BU_:  Airbag BAP_Tester ICAS1_Gateway ICAS1_KommunikationsServer LE1 LE2 Motor_BEV Schaltbetaetigung

BU_:  Airbag BAP_Tester ICAS1_Gateway ICAS1_KommunikationsServer LE1 LE2 Motor_BEV Schaltbetaetigung

BO_ 192 EM1_01: 32 LE1
 SG_ EM1_01_CRC  : 0|8@1+ (1.000000,0.000000) [0.000000|255.000000] "" ICAS1_Gateway Motor_BEV
 SG_ EM1_01_BZ  : 8|4@1+ (1.000000,0.000000) [0.000000|15.000000] "" ICAS1_Gateway Motor_BEV
 SG_ EM1_Istmodus  : 12|4@1+ (1.000000,0.000000) [0.000000|15.000000] "" ICAS1_Gateway Motor_BEV
 SG_ EM1_IstMoment  : 16|12@1+ (0.500000,-1023.000000) [-1023.000000|1023.500000] "Unit_NewtoMeter" ICAS1_Gateway Motor_BEV
 SG_ EM1_Moment_AR_Eingriff  : 28|12@1+ (0.500000,-1023.000000) [-1023.000000|1023.500000] "Unit_NewtoMeter" ICAS1_Gateway Motor_BEV
 SG_ EM1_IstDrehzahl  : 40|15@1+ (1.000000,-10000.000000) [-10000.000000|22765.000000] "Unit_MinutInver" ICAS1_Gateway Motor_BEV
 SG_ EM1_AR_aktiv  : 55|1@1+ (1.000000,0.000000) [0.000000|1.000000] "" ICAS1_Gateway Motor_BEV
 SG_ EM1_IstSpannung  : 56|12@1+ (0.250000,0.000000) [0.000000|1023.250000] "Unit_Volt" ICAS1_Gateway Motor_BEV
 SG_ EM1_Strom_HV  : 68|12@1+ (0.500000,-1023.000000) [-1023.000000|1023.500000] "Unit_Amper" ICAS1_Gateway Motor_BEV
 SG_ EM1_Max_Moment  : 80|11@1+ (1.000000,-1023.000000) [-1023.000000|1022.000000] "Unit_NewtoMeter" ICAS1_Gateway Motor_BEV
 SG_ EM1_ErwGrenzen_aktiv  : 91|1@1+ (1.000000,0.000000) [0.000000|1.000000] "" ICAS1_Gateway Motor_BEV
 SG_ EM1_Min_Moment  : 92|11@1+ (1.000000,-1023.000000) [-1023.000000|1022.000000] "Unit_NewtoMeter" ICAS1_Gateway Motor_BEV
 SG_ EM1_Fehler_ElAntriebAbschaltung  : 103|1@1+ (1.000000,0.000000) [0.000000|1.000000] "" ICAS1_Gateway Motor_BEV
 SG_ EM1_Max_Moment_Lim  : 104|11@1+ (1.000000,-1023.000000) [-1023.000000|1022.000000] "Unit_NewtoMeter" ICAS1_Gateway Motor_BEV
 SG_ EM1_Fehler_Notabschaltung  : 115|1@1+ (1.000000,0.000000) [0.000000|1.000000] "" ICAS1_Gateway Motor_BEV
 SG_ EM1_Min_Moment_Lim  : 116|11@1+ (1.000000,-1023.000000) [-1023.000000|1022.000000] "Unit_NewtoMeter" ICAS1_Gateway Motor_BEV
 SG_ EM1_Status_DrzEingriff  : 127|2@1+ (1.000000,0.000000) [0.000000|3.000000] "" ICAS1_Gateway Motor_BEV
 SG_ EM1_Mom_DrzEingriff  : 129|11@1+ (1.000000,-1023.000000) [-1023.000000|1022.000000] "Unit_NewtoMeter" ICAS1_Gateway Motor_BEV

BO_ 2463978673 EM1_02: 32 LE1
 SG_ EM1_Status_Spgfreiheit  : 12|2@1+ (1.000000,0.000000) [0.000000|3.000000] "" Motor_BEV
 SG_ EM1_Status_EoHVL  : 14|2@1+ (1.000000,0.000000) [0.000000|3.000000] "" Motor_BEV
 SG_ EM1_Max_LeistungMech_Sockel  : 16|13@1+ (200.000000,-819000.000000) [-819000.000000|818800.000000] "Unit_Watt" Vector__XXX
 SG_ EM1_Max_Moment_Sockel  : 29|11@1+ (1.000000,-1023.000000) [-1023.000000|1022.000000] "Unit_NewtoMeter" Vector__XXX
 SG_ EM1_Min_LeistungMech_Sockel  : 40|13@1+ (200.000000,-819000.000000) [-819000.000000|818800.000000] "Unit_Watt" Vector__XXX
 SG_ EM1_Min_Moment_Sockel  : 53|11@1+ (1.000000,-1023.000000) [-1023.000000|1022.000000] "Unit_NewtoMeter" Vector__XXX
 SG_ EM1_PerfInd_MaxLeistung  : 64|10@1+ (0.200000,0.000000) [0.000000|200.000000] "Unit_PerCent" Motor_BEV
 SG_ EM1_PerfInd_MaxMoment  : 74|10@1+ (0.200000,0.000000) [0.000000|200.000000] "Unit_PerCent" Motor_BEV
 SG_ EM1_AnlernenElMotor_Anf  : 84|1@1+ (1.000000,0.000000) [0.000000|1.000000] "" Motor_BEV
 SG_ EM1_OBD_Lampe_Anf  : 85|1@1+ (1.000000,0.000000) [0.000000|1.000000] "" Motor_BEV
 SG_ EM1_Generator_Moment  : 86|10@1+ (1.000000,0.000000) [0.000000|1021.000000] "Unit_NewtoMeter" Motor_BEV
 SG_ EM1_PerfInd_Temperatur  : 96|8@1+ (0.800000,0.000000) [0.000000|200.000000] "Unit_PerCent" Motor_BEV
 SG_ EM1_MaxZul_Drehzahl  : 104|8@1+ (80.000000,0.000000) [0.000000|20240.000000] "Unit_RevPerMinute" Motor_BEV
 SG_ EM1_Min_Moment_Gesamt  : 112|11@1+ (1.000000,-1023.000000) [-1023.000000|1022.000000] "Unit_NewtoMeter" Motor_BEV
 SG_ EM1_Fehlerlampe_Anf  : 123|1@1+ (1.000000,0.000000) [0.000000|1.000000] "" Motor_BEV
 SG_ EM1_Max_Moment_Gesamt  : 124|11@1+ (1.000000,-1023.000000) [-1023.000000|1022.000000] "Unit_NewtoMeter" Motor_BEV
 SG_ EM1_Warnlampe_Anf  : 135|1@1+ (1.000000,0.000000) [0.000000|1.000000] "" Motor_BEV
 SG_ EM1_Rekuperation  : 136|15@1+ (10.000000,0.000000) [0.000000|327670.000000] "Unit_WattSecond" Motor_BEV
 SG_ EM1_Rekuperation_Ueberlauf  : 151|1@1+ (1.000000,0.000000) [0.000000|1.000000] "" Motor_BEV
 SG_ EM1_Verbrauch  : 152|15@1+ (10.000000,0.000000) [0.000000|327670.000000] "Unit_WattSecond" Motor_BEV
 SG_ EM1_Verbrauch_Ueberlauf  : 167|1@1+ (1.000000,0.000000) [0.000000|1.000000] "" Motor_BEV
 SG_ EM1_Fehler_AE  : 168|1@1+ (1.000000,0.000000) [0.000000|1.000000] "" Motor_BEV
 SG_ EM1_Fehler_Leistungsred  : 169|1@1+ (1.000000,0.000000) [0.000000|1.000000] "" Motor_BEV
 SG_ EM1_Fehler_ElAntriebFreilauf  : 170|1@1+ (1.000000,0.000000) [0.000000|1.000000] "" Motor_BEV
 SG_ EM1_PWR_SollVolumenstrom  : 171|6@1+ (0.500000,0.000000) [0.000000|30.500000] "Unit_LiterPerMinut" Motor_BEV

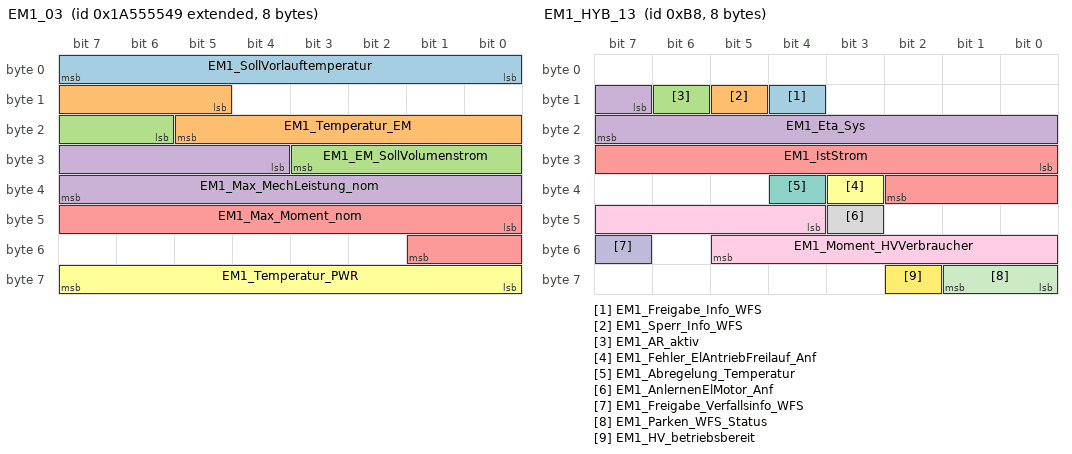
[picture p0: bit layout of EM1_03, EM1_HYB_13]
BO_ 2589283657 EM1_03: 8 LE1
 SG_ EM1_SollVorlauftemperatur  : 0|8@1+ (0.500000,-40.000000) [-40.000000|86.500000] "Unit_DegreCelsi" Motor_BEV
 SG_ EM1_Temperatur_EM  : 13|9@1+ (1.000000,-40.000000) [-40.000000|469.000000] "Unit_DegreCelsi" ICAS1_Gateway Motor_BEV
 SG_ EM1_EM_SollVolumenstrom  : 22|6@1+ (0.500000,0.000000) [0.000000|30.500000] "Unit_LiterPerMinut" Motor_BEV
 SG_ EM1_Max_MechLeistung_nom  : 28|12@1+ (200.000000,0.000000) [0.000000|818600.000000] "Unit_Watt" Motor_BEV
 SG_ EM1_Max_Moment_nom  : 40|10@1+ (1.000000,0.000000) [0.000000|1021.000000] "Unit_NewtoMeter" Motor_BEV
 SG_ EM1_Temperatur_PWR  : 56|8@1+ (1.000000,-40.000000) [-40.000000|213.000000] "Unit_DegreCelsi" ICAS1_Gateway Motor_BEV

BO_ 184 EM1_HYB_13: 8 LE1
 SG_ EM1_Freigabe_Info_WFS  : 12|1@1+ (1.000000,0.000000) [0.000000|1.000000] "" ICAS1_Gateway Motor_BEV
 SG_ EM1_Sperr_Info_WFS  : 13|1@1+ (1.000000,0.000000) [0.000000|1.000000] "" ICAS1_Gateway Motor_BEV
 SG_ EM1_AR_aktiv  : 14|1@1+ (1.000000,0.000000) [0.000000|1.000000] "" ICAS1_Gateway
 SG_ EM1_Eta_Sys  : 15|9@1+ (0.200000,0.000000) [0.000000|101.800000] "Unit_PerCent" ICAS1_Gateway
 SG_ EM1_IstStrom  : 24|11@1+ (1.000000,-1023.000000) [-1023.000000|1022.000000] "Unit_Amper" ICAS1_Gateway
 SG_ EM1_Fehler_ElAntriebFreilauf_Anf  : 35|1@1+ (1.000000,0.000000) [0.000000|1.000000] "" ICAS1_Gateway
 SG_ EM1_Abregelung_Temperatur  : 36|1@1+ (1.000000,0.000000) [0.000000|1.000000] "" ICAS1_Gateway
 SG_ EM1_AnlernenElMotor_Anf  : 43|1@1+ (1.000000,0.000000) [0.000000|1.000000] "" ICAS1_Gateway
 SG_ EM1_Moment_HVVerbraucher  : 44|10@1+ (1.000000,-511.000000) [-511.000000|511.000000] "Unit_NewtoMeter" ICAS1_Gateway
 SG_ EM1_Freigabe_Verfallsinfo_WFS  : 55|1@1+ (1.000000,0.000000) [0.000000|1.000000] "" ICAS1_Gateway Motor_BEV
 SG_ EM1_Parken_WFS_Status  : 56|2@1+ (1.000000,0.000000) [0.000000|3.000000] "" ICAS1_Gateway
 SG_ EM1_HV_betriebsbereit  : 58|1@1+ (1.000000,0.000000) [0.000000|1.000000] "" ICAS1_Gateway

BO_ 2527679712 EM1_HYB_27: 8 LE1
 SG_ EM1_RtmWarnKommunikation  : 12|3@1+ (1.000000,0.000000) [0.000000|7.000000] "" Vector__XXX
 SG_ EM1_RtmWarnUeberdrehzahl  : 15|3@1+ (1.000000,0.000000) [0.000000|7.000000] "" ICAS1_Gateway
 SG_ EM1_RtmWarnUeberstrom  : 18|3@1+ (1.000000,0.000000) [0.000000|7.000000] "" ICAS1_Gateway
 SG_ EM1_RtmWarnTempEM  : 21|3@1+ (1.000000,0.000000) [0.000000|7.000000] "" ICAS1_Gateway
 SG_ EM1_RtmWarnTempPWR  : 24|3@1+ (1.000000,0.000000) [0.000000|7.000000] "" ICAS1_Gateway

BO_ 193 EM2_01: 32 LE2
 SG_ EM2_01_CRC  : 0|8@1+ (1.000000,0.000000) [0.000000|255.000000] "" Motor_BEV
 SG_ EM2_01_BZ  : 8|4@1+ (1.000000,0.000000) [0.000000|15.000000] "" Motor_BEV
 SG_ EM2_Istmodus  : 12|4@1+ (1.000000,0.000000) [0.000000|15.000000] "" ICAS1_Gateway Motor_BEV
 SG_ EM2_IstMoment  : 16|12@1+ (0.500000,-1023.000000) [-1023.000000|1023.500000] "Unit_NewtoMeter" ICAS1_Gateway Motor_BEV
 SG_ EM2_Moment_AR_Eingriff  : 28|12@1+ (0.500000,-1023.000000) [-1023.000000|1023.500000] "Unit_NewtoMeter" Motor_BEV
 SG_ EM2_IstDrehzahl  : 40|15@1+ (1.000000,-10000.000000) [-10000.000000|22765.000000] "Unit_MinutInver" ICAS1_Gateway Motor_BEV
 SG_ EM2_AR_aktiv  : 55|1@1+ (1.000000,0.000000) [0.000000|1.000000] "" Motor_BEV
 SG_ EM2_IstSpannung  : 56|12@1+ (0.250000,0.000000) [0.000000|1023.250000] "Unit_Volt" ICAS1_Gateway Motor_BEV
 SG_ EM2_Strom_HV  : 68|12@1+ (0.500000,-1023.000000) [-1023.000000|1023.500000] "Unit_Amper" ICAS1_Gateway Motor_BEV
 SG_ EM2_Max_Moment  : 80|11@1+ (1.000000,-1023.000000) [-1023.000000|1022.000000] "Unit_NewtoMeter" Motor_BEV
 SG_ EM2_ErwGrenzen_aktiv  : 91|1@1+ (1.000000,0.000000) [0.000000|1.000000] "" Motor_BEV
 SG_ EM2_Min_Moment  : 92|11@1+ (1.000000,-1023.000000) [-1023.000000|1022.000000] "Unit_NewtoMeter" Motor_BEV
 SG_ EM2_Fehler_ElAntriebAbschaltung  : 103|1@1+ (1.000000,0.000000) [0.000000|1.000000] "" Motor_BEV
 SG_ EM2_Max_Moment_Lim  : 104|11@1+ (1.000000,-1023.000000) [-1023.000000|1022.000000] "Unit_NewtoMeter" Motor_BEV
 SG_ EM2_Fehler_Notabschaltung  : 115|1@1+ (1.000000,0.000000) [0.000000|1.000000] "" ICAS1_Gateway Motor_BEV
 SG_ EM2_Min_Moment_Lim  : 116|11@1+ (1.000000,-1023.000000) [-1023.000000|1022.000000] "Unit_NewtoMeter" Motor_BEV
 SG_ EM2_Status_DrzEingriff  : 127|2@1+ (1.000000,0.000000) [0.000000|3.000000] "" ICAS1_Gateway Motor_BEV
 SG_ EM2_Mom_DrzEingriff  : 129|11@1+ (1.000000,-1023.000000) [-1023.000000|1022.000000] "Unit_NewtoMeter" Motor_BEV

BO_ 2463978674 EM2_02: 32 LE2
 SG_ EM2_Status_Spgfreiheit  : 12|2@1+ (1.000000,0.000000) [0.000000|3.000000] "" Motor_BEV
 SG_ EM2_Status_EoHVL  : 14|2@1+ (1.000000,0.000000) [0.000000|3.000000] "" Motor_BEV
 SG_ EM2_Max_LeistungMech_Sockel  : 16|13@1+ (200.000000,-819000.000000) [-819000.000000|818800.000000] "Unit_Watt" Vector__XXX
 SG_ EM2_Max_Moment_Sockel  : 29|11@1+ (1.000000,-1023.000000) [-1023.000000|1022.000000] "Unit_NewtoMeter" Vector__XXX
 SG_ EM2_Min_LeistungMech_Sockel  : 40|13@1+ (200.000000,-819000.000000) [-819000.000000|818800.000000] "Unit_Watt" Vector__XXX
 SG_ EM2_Min_Moment_Sockel  : 53|11@1+ (1.000000,-1023.000000) [-1023.000000|1022.000000] "Unit_NewtoMeter" Vector__XXX
 SG_ EM2_PerfInd_MaxLeistung  : 64|10@1+ (0.200000,0.000000) [0.000000|200.000000] "Unit_PerCent" Motor_BEV
 SG_ EM2_PerfInd_MaxMoment  : 74|10@1+ (0.200000,0.000000) [0.000000|200.000000] "Unit_PerCent" Motor_BEV
 SG_ EM2_AnlernenElMotor_Anf  : 84|1@1+ (1.000000,0.000000) [0.000000|1.000000] "" Motor_BEV
 SG_ EM2_OBD_Lampe_Anf  : 85|1@1+ (1.000000,0.000000) [0.000000|1.000000] "" Motor_BEV
 SG_ EM2_Generator_Moment  : 86|10@1+ (1.000000,0.000000) [0.000000|1021.000000] "Unit_NewtoMeter" Motor_BEV
 SG_ EM2_PerfInd_Temperatur  : 96|8@1+ (0.800000,0.000000) [0.000000|200.000000] "Unit_PerCent" Motor_BEV
 SG_ EM2_MaxZul_Drehzahl  : 104|8@1+ (80.000000,0.000000) [0.000000|20240.000000] "Unit_RevPerMinute" Motor_BEV
 SG_ EM2_Min_Moment_Gesamt  : 112|11@1+ (1.000000,-1023.000000) [-1023.000000|1022.000000] "Unit_NewtoMeter" Motor_BEV
 SG_ EM2_Fehlerlampe_Anf  : 123|1@1+ (1.000000,0.000000) [0.000000|1.000000] "" Motor_BEV
 SG_ EM2_Max_Moment_Gesamt  : 124|11@1+ (1.000000,-1023.000000) [-1023.000000|1022.000000] "Unit_NewtoMeter" Motor_BEV
 SG_ EM2_Warnlampe_Anf  : 135|1@1+ (1.000000,0.000000) [0.000000|1.000000] "" Motor_BEV
 SG_ EM2_Rekuperation  : 136|15@1+ (10.000000,0.000000) [0.000000|327670.000000] "Unit_WattSecond" Motor_BEV
 SG_ EM2_Rekuperation_Ueberlauf  : 151|1@1+ (1.000000,0.000000) [0.000000|1.000000] "" Motor_BEV
 SG_ EM2_Verbrauch  : 152|15@1+ (10.000000,0.000000) [0.000000|327670.000000] "Unit_WattSecond" Motor_BEV
 SG_ EM2_Verbrauch_Ueberlauf  : 167|1@1+ (1.000000,0.000000) [0.000000|1.000000] "" Motor_BEV
 SG_ EM2_Fehler_AE  : 168|1@1+ (1.000000,0.000000) [0.000000|1.000000] "" Motor_BEV
 SG_ EM2_Fehler_Leistungsred  : 169|1@1+ (1.000000,0.000000) [0.000000|1.000000] "" Motor_BEV
 SG_ EM2_Fehler_ElAntriebFreilauf  : 170|1@1+ (1.000000,0.000000) [0.000000|1.000000] "" Motor_BEV
 SG_ EM2_PWR_SollVolumenstrom  : 171|6@1+ (0.500000,0.000000) [0.000000|30.500000] "Unit_LiterPerMinut" Motor_BEV

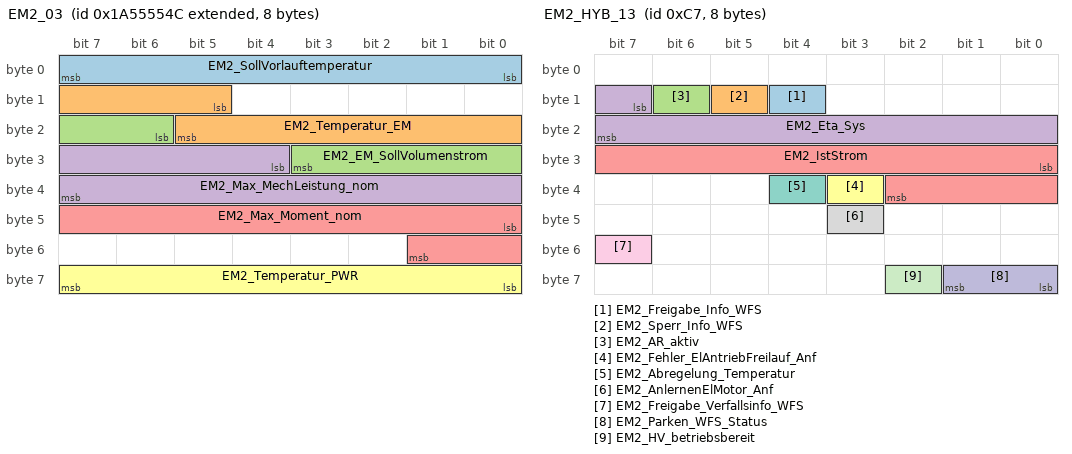
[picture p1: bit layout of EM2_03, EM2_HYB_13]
BO_ 2589283660 EM2_03: 8 LE2
 SG_ EM2_SollVorlauftemperatur  : 0|8@1+ (0.500000,-40.000000) [-40.000000|86.500000] "Unit_DegreCelsi" Motor_BEV
 SG_ EM2_Temperatur_EM  : 13|9@1+ (1.000000,-40.000000) [-40.000000|469.000000] "Unit_DegreCelsi" ICAS1_Gateway Motor_BEV
 SG_ EM2_EM_SollVolumenstrom  : 22|6@1+ (0.500000,0.000000) [0.000000|30.500000] "Unit_LiterPerMinut" Motor_BEV
 SG_ EM2_Max_MechLeistung_nom  : 28|12@1+ (200.000000,0.000000) [0.000000|818600.000000] "Unit_Watt" Motor_BEV
 SG_ EM2_Max_Moment_nom  : 40|10@1+ (1.000000,0.000000) [0.000000|1021.000000] "Unit_NewtoMeter" Motor_BEV
 SG_ EM2_Temperatur_PWR  : 56|8@1+ (1.000000,-40.000000) [-40.000000|213.000000] "Unit_DegreCelsi" ICAS1_Gateway Motor_BEV

BO_ 199 EM2_HYB_13: 8 LE2
 SG_ EM2_Freigabe_Info_WFS  : 12|1@1+ (1.000000,0.000000) [0.000000|1.000000] "" ICAS1_Gateway Motor_BEV
 SG_ EM2_Sperr_Info_WFS  : 13|1@1+ (1.000000,0.000000) [0.000000|1.000000] "" ICAS1_Gateway Motor_BEV
 SG_ EM2_AR_aktiv  : 14|1@1+ (1.000000,0.000000) [0.000000|1.000000] "" ICAS1_Gateway
 SG_ EM2_Eta_Sys  : 15|9@1+ (0.200000,0.000000) [0.000000|101.800000] "Unit_PerCent" ICAS1_Gateway
 SG_ EM2_IstStrom  : 24|11@1+ (1.000000,-1023.000000) [-1023.000000|1022.000000] "Unit_Amper" ICAS1_Gateway
 SG_ EM2_Fehler_ElAntriebFreilauf_Anf  : 35|1@1+ (1.000000,0.000000) [0.000000|1.000000] "" ICAS1_Gateway
 SG_ EM2_Abregelung_Temperatur  : 36|1@1+ (1.000000,0.000000) [0.000000|1.000000] "" ICAS1_Gateway
 SG_ EM2_AnlernenElMotor_Anf  : 43|1@1+ (1.000000,0.000000) [0.000000|1.000000] "" ICAS1_Gateway
 SG_ EM2_Freigabe_Verfallsinfo_WFS  : 55|1@1+ (1.000000,0.000000) [0.000000|1.000000] "" ICAS1_Gateway Motor_BEV
 SG_ EM2_Parken_WFS_Status  : 56|2@1+ (1.000000,0.000000) [0.000000|3.000000] "" ICAS1_Gateway
 SG_ EM2_HV_betriebsbereit  : 58|1@1+ (1.000000,0.000000) [0.000000|1.000000] "" ICAS1_Gateway

BO_ 2527679713 EM2_HYB_27: 8 LE2
 SG_ EM2_RtmWarnKommunikation  : 12|3@1+ (1.000000,0.000000) [0.000000|7.000000] "" Vector__XXX
 SG_ EM2_RtmWarnUeberdrehzahl  : 15|3@1+ (1.000000,0.000000) [0.000000|7.000000] "" ICAS1_Gateway
 SG_ EM2_RtmWarnUeberstrom  : 18|3@1+ (1.000000,0.000000) [0.000000|7.000000] "" ICAS1_Gateway
 SG_ EM2_RtmWarnTempEM  : 21|3@1+ (1.000000,0.000000) [0.000000|7.000000] "" ICAS1_Gateway
 SG_ EM2_RtmWarnTempPWR  : 24|3@1+ (1.000000,0.000000) [0.000000|7.000000] "" ICAS1_Gateway

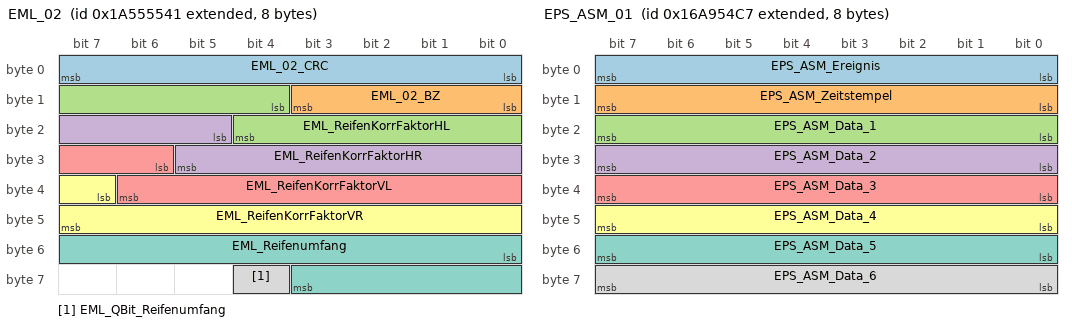
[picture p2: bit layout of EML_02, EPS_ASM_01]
BO_ 2589283649 EML_02: 8 ICAS1_Gateway
 SG_ EML_02_CRC  : 0|8@1+ (1.000000,0.000000) [0.000000|255.000000] "" Vector__XXX
 SG_ EML_02_BZ  : 8|4@1+ (1.000000,0.000000) [0.000000|15.000000] "" Vector__XXX
 SG_ EML_ReifenKorrFaktorHL  : 12|9@1+ (0.000488,0.850000) [0.850000|1.098535] "" Vector__XXX
 SG_ EML_ReifenKorrFaktorHR  : 21|9@1+ (0.000488,0.850000) [0.850000|1.098535] "" Vector__XXX
 SG_ EML_ReifenKorrFaktorVL  : 30|9@1+ (0.000488,0.850000) [0.850000|1.098535] "" Vector__XXX
 SG_ EML_ReifenKorrFaktorVR  : 39|9@1+ (0.000488,0.850000) [0.850000|1.098535] "" Vector__XXX
 SG_ EML_Reifenumfang  : 48|12@1+ (1.000000,0.000000) [0.000000|4095.000000] "Unit_MilliMeter" Motor_BEV
 SG_ EML_QBit_Reifenumfang  : 60|1@1+ (1.000000,0.000000) [0.000000|1.000000] "" Motor_BEV

BO_ 608 EML_07: 8 ICAS1_Gateway
 SG_ EML_AnzeigeGeschw  : 54|10@1+ (0.320000,0.000000) [0.000000|325.120000] "Unit_KiloMeterPerHour" Motor_BEV

BO_ 2589283751 Entfernungen_01: 8 ICAS1_KommunikationsServer
 SG_ KBI_Kilometerstand_HiRes_meter  : 32|32@1+ (1.000000,0.000000) [0.000000|4294967295.000000] "Unit_Meter" Motor_BEV

BO_ 2527679687 EPS_ASM_01: 8 ICAS1_Gateway
 SG_ EPS_ASM_Ereignis  : 0|8@1+ (1.000000,0.000000) [1.000000|254.000000] "Unit_None" Airbag
 SG_ EPS_ASM_Zeitstempel  : 8|8@1+ (0.080000,0.000000) [0.000000|20.320000] "Unit_None" Airbag
 SG_ EPS_ASM_Data_1  : 16|8@1+ (1.000000,0.000000) [0.000000|255.000000] "Unit_None" Airbag
 SG_ EPS_ASM_Data_2  : 24|8@1+ (1.000000,0.000000) [0.000000|255.000000] "Unit_None" Airbag
 SG_ EPS_ASM_Data_3  : 32|8@1+ (1.000000,0.000000) [0.000000|255.000000] "Unit_None" Airbag
 SG_ EPS_ASM_Data_4  : 40|8@1+ (1.000000,0.000000) [0.000000|255.000000] "Unit_None" Airbag
 SG_ EPS_ASM_Data_5  : 48|8@1+ (1.000000,0.000000) [0.000000|255.000000] "Unit_None" Airbag
 SG_ EPS_ASM_Data_6  : 56|8@1+ (1.000000,0.000000) [0.000000|255.000000] "Unit_None" Airbag

BO_ 258 ESC_50: 48 ICAS1_Gateway
 SG_ ESC_50_CRC  : 0|8@1+ (1.000000,0.000000) [0.000000|255.000000] "" Motor_BEV
 SG_ ESC_50_BZ  : 8|4@1+ (1.000000,0.000000) [0.000000|15.000000] "" Motor_BEV
 SG_ ESP_QBit_Gierrate  : 12|1@1+ (1.000000,0.000000) [0.000000|1.000000] "" Motor_BEV
 SG_ ESP_QBit_Laengsbeschl  : 13|1@1+ (1.000000,0.000000) [0.000000|1.000000] "" Motor_BEV
 SG_ ESP_QBit_Querb  : 14|1@1+ (1.000000,0.000000) [0.000000|1.000000] "" Motor_BEV
 SG_ ESP_Querbeschleunigung  : 16|8@1+ (0.010000,-1.270000) [-1.270000|1.270000] "Unit_ForceOfGravi" Airbag Motor_BEV
 SG_ ESP_Laengsbeschl  : 24|10@1+ (0.031250,-16.000000) [-16.000000|15.906250] "Unit_MeterPerSeconSquar" Airbag Motor_BEV
 SG_ ESC_Motorstartverzoegerung  : 34|1@1+ (1.000000,0.000000) [0.000000|1.000000] "" Vector__XXX
 SG_ ESC_SeitenwindAssistent_Eingriff  : 35|1@1+ (1.000000,0.000000) [0.000000|1.000000] "" Vector__XXX
 SG_ ESP_Anschleppstart_Freigabe  : 36|2@1+ (1.000000,0.000000) [0.000000|3.000000] "" Vector__XXX
 SG_ ESC_Unterdruckmangel_erkannt  : 38|1@1+ (1.000000,0.000000) [0.000000|1.000000] "" Vector__XXX
 SG_ ESP_Gierrate  : 40|14@1+ (0.010000,0.000000) [0.000000|163.820000] "Unit_DegreOfArcPerSecon" Airbag Motor_BEV
 SG_ ESP_VZ_Gierrate  : 54|1@1+ (1.000000,0.000000) [0.000000|1.000000] "" Airbag Motor_BEV
 SG_ ESP_Notbremsanzeige  : 55|1@1+ (1.000000,0.000000) [0.000000|1.000000] "" Vector__XXX
 SG_ ESP_SpannungsAnf  : 56|1@1+ (1.000000,0.000000) [0.000000|1.000000] "" Vector__XXX
 SG_ ESP_PLA_Abbruch  : 57|3@1+ (1.000000,0.000000) [0.000000|7.000000] "" Vector__XXX
 SG_ ESP_Status_ESP_PLA  : 60|4@1+ (1.000000,0.000000) [0.000000|15.000000] "" Vector__XXX
 SG_ ESP_QBit_Bremsdruck  : 76|1@1+ (1.000000,0.000000) [0.000000|1.000000] "" Airbag Motor_BEV
 SG_ ESP_QBit_Fahrer_bremst  : 77|1@1+ (1.000000,0.000000) [0.000000|1.000000] "" Vector__XXX
 SG_ ESP_Schwelle_Unterdruck  : 78|2@1+ (1.000000,0.000000) [0.000000|3.000000] "" Vector__XXX
 SG_ ESP_Bremsdruck  : 80|10@1+ (0.300000,-30.000000) [-30.000000|276.600000] "Unit_Bar" Motor_BEV
 SG_ ESP_Fahrer_bremst  : 90|1@1+ (1.000000,0.000000) [0.000000|1.000000] "" Vector__XXX
 SG_ ESP_Verz_TSK_aktiv  : 91|1@1+ (1.000000,0.000000) [0.000000|1.000000] "" Vector__XXX
 SG_ ESP_Lenkeingriff_ADS  : 92|1@1+ (1.000000,0.000000) [0.000000|1.000000] "" Vector__XXX
 SG_ ESP_Konsistenz_TSK  : 93|1@1+ (1.000000,0.000000) [0.000000|1.000000] "" Vector__XXX
 SG_ ESP_Bremsruck_AWV2  : 94|1@1+ (1.000000,0.000000) [0.000000|1.000000] "" Vector__XXX
 SG_ ESP_Konsistenz_AWV2  : 95|1@1+ (1.000000,0.000000) [0.000000|1.000000] "" Vector__XXX
 SG_ ECD_Fehler  : 96|1@1+ (1.000000,0.000000) [0.000000|1.000000] "" Vector__XXX
 SG_ ECD_nicht_verfuegbar  : 97|1@1+ (1.000000,0.000000) [0.000000|1.000000] "" Vector__XXX
 SG_ ESP_Status_Bremsentemp  : 98|1@1+ (1.000000,0.000000) [0.000000|1.000000] "" Vector__XXX
 SG_ ESP_Autohold_Standby  : 99|1@1+ (1.000000,0.000000) [0.000000|1.000000] "" Vector__XXX
 SG_ ESP_HDC_Standby  : 100|1@1+ (1.000000,0.000000) [0.000000|1.000000] "" Vector__XXX
 SG_ ESP_HBA_aktiv  : 101|1@1+ (1.000000,0.000000) [0.000000|1.000000] "" Vector__XXX
 SG_ ESP_Prefill_ausgeloest  : 102|1@1+ (1.000000,0.000000) [0.000000|1.000000] "" Vector__XXX
 SG_ ESP_Rueckwaertsfahrt_erkannt  : 103|1@1+ (1.000000,0.000000) [0.000000|1.000000] "" Vector__XXX
 SG_ ESP_Status_Anfahrhilfe  : 104|1@1+ (1.000000,0.000000) [0.000000|1.000000] "" Vector__XXX
 SG_ ESP_HDC_aktiv  : 105|1@1+ (1.000000,0.000000) [0.000000|1.000000] "" Vector__XXX
 SG_ ESP_StartStopp_Info  : 106|2@1+ (1.000000,0.000000) [0.000000|3.000000] "" Vector__XXX
 SG_ ESP_Eingr_HL  : 108|1@1+ (1.000000,0.000000) [0.000000|1.000000] "" Vector__XXX
 SG_ ESP_Eingr_HR  : 109|1@1+ (1.000000,0.000000) [0.000000|1.000000] "" Vector__XXX
 SG_ ESP_Eingr_VL  : 110|1@1+ (1.000000,0.000000) [0.000000|1.000000] "" Vector__XXX
 SG_ ESP_Eingr_VR  : 111|1@1+ (1.000000,0.000000) [0.000000|1.000000] "" Vector__XXX
 SG_ ESP_BKV_Unterdruck  : 112|8@1+ (4.000000,0.000000) [4.000000|1012.000000] "Unit_MilliBar" Vector__XXX
 SG_ ESP_Autohold_aktiv  : 120|1@1+ (1.000000,0.000000) [0.000000|1.000000] "" Vector__XXX
 SG_ ESP_FStatus_Anfahrhilfe  : 121|1@1+ (1.000000,0.000000) [0.000000|1.000000] "" Vector__XXX
 SG_ ESP_Verz_EPB_aktiv  : 122|1@1+ (1.000000,0.000000) [0.000000|1.000000] "" Vector__XXX
 SG_ ECD_Bremslicht  : 123|1@1+ (1.000000,0.000000) [0.000000|1.000000] "" Motor_BEV
 SG_ ESP_Verzoeg_EPB_verf  : 124|1@1+ (1.000000,0.000000) [0.000000|1.000000] "" Vector__XXX
 SG_ ESP_Status_Bremsdruck  : 125|1@1+ (1.000000,0.000000) [0.000000|1.000000] "" Vector__XXX
 SG_ ESP_Anforderung_EPB  : 126|2@1+ (1.000000,0.000000) [0.000000|3.000000] "" Vector__XXX
 SG_ ESP_ANB_CM_Rueckk_Umsetz  : 140|1@1+ (1.000000,0.000000) [0.000000|1.000000] "" Vector__XXX
 SG_ ESP_Konsistenz_ACC_Botschaft  : 141|1@1+ (1.000000,0.000000) [0.000000|1.000000] "" Vector__XXX
 SG_ ESP_Stillstandsphase_erschoepft  : 142|1@1+ (1.000000,0.000000) [0.000000|1.000000] "" Vector__XXX
 SG_ ESP_ZT_Rueckk_Umsetz  : 143|1@1+ (1.000000,0.000000) [0.000000|1.000000] "" Vector__XXX
 SG_ ESP_Tuerkontakt_Fahrertuer  : 144|1@1+ (1.000000,0.000000) [0.000000|1.000000] "" Vector__XXX
 SG_ ESP_Abrutschen_Stillstand  : 146|1@1+ (1.000000,0.000000) [0.000000|1.000000] "" Vector__XXX
 SG_ ESP_Fahrer_tritt_ZBR_Schw  : 147|1@1+ (1.000000,0.000000) [0.000000|1.000000] "" Vector__XXX
 SG_ ESP_QBit_v_ref  : 169|1@1+ (1.000000,0.000000) [0.000000|1.000000] "" Vector__XXX
 SG_ ESP_v_ref_Fahrtrichtung  : 170|2@1+ (1.000000,0.000000) [0.000000|3.000000] "" Motor_BEV
 SG_ ESC_Bremsdruckgradient  : 172|8@1+ (10.000000,0.000000) [0.000000|2500.000000] "Unit_BarPerSecon" Vector__XXX
 SG_ ESP_v_ref  : 180|12@1+ (0.125000,0.000000) [0.000000|511.500000] "Unit_KiloMeterPerHour" Airbag Motor_BEV
 SG_ ESC_Hydr_Fkt_aktiv  : 223|2@1+ (1.000000,0.000000) [0.000000|3.000000] "" Vector__XXX
 SG_ ESC_QBit_Fahrerbremswunsch  : 225|1@1+ (1.000000,0.000000) [0.000000|1.000000] "" Motor_BEV
 SG_ ESC_Fahrerbremswunsch  : 226|10@1+ (0.300000,-30.000000) [-30.000000|276.600000] "Unit_Bar" Motor_BEV
 SG_ ESCGeneratorSollMoment  : 236|12@1+ (3.000000,-12279.000000) [-12279.000000|0.000000] "" Motor_BEV
 SG_ ESC_Raddruck_max  : 248|8@1+ (1.000000,0.000000) [0.000000|250.000000] "Unit_Bar" Vector__XXX
 SG_ EPB_QBit_Pedalweg_Kuppl  : 269|1@1+ (1.000000,0.000000) [0.000000|1.000000] "" Vector__XXX
 SG_ EPB_Freig_Verzoeg_Anf  : 271|1@1+ (1.000000,0.000000) [0.000000|1.000000] "" Vector__XXX
 SG_ EPB_Verzoeg_Anf  : 272|8@1+ (0.048000,-7.968000) [-7.968000|4.224000] "Unit_MeterPerSeconSquar" Vector__XXX
 SG_ EPB_Pedalweg_Kuppl  : 288|8@1+ (0.400000,0.000000) [8.000000|92.000000] "Unit_PerCent" Vector__XXX
 SG_ EPB_DAA_Randbed_erf  : 305|1@1+ (1.000000,0.000000) [0.000000|1.000000] "" Vector__XXX
 SG_ EPB_Fehlerstatus_02  : 306|2@1+ (1.000000,0.000000) [0.000000|3.000000] "" Vector__XXX
 SG_ EPB_Schalterposition  : 308|2@1+ (1.000000,0.000000) [0.000000|3.000000] "" Airbag
 SG_ EPB_QBit_Schalterpos  : 310|1@1+ (1.000000,0.000000) [0.000000|1.000000] "" Vector__XXX
 SG_ EPB_Spannkraft  : 312|5@1+ (1.000000,0.000000) [0.000000|29.000000] "Unit_KiloNewto" Vector__XXX
 SG_ EPB_Status_02  : 317|3@1+ (1.000000,0.000000) [0.000000|7.000000] "" Motor_BEV
 SG_ EPB_Status  : 320|2@1+ (1.000000,0.000000) [0.000000|3.000000] "" Vector__XXX
 SG_ ESP_Status_Bremsentemp_02  : 322|2@1+ (1.000000,0.000000) [0.000000|3.000000] "" Motor_BEV

BU_:  Airbag BAP_Tester ICAS1_Gateway ICAS1_KommunikationsServer LE1 LE2 Motor_BEV Schaltbetaetigung

BO_ 192 EM1_01: 32 LE1
 SG_ EM1_01_CRC  : 0|8@1+ (1.000000,0.000000) [0.000000|255.000000] "" ICAS1_Gateway Motor_BEV
 SG_ EM1_01_BZ  : 8|4@1+ (1.000000,0.000000) [0.000000|15.000000] "" ICAS1_Gateway Motor_BEV
 SG_ EM1_Istmodus  : 12|4@1+ (1.000000,0.000000) [0.000000|15.000000] "" ICAS1_Gateway Motor_BEV
 SG_ EM1_IstMoment  : 16|12@1+ (0.500000,-1023.000000) [-1023.000000|1023.500000] "Unit_NewtoMeter" ICAS1_Gateway Motor_BEV
 SG_ EM1_Moment_AR_Eingriff  : 28|12@1+ (0.500000,-1023.000000) [-1023.000000|1023.500000] "Unit_NewtoMeter" ICAS1_Gateway Motor_BEV
 SG_ EM1_IstDrehzahl  : 40|15@1+ (1.000000,-10000.000000) [-10000.000000|22765.000000] "Unit_MinutInver" ICAS1_Gateway Motor_BEV
 SG_ EM1_AR_aktiv  : 55|1@1+ (1.000000,0.000000) [0.000000|1.000000] "" ICAS1_Gateway Motor_BEV
 SG_ EM1_IstSpannung  : 56|12@1+ (0.250000,0.000000) [0.000000|1023.250000] "Unit_Volt" ICAS1_Gateway Motor_BEV
 SG_ EM1_Strom_HV  : 68|12@1+ (0.500000,-1023.000000) [-1023.000000|1023.500000] "Unit_Amper" ICAS1_Gateway Motor_BEV
 SG_ EM1_Max_Moment  : 80|11@1+ (1.000000,-1023.000000) [-1023.000000|1022.000000] "Unit_NewtoMeter" ICAS1_Gateway Motor_BEV
 SG_ EM1_ErwGrenzen_aktiv  : 91|1@1+ (1.000000,0.000000) [0.000000|1.000000] "" ICAS1_Gateway Motor_BEV
 SG_ EM1_Min_Moment  : 92|11@1+ (1.000000,-1023.000000) [-1023.000000|1022.000000] "Unit_NewtoMeter" ICAS1_Gateway Motor_BEV
 SG_ EM1_Fehler_ElAntriebAbschaltung  : 103|1@1+ (1.000000,0.000000) [0.000000|1.000000] "" ICAS1_Gateway Motor_BEV
 SG_ EM1_Max_Moment_Lim  : 104|11@1+ (1.000000,-1023.000000) [-1023.000000|1022.000000] "Unit_NewtoMeter" ICAS1_Gateway Motor_BEV
 SG_ EM1_Fehler_Notabschaltung  : 115|1@1+ (1.000000,0.000000) [0.000000|1.000000] "" ICAS1_Gateway Motor_BEV
 SG_ EM1_Min_Moment_Lim  : 116|11@1+ (1.000000,-1023.000000) [-1023.000000|1022.000000] "Unit_NewtoMeter" ICAS1_Gateway Motor_BEV
 SG_ EM1_Status_DrzEingriff  : 127|2@1+ (1.000000,0.000000) [0.000000|3.000000] "" ICAS1_Gateway Motor_BEV
 SG_ EM1_Mom_DrzEingriff  : 129|11@1+ (1.000000,-1023.000000) [-1023.000000|1022.000000] "Unit_NewtoMeter" ICAS1_Gateway Motor_BEV

BO_ 2463978673 EM1_02: 32 LE1
 SG_ EM1_Status_Spgfreiheit  : 12|2@1+ (1.000000,0.000000) [0.000000|3.000000] "" Motor_BEV
 SG_ EM1_Status_EoHVL  : 14|2@1+ (1.000000,0.000000) [0.000000|3.000000] "" Motor_BEV
 SG_ EM1_Max_LeistungMech_Sockel  : 16|13@1+ (200.000000,-819000.000000) [-819000.000000|818800.000000] "Unit_Watt" Vector__XXX
 SG_ EM1_Max_Moment_Sockel  : 29|11@1+ (1.000000,-1023.000000) [-1023.000000|1022.000000] "Unit_NewtoMeter" Vector__XXX
 SG_ EM1_Min_LeistungMech_Sockel  : 40|13@1+ (200.000000,-819000.000000) [-819000.000000|818800.000000] "Unit_Watt" Vector__XXX
 SG_ EM1_Min_Moment_Sockel  : 53|11@1+ (1.000000,-1023.000000) [-1023.000000|1022.000000] "Unit_NewtoMeter" Vector__XXX
 SG_ EM1_PerfInd_MaxLeistung  : 64|10@1+ (0.200000,0.000000) [0.000000|200.000000] "Unit_PerCent" Motor_BEV
 SG_ EM1_PerfInd_MaxMoment  : 74|10@1+ (0.200000,0.000000) [0.000000|200.000000] "Unit_PerCent" Motor_BEV
 SG_ EM1_AnlernenElMotor_Anf  : 84|1@1+ (1.000000,0.000000) [0.000000|1.000000] "" Motor_BEV
 SG_ EM1_OBD_Lampe_Anf  : 85|1@1+ (1.000000,0.000000) [0.000000|1.000000] "" Motor_BEV
 SG_ EM1_Generator_Moment  : 86|10@1+ (1.000000,0.000000) [0.000000|1021.000000] "Unit_NewtoMeter" Motor_BEV
 SG_ EM1_PerfInd_Temperatur  : 96|8@1+ (0.800000,0.000000) [0.000000|200.000000] "Unit_PerCent" Motor_BEV
 SG_ EM1_MaxZul_Drehzahl  : 104|8@1+ (80.000000,0.000000) [0.000000|20240.000000] "Unit_RevPerMinute" Motor_BEV
 SG_ EM1_Min_Moment_Gesamt  : 112|11@1+ (1.000000,-1023.000000) [-1023.000000|1022.000000] "Unit_NewtoMeter" Motor_BEV
 SG_ EM1_Fehlerlampe_Anf  : 123|1@1+ (1.000000,0.000000) [0.000000|1.000000] "" Motor_BEV
 SG_ EM1_Max_Moment_Gesamt  : 124|11@1+ (1.000000,-1023.000000) [-1023.000000|1022.000000] "Unit_NewtoMeter" Motor_BEV
 SG_ EM1_Warnlampe_Anf  : 135|1@1+ (1.000000,0.000000) [0.000000|1.000000] "" Motor_BEV
 SG_ EM1_Rekuperation  : 136|15@1+ (10.000000,0.000000) [0.000000|327670.000000] "Unit_WattSecond" Motor_BEV
 SG_ EM1_Rekuperation_Ueberlauf  : 151|1@1+ (1.000000,0.000000) [0.000000|1.000000] "" Motor_BEV
 SG_ EM1_Verbrauch  : 152|15@1+ (10.000000,0.000000) [0.000000|327670.000000] "Unit_WattSecond" Motor_BEV
 SG_ EM1_Verbrauch_Ueberlauf  : 167|1@1+ (1.000000,0.000000) [0.000000|1.000000] "" Motor_BEV
 SG_ EM1_Fehler_AE  : 168|1@1+ (1.000000,0.000000) [0.000000|1.000000] "" Motor_BEV
 SG_ EM1_Fehler_Leistungsred  : 169|1@1+ (1.000000,0.000000) [0.000000|1.000000] "" Motor_BEV
 SG_ EM1_Fehler_ElAntriebFreilauf  : 170|1@1+ (1.000000,0.000000) [0.000000|1.000000] "" Motor_BEV
 SG_ EM1_PWR_SollVolumenstrom  : 171|6@1+ (0.500000,0.000000) [0.000000|30.500000] "Unit_LiterPerMinut" Motor_BEV

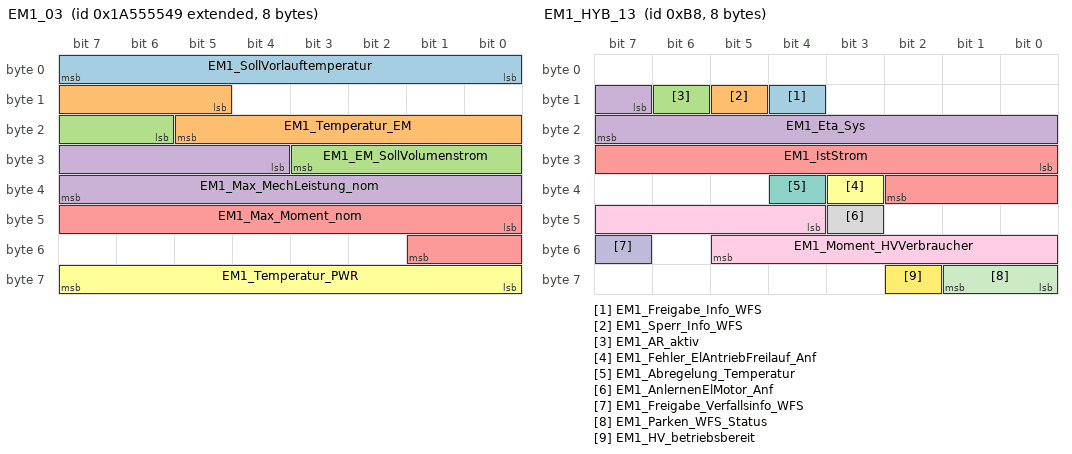
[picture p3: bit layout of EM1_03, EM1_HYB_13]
BO_ 2589283657 EM1_03: 8 LE1
 SG_ EM1_SollVorlauftemperatur  : 0|8@1+ (0.500000,-40.000000) [-40.000000|86.500000] "Unit_DegreCelsi" Motor_BEV
 SG_ EM1_Temperatur_EM  : 13|9@1+ (1.000000,-40.000000) [-40.000000|469.000000] "Unit_DegreCelsi" ICAS1_Gateway Motor_BEV
 SG_ EM1_EM_SollVolumenstrom  : 22|6@1+ (0.500000,0.000000) [0.000000|30.500000] "Unit_LiterPerMinut" Motor_BEV
 SG_ EM1_Max_MechLeistung_nom  : 28|12@1+ (200.000000,0.000000) [0.000000|818600.000000] "Unit_Watt" Motor_BEV
 SG_ EM1_Max_Moment_nom  : 40|10@1+ (1.000000,0.000000) [0.000000|1021.000000] "Unit_NewtoMeter" Motor_BEV
 SG_ EM1_Temperatur_PWR  : 56|8@1+ (1.000000,-40.000000) [-40.000000|213.000000] "Unit_DegreCelsi" ICAS1_Gateway Motor_BEV

BO_ 184 EM1_HYB_13: 8 LE1
 SG_ EM1_Freigabe_Info_WFS  : 12|1@1+ (1.000000,0.000000) [0.000000|1.000000] "" ICAS1_Gateway Motor_BEV
 SG_ EM1_Sperr_Info_WFS  : 13|1@1+ (1.000000,0.000000) [0.000000|1.000000] "" ICAS1_Gateway Motor_BEV
 SG_ EM1_AR_aktiv  : 14|1@1+ (1.000000,0.000000) [0.000000|1.000000] "" ICAS1_Gateway
 SG_ EM1_Eta_Sys  : 15|9@1+ (0.200000,0.000000) [0.000000|101.800000] "Unit_PerCent" ICAS1_Gateway
 SG_ EM1_IstStrom  : 24|11@1+ (1.000000,-1023.000000) [-1023.000000|1022.000000] "Unit_Amper" ICAS1_Gateway
 SG_ EM1_Fehler_ElAntriebFreilauf_Anf  : 35|1@1+ (1.000000,0.000000) [0.000000|1.000000] "" ICAS1_Gateway
 SG_ EM1_Abregelung_Temperatur  : 36|1@1+ (1.000000,0.000000) [0.000000|1.000000] "" ICAS1_Gateway
 SG_ EM1_AnlernenElMotor_Anf  : 43|1@1+ (1.000000,0.000000) [0.000000|1.000000] "" ICAS1_Gateway
 SG_ EM1_Moment_HVVerbraucher  : 44|10@1+ (1.000000,-511.000000) [-511.000000|511.000000] "Unit_NewtoMeter" ICAS1_Gateway
 SG_ EM1_Freigabe_Verfallsinfo_WFS  : 55|1@1+ (1.000000,0.000000) [0.000000|1.000000] "" ICAS1_Gateway Motor_BEV
 SG_ EM1_Parken_WFS_Status  : 56|2@1+ (1.000000,0.000000) [0.000000|3.000000] "" ICAS1_Gateway
 SG_ EM1_HV_betriebsbereit  : 58|1@1+ (1.000000,0.000000) [0.000000|1.000000] "" ICAS1_Gateway

BO_ 2527679712 EM1_HYB_27: 8 LE1
 SG_ EM1_RtmWarnKommunikation  : 12|3@1+ (1.000000,0.000000) [0.000000|7.000000] "" Vector__XXX
 SG_ EM1_RtmWarnUeberdrehzahl  : 15|3@1+ (1.000000,0.000000) [0.000000|7.000000] "" ICAS1_Gateway
 SG_ EM1_RtmWarnUeberstrom  : 18|3@1+ (1.000000,0.000000) [0.000000|7.000000] "" ICAS1_Gateway
 SG_ EM1_RtmWarnTempEM  : 21|3@1+ (1.000000,0.000000) [0.000000|7.000000] "" ICAS1_Gateway
 SG_ EM1_RtmWarnTempPWR  : 24|3@1+ (1.000000,0.000000) [0.000000|7.000000] "" ICAS1_Gateway

BO_ 193 EM2_01: 32 LE2
 SG_ EM2_01_CRC  : 0|8@1+ (1.000000,0.000000) [0.000000|255.000000] "" Motor_BEV
 SG_ EM2_01_BZ  : 8|4@1+ (1.000000,0.000000) [0.000000|15.000000] "" Motor_BEV
 SG_ EM2_Istmodus  : 12|4@1+ (1.000000,0.000000) [0.000000|15.000000] "" ICAS1_Gateway Motor_BEV
 SG_ EM2_IstMoment  : 16|12@1+ (0.500000,-1023.000000) [-1023.000000|1023.500000] "Unit_NewtoMeter" ICAS1_Gateway Motor_BEV
 SG_ EM2_Moment_AR_Eingriff  : 28|12@1+ (0.500000,-1023.000000) [-1023.000000|1023.500000] "Unit_NewtoMeter" Motor_BEV
 SG_ EM2_IstDrehzahl  : 40|15@1+ (1.000000,-10000.000000) [-10000.000000|22765.000000] "Unit_MinutInver" ICAS1_Gateway Motor_BEV
 SG_ EM2_AR_aktiv  : 55|1@1+ (1.000000,0.000000) [0.000000|1.000000] "" Motor_BEV
 SG_ EM2_IstSpannung  : 56|12@1+ (0.250000,0.000000) [0.000000|1023.250000] "Unit_Volt" ICAS1_Gateway Motor_BEV
 SG_ EM2_Strom_HV  : 68|12@1+ (0.500000,-1023.000000) [-1023.000000|1023.500000] "Unit_Amper" ICAS1_Gateway Motor_BEV
 SG_ EM2_Max_Moment  : 80|11@1+ (1.000000,-1023.000000) [-1023.000000|1022.000000] "Unit_NewtoMeter" Motor_BEV
 SG_ EM2_ErwGrenzen_aktiv  : 91|1@1+ (1.000000,0.000000) [0.000000|1.000000] "" Motor_BEV
 SG_ EM2_Min_Moment  : 92|11@1+ (1.000000,-1023.000000) [-1023.000000|1022.000000] "Unit_NewtoMeter" Motor_BEV
 SG_ EM2_Fehler_ElAntriebAbschaltung  : 103|1@1+ (1.000000,0.000000) [0.000000|1.000000] "" Motor_BEV
 SG_ EM2_Max_Moment_Lim  : 104|11@1+ (1.000000,-1023.000000) [-1023.000000|1022.000000] "Unit_NewtoMeter" Motor_BEV
 SG_ EM2_Fehler_Notabschaltung  : 115|1@1+ (1.000000,0.000000) [0.000000|1.000000] "" ICAS1_Gateway Motor_BEV
 SG_ EM2_Min_Moment_Lim  : 116|11@1+ (1.000000,-1023.000000) [-1023.000000|1022.000000] "Unit_NewtoMeter" Motor_BEV
 SG_ EM2_Status_DrzEingriff  : 127|2@1+ (1.000000,0.000000) [0.000000|3.000000] "" ICAS1_Gateway Motor_BEV
 SG_ EM2_Mom_DrzEingriff  : 129|11@1+ (1.000000,-1023.000000) [-1023.000000|1022.000000] "Unit_NewtoMeter" Motor_BEV

BO_ 2463978674 EM2_02: 32 LE2
 SG_ EM2_Status_Spgfreiheit  : 12|2@1+ (1.000000,0.000000) [0.000000|3.000000] "" Motor_BEV
 SG_ EM2_Status_EoHVL  : 14|2@1+ (1.000000,0.000000) [0.000000|3.000000] "" Motor_BEV
 SG_ EM2_Max_LeistungMech_Sockel  : 16|13@1+ (200.000000,-819000.000000) [-819000.000000|818800.000000] "Unit_Watt" Vector__XXX
 SG_ EM2_Max_Moment_Sockel  : 29|11@1+ (1.000000,-1023.000000) [-1023.000000|1022.000000] "Unit_NewtoMeter" Vector__XXX
 SG_ EM2_Min_LeistungMech_Sockel  : 40|13@1+ (200.000000,-819000.000000) [-819000.000000|818800.000000] "Unit_Watt" Vector__XXX
 SG_ EM2_Min_Moment_Sockel  : 53|11@1+ (1.000000,-1023.000000) [-1023.000000|1022.000000] "Unit_NewtoMeter" Vector__XXX
 SG_ EM2_PerfInd_MaxLeistung  : 64|10@1+ (0.200000,0.000000) [0.000000|200.000000] "Unit_PerCent" Motor_BEV
 SG_ EM2_PerfInd_MaxMoment  : 74|10@1+ (0.200000,0.000000) [0.000000|200.000000] "Unit_PerCent" Motor_BEV
 SG_ EM2_AnlernenElMotor_Anf  : 84|1@1+ (1.000000,0.000000) [0.000000|1.000000] "" Motor_BEV
 SG_ EM2_OBD_Lampe_Anf  : 85|1@1+ (1.000000,0.000000) [0.000000|1.000000] "" Motor_BEV
 SG_ EM2_Generator_Moment  : 86|10@1+ (1.000000,0.000000) [0.000000|1021.000000] "Unit_NewtoMeter" Motor_BEV
 SG_ EM2_PerfInd_Temperatur  : 96|8@1+ (0.800000,0.000000) [0.000000|200.000000] "Unit_PerCent" Motor_BEV
 SG_ EM2_MaxZul_Drehzahl  : 104|8@1+ (80.000000,0.000000) [0.000000|20240.000000] "Unit_RevPerMinute" Motor_BEV
 SG_ EM2_Min_Moment_Gesamt  : 112|11@1+ (1.000000,-1023.000000) [-1023.000000|1022.000000] "Unit_NewtoMeter" Motor_BEV
 SG_ EM2_Fehlerlampe_Anf  : 123|1@1+ (1.000000,0.000000) [0.000000|1.000000] "" Motor_BEV
 SG_ EM2_Max_Moment_Gesamt  : 124|11@1+ (1.000000,-1023.000000) [-1023.000000|1022.000000] "Unit_NewtoMeter" Motor_BEV
 SG_ EM2_Warnlampe_Anf  : 135|1@1+ (1.000000,0.000000) [0.000000|1.000000] "" Motor_BEV
 SG_ EM2_Rekuperation  : 136|15@1+ (10.000000,0.000000) [0.000000|327670.000000] "Unit_WattSecond" Motor_BEV
 SG_ EM2_Rekuperation_Ueberlauf  : 151|1@1+ (1.000000,0.000000) [0.000000|1.000000] "" Motor_BEV
 SG_ EM2_Verbrauch  : 152|15@1+ (10.000000,0.000000) [0.000000|327670.000000] "Unit_WattSecond" Motor_BEV
 SG_ EM2_Verbrauch_Ueberlauf  : 167|1@1+ (1.000000,0.000000) [0.000000|1.000000] "" Motor_BEV
 SG_ EM2_Fehler_AE  : 168|1@1+ (1.000000,0.000000) [0.000000|1.000000] "" Motor_BEV
 SG_ EM2_Fehler_Leistungsred  : 169|1@1+ (1.000000,0.000000) [0.000000|1.000000] "" Motor_BEV
 SG_ EM2_Fehler_ElAntriebFreilauf  : 170|1@1+ (1.000000,0.000000) [0.000000|1.000000] "" Motor_BEV
 SG_ EM2_PWR_SollVolumenstrom  : 171|6@1+ (0.500000,0.000000) [0.000000|30.500000] "Unit_LiterPerMinut" Motor_BEV

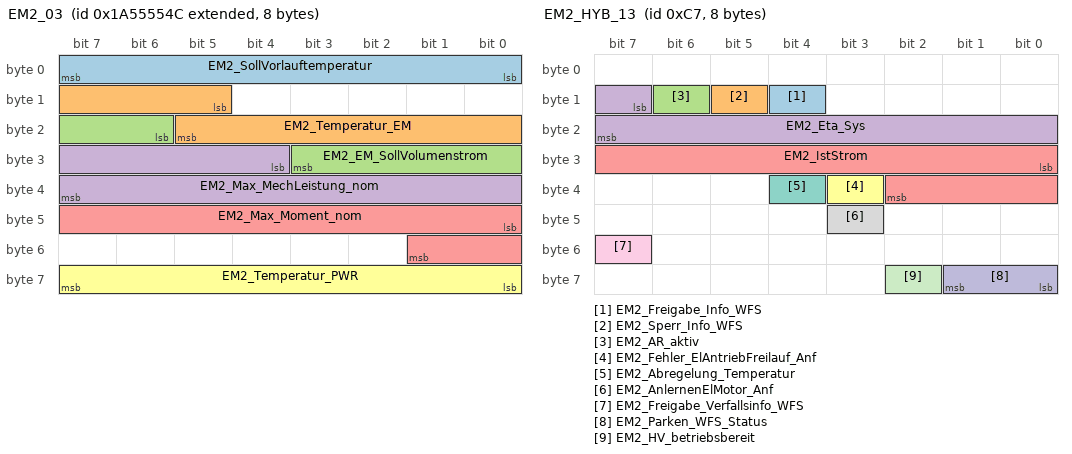
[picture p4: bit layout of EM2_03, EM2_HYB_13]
BO_ 2589283660 EM2_03: 8 LE2
 SG_ EM2_SollVorlauftemperatur  : 0|8@1+ (0.500000,-40.000000) [-40.000000|86.500000] "Unit_DegreCelsi" Motor_BEV
 SG_ EM2_Temperatur_EM  : 13|9@1+ (1.000000,-40.000000) [-40.000000|469.000000] "Unit_DegreCelsi" ICAS1_Gateway Motor_BEV
 SG_ EM2_EM_SollVolumenstrom  : 22|6@1+ (0.500000,0.000000) [0.000000|30.500000] "Unit_LiterPerMinut" Motor_BEV
 SG_ EM2_Max_MechLeistung_nom  : 28|12@1+ (200.000000,0.000000) [0.000000|818600.000000] "Unit_Watt" Motor_BEV
 SG_ EM2_Max_Moment_nom  : 40|10@1+ (1.000000,0.000000) [0.000000|1021.000000] "Unit_NewtoMeter" Motor_BEV
 SG_ EM2_Temperatur_PWR  : 56|8@1+ (1.000000,-40.000000) [-40.000000|213.000000] "Unit_DegreCelsi" ICAS1_Gateway Motor_BEV

BO_ 199 EM2_HYB_13: 8 LE2
 SG_ EM2_Freigabe_Info_WFS  : 12|1@1+ (1.000000,0.000000) [0.000000|1.000000] "" ICAS1_Gateway Motor_BEV
 SG_ EM2_Sperr_Info_WFS  : 13|1@1+ (1.000000,0.000000) [0.000000|1.000000] "" ICAS1_Gateway Motor_BEV
 SG_ EM2_AR_aktiv  : 14|1@1+ (1.000000,0.000000) [0.000000|1.000000] "" ICAS1_Gateway
 SG_ EM2_Eta_Sys  : 15|9@1+ (0.200000,0.000000) [0.000000|101.800000] "Unit_PerCent" ICAS1_Gateway
 SG_ EM2_IstStrom  : 24|11@1+ (1.000000,-1023.000000) [-1023.000000|1022.000000] "Unit_Amper" ICAS1_Gateway
 SG_ EM2_Fehler_ElAntriebFreilauf_Anf  : 35|1@1+ (1.000000,0.000000) [0.000000|1.000000] "" ICAS1_Gateway
 SG_ EM2_Abregelung_Temperatur  : 36|1@1+ (1.000000,0.000000) [0.000000|1.000000] "" ICAS1_Gateway
 SG_ EM2_AnlernenElMotor_Anf  : 43|1@1+ (1.000000,0.000000) [0.000000|1.000000] "" ICAS1_Gateway
 SG_ EM2_Freigabe_Verfallsinfo_WFS  : 55|1@1+ (1.000000,0.000000) [0.000000|1.000000] "" ICAS1_Gateway Motor_BEV
 SG_ EM2_Parken_WFS_Status  : 56|2@1+ (1.000000,0.000000) [0.000000|3.000000] "" ICAS1_Gateway
 SG_ EM2_HV_betriebsbereit  : 58|1@1+ (1.000000,0.000000) [0.000000|1.000000] "" ICAS1_Gateway

BO_ 2527679713 EM2_HYB_27: 8 LE2
 SG_ EM2_RtmWarnKommunikation  : 12|3@1+ (1.000000,0.000000) [0.000000|7.000000] "" Vector__XXX
 SG_ EM2_RtmWarnUeberdrehzahl  : 15|3@1+ (1.000000,0.000000) [0.000000|7.000000] "" ICAS1_Gateway
 SG_ EM2_RtmWarnUeberstrom  : 18|3@1+ (1.000000,0.000000) [0.000000|7.000000] "" ICAS1_Gateway
 SG_ EM2_RtmWarnTempEM  : 21|3@1+ (1.000000,0.000000) [0.000000|7.000000] "" ICAS1_Gateway
 SG_ EM2_RtmWarnTempPWR  : 24|3@1+ (1.000000,0.000000) [0.000000|7.000000] "" ICAS1_Gateway

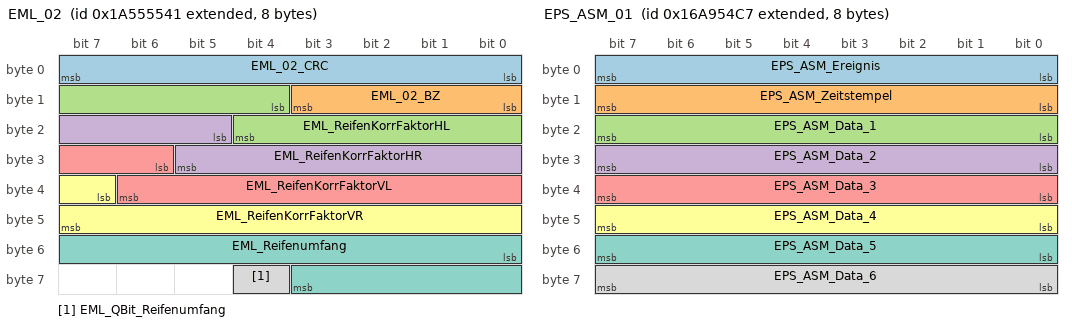
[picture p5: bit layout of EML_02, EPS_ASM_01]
BO_ 2589283649 EML_02: 8 ICAS1_Gateway
 SG_ EML_02_CRC  : 0|8@1+ (1.000000,0.000000) [0.000000|255.000000] "" Vector__XXX
 SG_ EML_02_BZ  : 8|4@1+ (1.000000,0.000000) [0.000000|15.000000] "" Vector__XXX
 SG_ EML_ReifenKorrFaktorHL  : 12|9@1+ (0.000488,0.850000) [0.850000|1.098535] "" Vector__XXX
 SG_ EML_ReifenKorrFaktorHR  : 21|9@1+ (0.000488,0.850000) [0.850000|1.098535] "" Vector__XXX
 SG_ EML_ReifenKorrFaktorVL  : 30|9@1+ (0.000488,0.850000) [0.850000|1.098535] "" Vector__XXX
 SG_ EML_ReifenKorrFaktorVR  : 39|9@1+ (0.000488,0.850000) [0.850000|1.098535] "" Vector__XXX
 SG_ EML_Reifenumfang  : 48|12@1+ (1.000000,0.000000) [0.000000|4095.000000] "Unit_MilliMeter" Motor_BEV
 SG_ EML_QBit_Reifenumfang  : 60|1@1+ (1.000000,0.000000) [0.000000|1.000000] "" Motor_BEV

BO_ 608 EML_07: 8 ICAS1_Gateway
 SG_ EML_AnzeigeGeschw  : 54|10@1+ (0.320000,0.000000) [0.000000|325.120000] "Unit_KiloMeterPerHour" Motor_BEV

BO_ 2589283751 Entfernungen_01: 8 ICAS1_KommunikationsServer
 SG_ KBI_Kilometerstand_HiRes_meter  : 32|32@1+ (1.000000,0.000000) [0.000000|4294967295.000000] "Unit_Meter" Motor_BEV

BO_ 2527679687 EPS_ASM_01: 8 ICAS1_Gateway
 SG_ EPS_ASM_Ereignis  : 0|8@1+ (1.000000,0.000000) [1.000000|254.000000] "Unit_None" Airbag
 SG_ EPS_ASM_Zeitstempel  : 8|8@1+ (0.080000,0.000000) [0.000000|20.320000] "Unit_None" Airbag
 SG_ EPS_ASM_Data_1  : 16|8@1+ (1.000000,0.000000) [0.000000|255.000000] "Unit_None" Airbag
 SG_ EPS_ASM_Data_2  : 24|8@1+ (1.000000,0.000000) [0.000000|255.000000] "Unit_None" Airbag
 SG_ EPS_ASM_Data_3  : 32|8@1+ (1.000000,0.000000) [0.000000|255.000000] "Unit_None" Airbag
 SG_ EPS_ASM_Data_4  : 40|8@1+ (1.000000,0.000000) [0.000000|255.000000] "Unit_None" Airbag
 SG_ EPS_ASM_Data_5  : 48|8@1+ (1.000000,0.000000) [0.000000|255.000000] "Unit_None" Airbag
 SG_ EPS_ASM_Data_6  : 56|8@1+ (1.000000,0.000000) [0.000000|255.000000] "Unit_None" Airbag

BO_ 258 ESC_50: 48 ICAS1_Gateway
 SG_ ESC_50_CRC  : 0|8@1+ (1.000000,0.000000) [0.000000|255.000000] "" Motor_BEV
 SG_ ESC_50_BZ  : 8|4@1+ (1.000000,0.000000) [0.000000|15.000000] "" Motor_BEV
 SG_ ESP_QBit_Gierrate  : 12|1@1+ (1.000000,0.000000) [0.000000|1.000000] "" Motor_BEV
 SG_ ESP_QBit_Laengsbeschl  : 13|1@1+ (1.000000,0.000000) [0.000000|1.000000] "" Motor_BEV
 SG_ ESP_QBit_Querb  : 14|1@1+ (1.000000,0.000000) [0.000000|1.000000] "" Motor_BEV
 SG_ ESP_Querbeschleunigung  : 16|8@1+ (0.010000,-1.270000) [-1.270000|1.270000] "Unit_ForceOfGravi" Airbag Motor_BEV
 SG_ ESP_Laengsbeschl  : 24|10@1+ (0.031250,-16.000000) [-16.000000|15.906250] "Unit_MeterPerSeconSquar" Airbag Motor_BEV
 SG_ ESC_Motorstartverzoegerung  : 34|1@1+ (1.000000,0.000000) [0.000000|1.000000] "" Vector__XXX
 SG_ ESC_SeitenwindAssistent_Eingriff  : 35|1@1+ (1.000000,0.000000) [0.000000|1.000000] "" Vector__XXX
 SG_ ESP_Anschleppstart_Freigabe  : 36|2@1+ (1.000000,0.000000) [0.000000|3.000000] "" Vector__XXX
 SG_ ESC_Unterdruckmangel_erkannt  : 38|1@1+ (1.000000,0.000000) [0.000000|1.000000] "" Vector__XXX
 SG_ ESP_Gierrate  : 40|14@1+ (0.010000,0.000000) [0.000000|163.820000] "Unit_DegreOfArcPerSecon" Airbag Motor_BEV
 SG_ ESP_VZ_Gierrate  : 54|1@1+ (1.000000,0.000000) [0.000000|1.000000] "" Airbag Motor_BEV
 SG_ ESP_Notbremsanzeige  : 55|1@1+ (1.000000,0.000000) [0.000000|1.000000] "" Vector__XXX
 SG_ ESP_SpannungsAnf  : 56|1@1+ (1.000000,0.000000) [0.000000|1.000000] "" Vector__XXX
 SG_ ESP_PLA_Abbruch  : 57|3@1+ (1.000000,0.000000) [0.000000|7.000000] "" Vector__XXX
 SG_ ESP_Status_ESP_PLA  : 60|4@1+ (1.000000,0.000000) [0.000000|15.000000] "" Vector__XXX
 SG_ ESP_QBit_Bremsdruck  : 76|1@1+ (1.000000,0.000000) [0.000000|1.000000] "" Airbag Motor_BEV
 SG_ ESP_QBit_Fahrer_bremst  : 77|1@1+ (1.000000,0.000000) [0.000000|1.000000] "" Vector__XXX
 SG_ ESP_Schwelle_Unterdruck  : 78|2@1+ (1.000000,0.000000) [0.000000|3.000000] "" Vector__XXX
 SG_ ESP_Bremsdruck  : 80|10@1+ (0.300000,-30.000000) [-30.000000|276.600000] "Unit_Bar" Motor_BEV
 SG_ ESP_Fahrer_bremst  : 90|1@1+ (1.000000,0.000000) [0.000000|1.000000] "" Vector__XXX
 SG_ ESP_Verz_TSK_aktiv  : 91|1@1+ (1.000000,0.000000) [0.000000|1.000000] "" Vector__XXX
 SG_ ESP_Lenkeingriff_ADS  : 92|1@1+ (1.000000,0.000000) [0.000000|1.000000] "" Vector__XXX
 SG_ ESP_Konsistenz_TSK  : 93|1@1+ (1.000000,0.000000) [0.000000|1.000000] "" Vector__XXX
 SG_ ESP_Bremsruck_AWV2  : 94|1@1+ (1.000000,0.000000) [0.000000|1.000000] "" Vector__XXX
 SG_ ESP_Konsistenz_AWV2  : 95|1@1+ (1.000000,0.000000) [0.000000|1.000000] "" Vector__XXX
 SG_ ECD_Fehler  : 96|1@1+ (1.000000,0.000000) [0.000000|1.000000] "" Vector__XXX
 SG_ ECD_nicht_verfuegbar  : 97|1@1+ (1.000000,0.000000) [0.000000|1.000000] "" Vector__XXX
 SG_ ESP_Status_Bremsentemp  : 98|1@1+ (1.000000,0.000000) [0.000000|1.000000] "" Vector__XXX
 SG_ ESP_Autohold_Standby  : 99|1@1+ (1.000000,0.000000) [0.000000|1.000000] "" Vector__XXX
 SG_ ESP_HDC_Standby  : 100|1@1+ (1.000000,0.000000) [0.000000|1.000000] "" Vector__XXX
 SG_ ESP_HBA_aktiv  : 101|1@1+ (1.000000,0.000000) [0.000000|1.000000] "" Vector__XXX
 SG_ ESP_Prefill_ausgeloest  : 102|1@1+ (1.000000,0.000000) [0.000000|1.000000] "" Vector__XXX
 SG_ ESP_Rueckwaertsfahrt_erkannt  : 103|1@1+ (1.000000,0.000000) [0.000000|1.000000] "" Vector__XXX
 SG_ ESP_Status_Anfahrhilfe  : 104|1@1+ (1.000000,0.000000) [0.000000|1.000000] "" Vector__XXX
 SG_ ESP_HDC_aktiv  : 105|1@1+ (1.000000,0.000000) [0.000000|1.000000] "" Vector__XXX
 SG_ ESP_StartStopp_Info  : 106|2@1+ (1.000000,0.000000) [0.000000|3.000000] "" Vector__XXX
 SG_ ESP_Eingr_HL  : 108|1@1+ (1.000000,0.000000) [0.000000|1.000000] "" Vector__XXX
 SG_ ESP_Eingr_HR  : 109|1@1+ (1.000000,0.000000) [0.000000|1.000000] "" Vector__XXX
 SG_ ESP_Eingr_VL  : 110|1@1+ (1.000000,0.000000) [0.000000|1.000000] "" Vector__XXX
 SG_ ESP_Eingr_VR  : 111|1@1+ (1.000000,0.000000) [0.000000|1.000000] "" Vector__XXX
 SG_ ESP_BKV_Unterdruck  : 112|8@1+ (4.000000,0.000000) [4.000000|1012.000000] "Unit_MilliBar" Vector__XXX
 SG_ ESP_Autohold_aktiv  : 120|1@1+ (1.000000,0.000000) [0.000000|1.000000] "" Vector__XXX
 SG_ ESP_FStatus_Anfahrhilfe  : 121|1@1+ (1.000000,0.000000) [0.000000|1.000000] "" Vector__XXX
 SG_ ESP_Verz_EPB_aktiv  : 122|1@1+ (1.000000,0.000000) [0.000000|1.000000] "" Vector__XXX
 SG_ ECD_Bremslicht  : 123|1@1+ (1.000000,0.000000) [0.000000|1.000000] "" Motor_BEV
 SG_ ESP_Verzoeg_EPB_verf  : 124|1@1+ (1.000000,0.000000) [0.000000|1.000000] "" Vector__XXX
 SG_ ESP_Status_Bremsdruck  : 125|1@1+ (1.000000,0.000000) [0.000000|1.000000] "" Vector__XXX
 SG_ ESP_Anforderung_EPB  : 126|2@1+ (1.000000,0.000000) [0.000000|3.000000] "" Vector__XXX
 SG_ ESP_ANB_CM_Rueckk_Umsetz  : 140|1@1+ (1.000000,0.000000) [0.000000|1.000000] "" Vector__XXX
 SG_ ESP_Konsistenz_ACC_Botschaft  : 141|1@1+ (1.000000,0.000000) [0.000000|1.000000] "" Vector__XXX
 SG_ ESP_Stillstandsphase_erschoepft  : 142|1@1+ (1.000000,0.000000) [0.000000|1.000000] "" Vector__XXX
 SG_ ESP_ZT_Rueckk_Umsetz  : 143|1@1+ (1.000000,0.000000) [0.000000|1.000000] "" Vector__XXX
 SG_ ESP_Tuerkontakt_Fahrertuer  : 144|1@1+ (1.000000,0.000000) [0.000000|1.000000] "" Vector__XXX
 SG_ ESP_Abrutschen_Stillstand  : 146|1@1+ (1.000000,0.000000) [0.000000|1.000000] "" Vector__XXX
 SG_ ESP_Fahrer_tritt_ZBR_Schw  : 147|1@1+ (1.000000,0.000000) [0.000000|1.000000] "" Vector__XXX
 SG_ ESP_QBit_v_ref  : 169|1@1+ (1.000000,0.000000) [0.000000|1.000000] "" Vector__XXX
 SG_ ESP_v_ref_Fahrtrichtung  : 170|2@1+ (1.000000,0.000000) [0.000000|3.000000] "" Motor_BEV
 SG_ ESC_Bremsdruckgradient  : 172|8@1+ (10.000000,0.000000) [0.000000|2500.000000] "Unit_BarPerSecon" Vector__XXX
 SG_ ESP_v_ref  : 180|12@1+ (0.125000,0.000000) [0.000000|511.500000] "Unit_KiloMeterPerHour" Airbag Motor_BEV
 SG_ ESC_Hydr_Fkt_aktiv  : 223|2@1+ (1.000000,0.000000) [0.000000|3.000000] "" Vector__XXX
 SG_ ESC_QBit_Fahrerbremswunsch  : 225|1@1+ (1.000000,0.000000) [0.000000|1.000000] "" Motor_BEV
 SG_ ESC_Fahrerbremswunsch  : 226|10@1+ (0.300000,-30.000000) [-30.000000|276.600000] "Unit_Bar" Motor_BEV
 SG_ ESCGeneratorSollMoment  : 236|12@1+ (3.000000,-12279.000000) [-12279.000000|0.000000] "" Motor_BEV
 SG_ ESC_Raddruck_max  : 248|8@1+ (1.000000,0.000000) [0.000000|250.000000] "Unit_Bar" Vector__XXX
 SG_ EPB_QBit_Pedalweg_Kuppl  : 269|1@1+ (1.000000,0.000000) [0.000000|1.000000] "" Vector__XXX
 SG_ EPB_Freig_Verzoeg_Anf  : 271|1@1+ (1.000000,0.000000) [0.000000|1.000000] "" Vector__XXX
 SG_ EPB_Verzoeg_Anf  : 272|8@1+ (0.048000,-7.968000) [-7.968000|4.224000] "Unit_MeterPerSeconSquar" Vector__XXX
 SG_ EPB_Pedalweg_Kuppl  : 288|8@1+ (0.400000,0.000000) [8.000000|92.000000] "Unit_PerCent" Vector__XXX
 SG_ EPB_DAA_Randbed_erf  : 305|1@1+ (1.000000,0.000000) [0.000000|1.000000] "" Vector__XXX
 SG_ EPB_Fehlerstatus_02  : 306|2@1+ (1.000000,0.000000) [0.000000|3.000000] "" Vector__XXX
 SG_ EPB_Schalterposition  : 308|2@1+ (1.000000,0.000000) [0.000000|3.000000] "" Airbag
 SG_ EPB_QBit_Schalterpos  : 310|1@1+ (1.000000,0.000000) [0.000000|1.000000] "" Vector__XXX
 SG_ EPB_Spannkraft  : 312|5@1+ (1.000000,0.000000) [0.000000|29.000000] "Unit_KiloNewto" Vector__XXX
 SG_ EPB_Status_02  : 317|3@1+ (1.000000,0.000000) [0.000000|7.000000] "" Motor_BEV
 SG_ EPB_Status  : 320|2@1+ (1.000000,0.000000) [0.000000|3.000000] "" Vector__XXX
 SG_ ESP_Status_Bremsentemp_02  : 322|2@1+ (1.000000,0.000000) [0.000000|3.000000] "" Motor_BEV

BU_:  Airbag BAP_Tester ICAS1_Gateway ICAS1_KommunikationsServer LE1 LE2 Motor_BEV Schaltbetaetigung

BO_ 192 EM1_01: 32 LE1
 SG_ EM1_01_CRC  : 0|8@1+ (1.000000,0.000000) [0.000000|255.000000] "" ICAS1_Gateway Motor_BEV
 SG_ EM1_01_BZ  : 8|4@1+ (1.000000,0.000000) [0.000000|15.000000] "" ICAS1_Gateway Motor_BEV
 SG_ EM1_Istmodus  : 12|4@1+ (1.000000,0.000000) [0.000000|15.000000] "" ICAS1_Gateway Motor_BEV
 SG_ EM1_IstMoment  : 16|12@1+ (0.500000,-1023.000000) [-1023.000000|1023.500000] "Unit_NewtoMeter" ICAS1_Gateway Motor_BEV
 SG_ EM1_Moment_AR_Eingriff  : 28|12@1+ (0.500000,-1023.000000) [-1023.000000|1023.500000] "Unit_NewtoMeter" ICAS1_Gateway Motor_BEV
 SG_ EM1_IstDrehzahl  : 40|15@1+ (1.000000,-10000.000000) [-10000.000000|22765.000000] "Unit_MinutInver" ICAS1_Gateway Motor_BEV
 SG_ EM1_AR_aktiv  : 55|1@1+ (1.000000,0.000000) [0.000000|1.000000] "" ICAS1_Gateway Motor_BEV
 SG_ EM1_IstSpannung  : 56|12@1+ (0.250000,0.000000) [0.000000|1023.250000] "Unit_Volt" ICAS1_Gateway Motor_BEV
 SG_ EM1_Strom_HV  : 68|12@1+ (0.500000,-1023.000000) [-1023.000000|1023.500000] "Unit_Amper" ICAS1_Gateway Motor_BEV
 SG_ EM1_Max_Moment  : 80|11@1+ (1.000000,-1023.000000) [-1023.000000|1022.000000] "Unit_NewtoMeter" ICAS1_Gateway Motor_BEV
 SG_ EM1_ErwGrenzen_aktiv  : 91|1@1+ (1.000000,0.000000) [0.000000|1.000000] "" ICAS1_Gateway Motor_BEV
 SG_ EM1_Min_Moment  : 92|11@1+ (1.000000,-1023.000000) [-1023.000000|1022.000000] "Unit_NewtoMeter" ICAS1_Gateway Motor_BEV
 SG_ EM1_Fehler_ElAntriebAbschaltung  : 103|1@1+ (1.000000,0.000000) [0.000000|1.000000] "" ICAS1_Gateway Motor_BEV
 SG_ EM1_Max_Moment_Lim  : 104|11@1+ (1.000000,-1023.000000) [-1023.000000|1022.000000] "Unit_NewtoMeter" ICAS1_Gateway Motor_BEV
 SG_ EM1_Fehler_Notabschaltung  : 115|1@1+ (1.000000,0.000000) [0.000000|1.000000] "" ICAS1_Gateway Motor_BEV
 SG_ EM1_Min_Moment_Lim  : 116|11@1+ (1.000000,-1023.000000) [-1023.000000|1022.000000] "Unit_NewtoMeter" ICAS1_Gateway Motor_BEV
 SG_ EM1_Status_DrzEingriff  : 127|2@1+ (1.000000,0.000000) [0.000000|3.000000] "" ICAS1_Gateway Motor_BEV
 SG_ EM1_Mom_DrzEingriff  : 129|11@1+ (1.000000,-1023.000000) [-1023.000000|1022.000000] "Unit_NewtoMeter" ICAS1_Gateway Motor_BEV

BO_ 2463978673 EM1_02: 32 LE1
 SG_ EM1_Status_Spgfreiheit  : 12|2@1+ (1.000000,0.000000) [0.000000|3.000000] "" Motor_BEV
 SG_ EM1_Status_EoHVL  : 14|2@1+ (1.000000,0.000000) [0.000000|3.000000] "" Motor_BEV
 SG_ EM1_Max_LeistungMech_Sockel  : 16|13@1+ (200.000000,-819000.000000) [-819000.000000|818800.000000] "Unit_Watt" Vector__XXX
 SG_ EM1_Max_Moment_Sockel  : 29|11@1+ (1.000000,-1023.000000) [-1023.000000|1022.000000] "Unit_NewtoMeter" Vector__XXX
 SG_ EM1_Min_LeistungMech_Sockel  : 40|13@1+ (200.000000,-819000.000000) [-819000.000000|818800.000000] "Unit_Watt" Vector__XXX
 SG_ EM1_Min_Moment_Sockel  : 53|11@1+ (1.000000,-1023.000000) [-1023.000000|1022.000000] "Unit_NewtoMeter" Vector__XXX
 SG_ EM1_PerfInd_MaxLeistung  : 64|10@1+ (0.200000,0.000000) [0.000000|200.000000] "Unit_PerCent" Motor_BEV
 SG_ EM1_PerfInd_MaxMoment  : 74|10@1+ (0.200000,0.000000) [0.000000|200.000000] "Unit_PerCent" Motor_BEV
 SG_ EM1_AnlernenElMotor_Anf  : 84|1@1+ (1.000000,0.000000) [0.000000|1.000000] "" Motor_BEV
 SG_ EM1_OBD_Lampe_Anf  : 85|1@1+ (1.000000,0.000000) [0.000000|1.000000] "" Motor_BEV
 SG_ EM1_Generator_Moment  : 86|10@1+ (1.000000,0.000000) [0.000000|1021.000000] "Unit_NewtoMeter" Motor_BEV
 SG_ EM1_PerfInd_Temperatur  : 96|8@1+ (0.800000,0.000000) [0.000000|200.000000] "Unit_PerCent" Motor_BEV
 SG_ EM1_MaxZul_Drehzahl  : 104|8@1+ (80.000000,0.000000) [0.000000|20240.000000] "Unit_RevPerMinute" Motor_BEV
 SG_ EM1_Min_Moment_Gesamt  : 112|11@1+ (1.000000,-1023.000000) [-1023.000000|1022.000000] "Unit_NewtoMeter" Motor_BEV
 SG_ EM1_Fehlerlampe_Anf  : 123|1@1+ (1.000000,0.000000) [0.000000|1.000000] "" Motor_BEV
 SG_ EM1_Max_Moment_Gesamt  : 124|11@1+ (1.000000,-1023.000000) [-1023.000000|1022.000000] "Unit_NewtoMeter" Motor_BEV
 SG_ EM1_Warnlampe_Anf  : 135|1@1+ (1.000000,0.000000) [0.000000|1.000000] "" Motor_BEV
 SG_ EM1_Rekuperation  : 136|15@1+ (10.000000,0.000000) [0.000000|327670.000000] "Unit_WattSecond" Motor_BEV
 SG_ EM1_Rekuperation_Ueberlauf  : 151|1@1+ (1.000000,0.000000) [0.000000|1.000000] "" Motor_BEV
 SG_ EM1_Verbrauch  : 152|15@1+ (10.000000,0.000000) [0.000000|327670.000000] "Unit_WattSecond" Motor_BEV
 SG_ EM1_Verbrauch_Ueberlauf  : 167|1@1+ (1.000000,0.000000) [0.000000|1.000000] "" Motor_BEV
 SG_ EM1_Fehler_AE  : 168|1@1+ (1.000000,0.000000) [0.000000|1.000000] "" Motor_BEV
 SG_ EM1_Fehler_Leistungsred  : 169|1@1+ (1.000000,0.000000) [0.000000|1.000000] "" Motor_BEV
 SG_ EM1_Fehler_ElAntriebFreilauf  : 170|1@1+ (1.000000,0.000000) [0.000000|1.000000] "" Motor_BEV
 SG_ EM1_PWR_SollVolumenstrom  : 171|6@1+ (0.500000,0.000000) [0.000000|30.500000] "Unit_LiterPerMinut" Motor_BEV

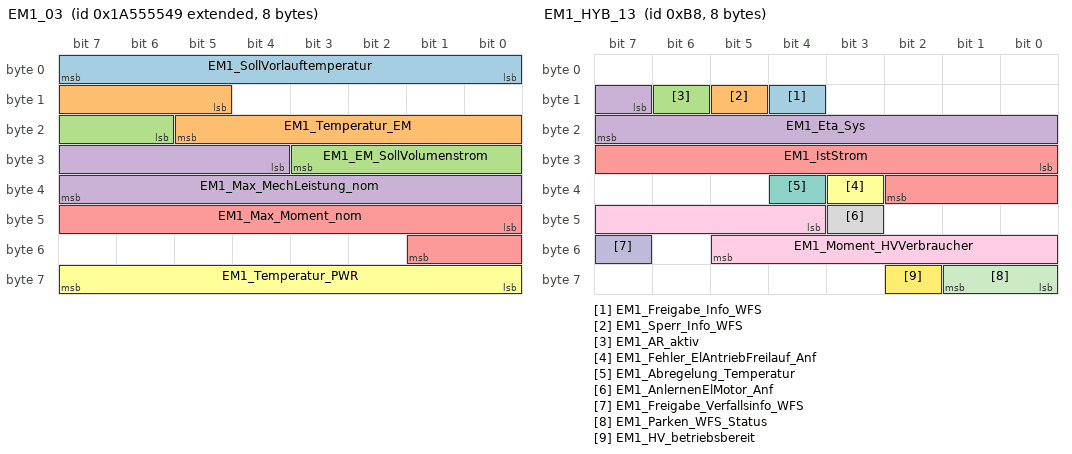
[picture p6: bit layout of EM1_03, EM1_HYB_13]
BO_ 2589283657 EM1_03: 8 LE1
 SG_ EM1_SollVorlauftemperatur  : 0|8@1+ (0.500000,-40.000000) [-40.000000|86.500000] "Unit_DegreCelsi" Motor_BEV
 SG_ EM1_Temperatur_EM  : 13|9@1+ (1.000000,-40.000000) [-40.000000|469.000000] "Unit_DegreCelsi" ICAS1_Gateway Motor_BEV
 SG_ EM1_EM_SollVolumenstrom  : 22|6@1+ (0.500000,0.000000) [0.000000|30.500000] "Unit_LiterPerMinut" Motor_BEV
 SG_ EM1_Max_MechLeistung_nom  : 28|12@1+ (200.000000,0.000000) [0.000000|818600.000000] "Unit_Watt" Motor_BEV
 SG_ EM1_Max_Moment_nom  : 40|10@1+ (1.000000,0.000000) [0.000000|1021.000000] "Unit_NewtoMeter" Motor_BEV
 SG_ EM1_Temperatur_PWR  : 56|8@1+ (1.000000,-40.000000) [-40.000000|213.000000] "Unit_DegreCelsi" ICAS1_Gateway Motor_BEV

BO_ 184 EM1_HYB_13: 8 LE1
 SG_ EM1_Freigabe_Info_WFS  : 12|1@1+ (1.000000,0.000000) [0.000000|1.000000] "" ICAS1_Gateway Motor_BEV
 SG_ EM1_Sperr_Info_WFS  : 13|1@1+ (1.000000,0.000000) [0.000000|1.000000] "" ICAS1_Gateway Motor_BEV
 SG_ EM1_AR_aktiv  : 14|1@1+ (1.000000,0.000000) [0.000000|1.000000] "" ICAS1_Gateway
 SG_ EM1_Eta_Sys  : 15|9@1+ (0.200000,0.000000) [0.000000|101.800000] "Unit_PerCent" ICAS1_Gateway
 SG_ EM1_IstStrom  : 24|11@1+ (1.000000,-1023.000000) [-1023.000000|1022.000000] "Unit_Amper" ICAS1_Gateway
 SG_ EM1_Fehler_ElAntriebFreilauf_Anf  : 35|1@1+ (1.000000,0.000000) [0.000000|1.000000] "" ICAS1_Gateway
 SG_ EM1_Abregelung_Temperatur  : 36|1@1+ (1.000000,0.000000) [0.000000|1.000000] "" ICAS1_Gateway
 SG_ EM1_AnlernenElMotor_Anf  : 43|1@1+ (1.000000,0.000000) [0.000000|1.000000] "" ICAS1_Gateway
 SG_ EM1_Moment_HVVerbraucher  : 44|10@1+ (1.000000,-511.000000) [-511.000000|511.000000] "Unit_NewtoMeter" ICAS1_Gateway
 SG_ EM1_Freigabe_Verfallsinfo_WFS  : 55|1@1+ (1.000000,0.000000) [0.000000|1.000000] "" ICAS1_Gateway Motor_BEV
 SG_ EM1_Parken_WFS_Status  : 56|2@1+ (1.000000,0.000000) [0.000000|3.000000] "" ICAS1_Gateway
 SG_ EM1_HV_betriebsbereit  : 58|1@1+ (1.000000,0.000000) [0.000000|1.000000] "" ICAS1_Gateway

BO_ 2527679712 EM1_HYB_27: 8 LE1
 SG_ EM1_RtmWarnKommunikation  : 12|3@1+ (1.000000,0.000000) [0.000000|7.000000] "" Vector__XXX
 SG_ EM1_RtmWarnUeberdrehzahl  : 15|3@1+ (1.000000,0.000000) [0.000000|7.000000] "" ICAS1_Gateway
 SG_ EM1_RtmWarnUeberstrom  : 18|3@1+ (1.000000,0.000000) [0.000000|7.000000] "" ICAS1_Gateway
 SG_ EM1_RtmWarnTempEM  : 21|3@1+ (1.000000,0.000000) [0.000000|7.000000] "" ICAS1_Gateway
 SG_ EM1_RtmWarnTempPWR  : 24|3@1+ (1.000000,0.000000) [0.000000|7.000000] "" ICAS1_Gateway

BO_ 193 EM2_01: 32 LE2
 SG_ EM2_01_CRC  : 0|8@1+ (1.000000,0.000000) [0.000000|255.000000] "" Motor_BEV
 SG_ EM2_01_BZ  : 8|4@1+ (1.000000,0.000000) [0.000000|15.000000] "" Motor_BEV
 SG_ EM2_Istmodus  : 12|4@1+ (1.000000,0.000000) [0.000000|15.000000] "" ICAS1_Gateway Motor_BEV
 SG_ EM2_IstMoment  : 16|12@1+ (0.500000,-1023.000000) [-1023.000000|1023.500000] "Unit_NewtoMeter" ICAS1_Gateway Motor_BEV
 SG_ EM2_Moment_AR_Eingriff  : 28|12@1+ (0.500000,-1023.000000) [-1023.000000|1023.500000] "Unit_NewtoMeter" Motor_BEV
 SG_ EM2_IstDrehzahl  : 40|15@1+ (1.000000,-10000.000000) [-10000.000000|22765.000000] "Unit_MinutInver" ICAS1_Gateway Motor_BEV
 SG_ EM2_AR_aktiv  : 55|1@1+ (1.000000,0.000000) [0.000000|1.000000] "" Motor_BEV
 SG_ EM2_IstSpannung  : 56|12@1+ (0.250000,0.000000) [0.000000|1023.250000] "Unit_Volt" ICAS1_Gateway Motor_BEV
 SG_ EM2_Strom_HV  : 68|12@1+ (0.500000,-1023.000000) [-1023.000000|1023.500000] "Unit_Amper" ICAS1_Gateway Motor_BEV
 SG_ EM2_Max_Moment  : 80|11@1+ (1.000000,-1023.000000) [-1023.000000|1022.000000] "Unit_NewtoMeter" Motor_BEV
 SG_ EM2_ErwGrenzen_aktiv  : 91|1@1+ (1.000000,0.000000) [0.000000|1.000000] "" Motor_BEV
 SG_ EM2_Min_Moment  : 92|11@1+ (1.000000,-1023.000000) [-1023.000000|1022.000000] "Unit_NewtoMeter" Motor_BEV
 SG_ EM2_Fehler_ElAntriebAbschaltung  : 103|1@1+ (1.000000,0.000000) [0.000000|1.000000] "" Motor_BEV
 SG_ EM2_Max_Moment_Lim  : 104|11@1+ (1.000000,-1023.000000) [-1023.000000|1022.000000] "Unit_NewtoMeter" Motor_BEV
 SG_ EM2_Fehler_Notabschaltung  : 115|1@1+ (1.000000,0.000000) [0.000000|1.000000] "" ICAS1_Gateway Motor_BEV
 SG_ EM2_Min_Moment_Lim  : 116|11@1+ (1.000000,-1023.000000) [-1023.000000|1022.000000] "Unit_NewtoMeter" Motor_BEV
 SG_ EM2_Status_DrzEingriff  : 127|2@1+ (1.000000,0.000000) [0.000000|3.000000] "" ICAS1_Gateway Motor_BEV
 SG_ EM2_Mom_DrzEingriff  : 129|11@1+ (1.000000,-1023.000000) [-1023.000000|1022.000000] "Unit_NewtoMeter" Motor_BEV

BO_ 2463978674 EM2_02: 32 LE2
 SG_ EM2_Status_Spgfreiheit  : 12|2@1+ (1.000000,0.000000) [0.000000|3.000000] "" Motor_BEV
 SG_ EM2_Status_EoHVL  : 14|2@1+ (1.000000,0.000000) [0.000000|3.000000] "" Motor_BEV
 SG_ EM2_Max_LeistungMech_Sockel  : 16|13@1+ (200.000000,-819000.000000) [-819000.000000|818800.000000] "Unit_Watt" Vector__XXX
 SG_ EM2_Max_Moment_Sockel  : 29|11@1+ (1.000000,-1023.000000) [-1023.000000|1022.000000] "Unit_NewtoMeter" Vector__XXX
 SG_ EM2_Min_LeistungMech_Sockel  : 40|13@1+ (200.000000,-819000.000000) [-819000.000000|818800.000000] "Unit_Watt" Vector__XXX
 SG_ EM2_Min_Moment_Sockel  : 53|11@1+ (1.000000,-1023.000000) [-1023.000000|1022.000000] "Unit_NewtoMeter" Vector__XXX
 SG_ EM2_PerfInd_MaxLeistung  : 64|10@1+ (0.200000,0.000000) [0.000000|200.000000] "Unit_PerCent" Motor_BEV
 SG_ EM2_PerfInd_MaxMoment  : 74|10@1+ (0.200000,0.000000) [0.000000|200.000000] "Unit_PerCent" Motor_BEV
 SG_ EM2_AnlernenElMotor_Anf  : 84|1@1+ (1.000000,0.000000) [0.000000|1.000000] "" Motor_BEV
 SG_ EM2_OBD_Lampe_Anf  : 85|1@1+ (1.000000,0.000000) [0.000000|1.000000] "" Motor_BEV
 SG_ EM2_Generator_Moment  : 86|10@1+ (1.000000,0.000000) [0.000000|1021.000000] "Unit_NewtoMeter" Motor_BEV
 SG_ EM2_PerfInd_Temperatur  : 96|8@1+ (0.800000,0.000000) [0.000000|200.000000] "Unit_PerCent" Motor_BEV
 SG_ EM2_MaxZul_Drehzahl  : 104|8@1+ (80.000000,0.000000) [0.000000|20240.000000] "Unit_RevPerMinute" Motor_BEV
 SG_ EM2_Min_Moment_Gesamt  : 112|11@1+ (1.000000,-1023.000000) [-1023.000000|1022.000000] "Unit_NewtoMeter" Motor_BEV
 SG_ EM2_Fehlerlampe_Anf  : 123|1@1+ (1.000000,0.000000) [0.000000|1.000000] "" Motor_BEV
 SG_ EM2_Max_Moment_Gesamt  : 124|11@1+ (1.000000,-1023.000000) [-1023.000000|1022.000000] "Unit_NewtoMeter" Motor_BEV
 SG_ EM2_Warnlampe_Anf  : 135|1@1+ (1.000000,0.000000) [0.000000|1.000000] "" Motor_BEV
 SG_ EM2_Rekuperation  : 136|15@1+ (10.000000,0.000000) [0.000000|327670.000000] "Unit_WattSecond" Motor_BEV
 SG_ EM2_Rekuperation_Ueberlauf  : 151|1@1+ (1.000000,0.000000) [0.000000|1.000000] "" Motor_BEV
 SG_ EM2_Verbrauch  : 152|15@1+ (10.000000,0.000000) [0.000000|327670.000000] "Unit_WattSecond" Motor_BEV
 SG_ EM2_Verbrauch_Ueberlauf  : 167|1@1+ (1.000000,0.000000) [0.000000|1.000000] "" Motor_BEV
 SG_ EM2_Fehler_AE  : 168|1@1+ (1.000000,0.000000) [0.000000|1.000000] "" Motor_BEV
 SG_ EM2_Fehler_Leistungsred  : 169|1@1+ (1.000000,0.000000) [0.000000|1.000000] "" Motor_BEV
 SG_ EM2_Fehler_ElAntriebFreilauf  : 170|1@1+ (1.000000,0.000000) [0.000000|1.000000] "" Motor_BEV
 SG_ EM2_PWR_SollVolumenstrom  : 171|6@1+ (0.500000,0.000000) [0.000000|30.500000] "Unit_LiterPerMinut" Motor_BEV

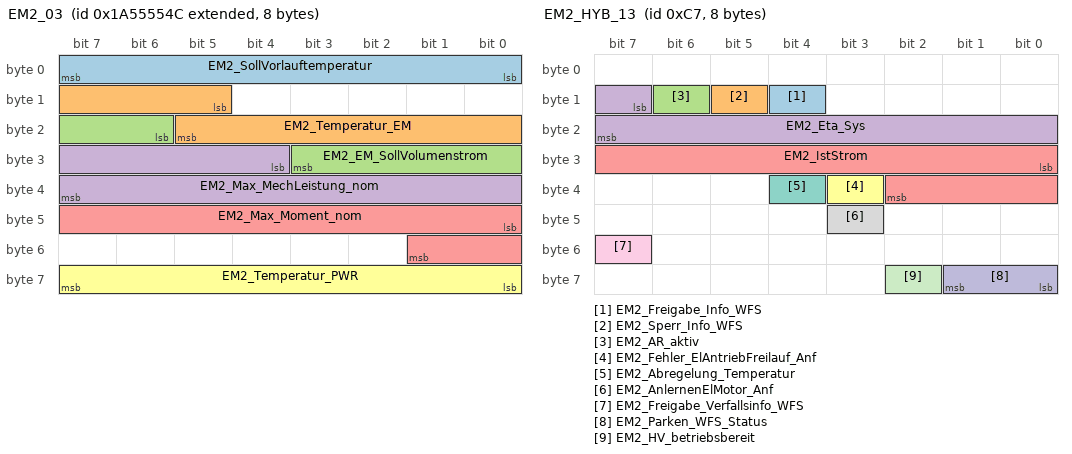
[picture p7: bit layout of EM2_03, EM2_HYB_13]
BO_ 2589283660 EM2_03: 8 LE2
 SG_ EM2_SollVorlauftemperatur  : 0|8@1+ (0.500000,-40.000000) [-40.000000|86.500000] "Unit_DegreCelsi" Motor_BEV
 SG_ EM2_Temperatur_EM  : 13|9@1+ (1.000000,-40.000000) [-40.000000|469.000000] "Unit_DegreCelsi" ICAS1_Gateway Motor_BEV
 SG_ EM2_EM_SollVolumenstrom  : 22|6@1+ (0.500000,0.000000) [0.000000|30.500000] "Unit_LiterPerMinut" Motor_BEV
 SG_ EM2_Max_MechLeistung_nom  : 28|12@1+ (200.000000,0.000000) [0.000000|818600.000000] "Unit_Watt" Motor_BEV
 SG_ EM2_Max_Moment_nom  : 40|10@1+ (1.000000,0.000000) [0.000000|1021.000000] "Unit_NewtoMeter" Motor_BEV
 SG_ EM2_Temperatur_PWR  : 56|8@1+ (1.000000,-40.000000) [-40.000000|213.000000] "Unit_DegreCelsi" ICAS1_Gateway Motor_BEV

BO_ 199 EM2_HYB_13: 8 LE2
 SG_ EM2_Freigabe_Info_WFS  : 12|1@1+ (1.000000,0.000000) [0.000000|1.000000] "" ICAS1_Gateway Motor_BEV
 SG_ EM2_Sperr_Info_WFS  : 13|1@1+ (1.000000,0.000000) [0.000000|1.000000] "" ICAS1_Gateway Motor_BEV
 SG_ EM2_AR_aktiv  : 14|1@1+ (1.000000,0.000000) [0.000000|1.000000] "" ICAS1_Gateway
 SG_ EM2_Eta_Sys  : 15|9@1+ (0.200000,0.000000) [0.000000|101.800000] "Unit_PerCent" ICAS1_Gateway
 SG_ EM2_IstStrom  : 24|11@1+ (1.000000,-1023.000000) [-1023.000000|1022.000000] "Unit_Amper" ICAS1_Gateway
 SG_ EM2_Fehler_ElAntriebFreilauf_Anf  : 35|1@1+ (1.000000,0.000000) [0.000000|1.000000] "" ICAS1_Gateway
 SG_ EM2_Abregelung_Temperatur  : 36|1@1+ (1.000000,0.000000) [0.000000|1.000000] "" ICAS1_Gateway
 SG_ EM2_AnlernenElMotor_Anf  : 43|1@1+ (1.000000,0.000000) [0.000000|1.000000] "" ICAS1_Gateway
 SG_ EM2_Freigabe_Verfallsinfo_WFS  : 55|1@1+ (1.000000,0.000000) [0.000000|1.000000] "" ICAS1_Gateway Motor_BEV
 SG_ EM2_Parken_WFS_Status  : 56|2@1+ (1.000000,0.000000) [0.000000|3.000000] "" ICAS1_Gateway
 SG_ EM2_HV_betriebsbereit  : 58|1@1+ (1.000000,0.000000) [0.000000|1.000000] "" ICAS1_Gateway

BO_ 2527679713 EM2_HYB_27: 8 LE2
 SG_ EM2_RtmWarnKommunikation  : 12|3@1+ (1.000000,0.000000) [0.000000|7.000000] "" Vector__XXX
 SG_ EM2_RtmWarnUeberdrehzahl  : 15|3@1+ (1.000000,0.000000) [0.000000|7.000000] "" ICAS1_Gateway
 SG_ EM2_RtmWarnUeberstrom  : 18|3@1+ (1.000000,0.000000) [0.000000|7.000000] "" ICAS1_Gateway
 SG_ EM2_RtmWarnTempEM  : 21|3@1+ (1.000000,0.000000) [0.000000|7.000000] "" ICAS1_Gateway
 SG_ EM2_RtmWarnTempPWR  : 24|3@1+ (1.000000,0.000000) [0.000000|7.000000] "" ICAS1_Gateway

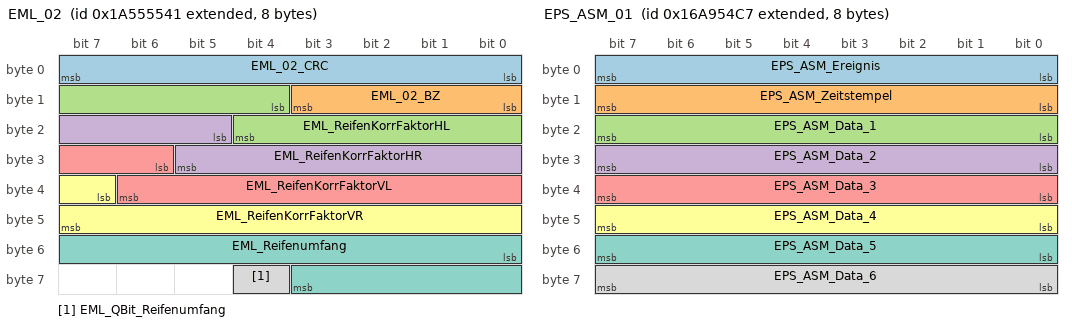
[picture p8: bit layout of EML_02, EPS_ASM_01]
BO_ 2589283649 EML_02: 8 ICAS1_Gateway
 SG_ EML_02_CRC  : 0|8@1+ (1.000000,0.000000) [0.000000|255.000000] "" Vector__XXX
 SG_ EML_02_BZ  : 8|4@1+ (1.000000,0.000000) [0.000000|15.000000] "" Vector__XXX
 SG_ EML_ReifenKorrFaktorHL  : 12|9@1+ (0.000488,0.850000) [0.850000|1.098535] "" Vector__XXX
 SG_ EML_ReifenKorrFaktorHR  : 21|9@1+ (0.000488,0.850000) [0.850000|1.098535] "" Vector__XXX
 SG_ EML_ReifenKorrFaktorVL  : 30|9@1+ (0.000488,0.850000) [0.850000|1.098535] "" Vector__XXX
 SG_ EML_ReifenKorrFaktorVR  : 39|9@1+ (0.000488,0.850000) [0.850000|1.098535] "" Vector__XXX
 SG_ EML_Reifenumfang  : 48|12@1+ (1.000000,0.000000) [0.000000|4095.000000] "Unit_MilliMeter" Motor_BEV
 SG_ EML_QBit_Reifenumfang  : 60|1@1+ (1.000000,0.000000) [0.000000|1.000000] "" Motor_BEV

BO_ 608 EML_07: 8 ICAS1_Gateway
 SG_ EML_AnzeigeGeschw  : 54|10@1+ (0.320000,0.000000) [0.000000|325.120000] "Unit_KiloMeterPerHour" Motor_BEV

BO_ 2589283751 Entfernungen_01: 8 ICAS1_KommunikationsServer
 SG_ KBI_Kilometerstand_HiRes_meter  : 32|32@1+ (1.000000,0.000000) [0.000000|4294967295.000000] "Unit_Meter" Motor_BEV

BO_ 2527679687 EPS_ASM_01: 8 ICAS1_Gateway
 SG_ EPS_ASM_Ereignis  : 0|8@1+ (1.000000,0.000000) [1.000000|254.000000] "Unit_None" Airbag
 SG_ EPS_ASM_Zeitstempel  : 8|8@1+ (0.080000,0.000000) [0.000000|20.320000] "Unit_None" Airbag
 SG_ EPS_ASM_Data_1  : 16|8@1+ (1.000000,0.000000) [0.000000|255.000000] "Unit_None" Airbag
 SG_ EPS_ASM_Data_2  : 24|8@1+ (1.000000,0.000000) [0.000000|255.000000] "Unit_None" Airbag
 SG_ EPS_ASM_Data_3  : 32|8@1+ (1.000000,0.000000) [0.000000|255.000000] "Unit_None" Airbag
 SG_ EPS_ASM_Data_4  : 40|8@1+ (1.000000,0.000000) [0.000000|255.000000] "Unit_None" Airbag
 SG_ EPS_ASM_Data_5  : 48|8@1+ (1.000000,0.000000) [0.000000|255.000000] "Unit_None" Airbag
 SG_ EPS_ASM_Data_6  : 56|8@1+ (1.000000,0.000000) [0.000000|255.000000] "Unit_None" Airbag

BO_ 258 ESC_50: 48 ICAS1_Gateway
 SG_ ESC_50_CRC  : 0|8@1+ (1.000000,0.000000) [0.000000|255.000000] "" Motor_BEV
 SG_ ESC_50_BZ  : 8|4@1+ (1.000000,0.000000) [0.000000|15.000000] "" Motor_BEV
 SG_ ESP_QBit_Gierrate  : 12|1@1+ (1.000000,0.000000) [0.000000|1.000000] "" Motor_BEV
 SG_ ESP_QBit_Laengsbeschl  : 13|1@1+ (1.000000,0.000000) [0.000000|1.000000] "" Motor_BEV
 SG_ ESP_QBit_Querb  : 14|1@1+ (1.000000,0.000000) [0.000000|1.000000] "" Motor_BEV
 SG_ ESP_Querbeschleunigung  : 16|8@1+ (0.010000,-1.270000) [-1.270000|1.270000] "Unit_ForceOfGravi" Airbag Motor_BEV
 SG_ ESP_Laengsbeschl  : 24|10@1+ (0.031250,-16.000000) [-16.000000|15.906250] "Unit_MeterPerSeconSquar" Airbag Motor_BEV
 SG_ ESC_Motorstartverzoegerung  : 34|1@1+ (1.000000,0.000000) [0.000000|1.000000] "" Vector__XXX
 SG_ ESC_SeitenwindAssistent_Eingriff  : 35|1@1+ (1.000000,0.000000) [0.000000|1.000000] "" Vector__XXX
 SG_ ESP_Anschleppstart_Freigabe  : 36|2@1+ (1.000000,0.000000) [0.000000|3.000000] "" Vector__XXX
 SG_ ESC_Unterdruckmangel_erkannt  : 38|1@1+ (1.000000,0.000000) [0.000000|1.000000] "" Vector__XXX
 SG_ ESP_Gierrate  : 40|14@1+ (0.010000,0.000000) [0.000000|163.820000] "Unit_DegreOfArcPerSecon" Airbag Motor_BEV
 SG_ ESP_VZ_Gierrate  : 54|1@1+ (1.000000,0.000000) [0.000000|1.000000] "" Airbag Motor_BEV
 SG_ ESP_Notbremsanzeige  : 55|1@1+ (1.000000,0.000000) [0.000000|1.000000] "" Vector__XXX
 SG_ ESP_SpannungsAnf  : 56|1@1+ (1.000000,0.000000) [0.000000|1.000000] "" Vector__XXX
 SG_ ESP_PLA_Abbruch  : 57|3@1+ (1.000000,0.000000) [0.000000|7.000000] "" Vector__XXX
 SG_ ESP_Status_ESP_PLA  : 60|4@1+ (1.000000,0.000000) [0.000000|15.000000] "" Vector__XXX
 SG_ ESP_QBit_Bremsdruck  : 76|1@1+ (1.000000,0.000000) [0.000000|1.000000] "" Airbag Motor_BEV
 SG_ ESP_QBit_Fahrer_bremst  : 77|1@1+ (1.000000,0.000000) [0.000000|1.000000] "" Vector__XXX
 SG_ ESP_Schwelle_Unterdruck  : 78|2@1+ (1.000000,0.000000) [0.000000|3.000000] "" Vector__XXX
 SG_ ESP_Bremsdruck  : 80|10@1+ (0.300000,-30.000000) [-30.000000|276.600000] "Unit_Bar" Motor_BEV
 SG_ ESP_Fahrer_bremst  : 90|1@1+ (1.000000,0.000000) [0.000000|1.000000] "" Vector__XXX
 SG_ ESP_Verz_TSK_aktiv  : 91|1@1+ (1.000000,0.000000) [0.000000|1.000000] "" Vector__XXX
 SG_ ESP_Lenkeingriff_ADS  : 92|1@1+ (1.000000,0.000000) [0.000000|1.000000] "" Vector__XXX
 SG_ ESP_Konsistenz_TSK  : 93|1@1+ (1.000000,0.000000) [0.000000|1.000000] "" Vector__XXX
 SG_ ESP_Bremsruck_AWV2  : 94|1@1+ (1.000000,0.000000) [0.000000|1.000000] "" Vector__XXX
 SG_ ESP_Konsistenz_AWV2  : 95|1@1+ (1.000000,0.000000) [0.000000|1.000000] "" Vector__XXX
 SG_ ECD_Fehler  : 96|1@1+ (1.000000,0.000000) [0.000000|1.000000] "" Vector__XXX
 SG_ ECD_nicht_verfuegbar  : 97|1@1+ (1.000000,0.000000) [0.000000|1.000000] "" Vector__XXX
 SG_ ESP_Status_Bremsentemp  : 98|1@1+ (1.000000,0.000000) [0.000000|1.000000] "" Vector__XXX
 SG_ ESP_Autohold_Standby  : 99|1@1+ (1.000000,0.000000) [0.000000|1.000000] "" Vector__XXX
 SG_ ESP_HDC_Standby  : 100|1@1+ (1.000000,0.000000) [0.000000|1.000000] "" Vector__XXX
 SG_ ESP_HBA_aktiv  : 101|1@1+ (1.000000,0.000000) [0.000000|1.000000] "" Vector__XXX
 SG_ ESP_Prefill_ausgeloest  : 102|1@1+ (1.000000,0.000000) [0.000000|1.000000] "" Vector__XXX
 SG_ ESP_Rueckwaertsfahrt_erkannt  : 103|1@1+ (1.000000,0.000000) [0.000000|1.000000] "" Vector__XXX
 SG_ ESP_Status_Anfahrhilfe  : 104|1@1+ (1.000000,0.000000) [0.000000|1.000000] "" Vector__XXX
 SG_ ESP_HDC_aktiv  : 105|1@1+ (1.000000,0.000000) [0.000000|1.000000] "" Vector__XXX
 SG_ ESP_StartStopp_Info  : 106|2@1+ (1.000000,0.000000) [0.000000|3.000000] "" Vector__XXX
 SG_ ESP_Eingr_HL  : 108|1@1+ (1.000000,0.000000) [0.000000|1.000000] "" Vector__XXX
 SG_ ESP_Eingr_HR  : 109|1@1+ (1.000000,0.000000) [0.000000|1.000000] "" Vector__XXX
 SG_ ESP_Eingr_VL  : 110|1@1+ (1.000000,0.000000) [0.000000|1.000000] "" Vector__XXX
 SG_ ESP_Eingr_VR  : 111|1@1+ (1.000000,0.000000) [0.000000|1.000000] "" Vector__XXX
 SG_ ESP_BKV_Unterdruck  : 112|8@1+ (4.000000,0.000000) [4.000000|1012.000000] "Unit_MilliBar" Vector__XXX
 SG_ ESP_Autohold_aktiv  : 120|1@1+ (1.000000,0.000000) [0.000000|1.000000] "" Vector__XXX
 SG_ ESP_FStatus_Anfahrhilfe  : 121|1@1+ (1.000000,0.000000) [0.000000|1.000000] "" Vector__XXX
 SG_ ESP_Verz_EPB_aktiv  : 122|1@1+ (1.000000,0.000000) [0.000000|1.000000] "" Vector__XXX
 SG_ ECD_Bremslicht  : 123|1@1+ (1.000000,0.000000) [0.000000|1.000000] "" Motor_BEV
 SG_ ESP_Verzoeg_EPB_verf  : 124|1@1+ (1.000000,0.000000) [0.000000|1.000000] "" Vector__XXX
 SG_ ESP_Status_Bremsdruck  : 125|1@1+ (1.000000,0.000000) [0.000000|1.000000] "" Vector__XXX
 SG_ ESP_Anforderung_EPB  : 126|2@1+ (1.000000,0.000000) [0.000000|3.000000] "" Vector__XXX
 SG_ ESP_ANB_CM_Rueckk_Umsetz  : 140|1@1+ (1.000000,0.000000) [0.000000|1.000000] "" Vector__XXX
 SG_ ESP_Konsistenz_ACC_Botschaft  : 141|1@1+ (1.000000,0.000000) [0.000000|1.000000] "" Vector__XXX
 SG_ ESP_Stillstandsphase_erschoepft  : 142|1@1+ (1.000000,0.000000) [0.000000|1.000000] "" Vector__XXX
 SG_ ESP_ZT_Rueckk_Umsetz  : 143|1@1+ (1.000000,0.000000) [0.000000|1.000000] "" Vector__XXX
 SG_ ESP_Tuerkontakt_Fahrertuer  : 144|1@1+ (1.000000,0.000000) [0.000000|1.000000] "" Vector__XXX
 SG_ ESP_Abrutschen_Stillstand  : 146|1@1+ (1.000000,0.000000) [0.000000|1.000000] "" Vector__XXX
 SG_ ESP_Fahrer_tritt_ZBR_Schw  : 147|1@1+ (1.000000,0.000000) [0.000000|1.000000] "" Vector__XXX
 SG_ ESP_QBit_v_ref  : 169|1@1+ (1.000000,0.000000) [0.000000|1.000000] "" Vector__XXX
 SG_ ESP_v_ref_Fahrtrichtung  : 170|2@1+ (1.000000,0.000000) [0.000000|3.000000] "" Motor_BEV
 SG_ ESC_Bremsdruckgradient  : 172|8@1+ (10.000000,0.000000) [0.000000|2500.000000] "Unit_BarPerSecon" Vector__XXX
 SG_ ESP_v_ref  : 180|12@1+ (0.125000,0.000000) [0.000000|511.500000] "Unit_KiloMeterPerHour" Airbag Motor_BEV
 SG_ ESC_Hydr_Fkt_aktiv  : 223|2@1+ (1.000000,0.000000) [0.000000|3.000000] "" Vector__XXX
 SG_ ESC_QBit_Fahrerbremswunsch  : 225|1@1+ (1.000000,0.000000) [0.000000|1.000000] "" Motor_BEV
 SG_ ESC_Fahrerbremswunsch  : 226|10@1+ (0.300000,-30.000000) [-30.000000|276.600000] "Unit_Bar" Motor_BEV
 SG_ ESCGeneratorSollMoment  : 236|12@1+ (3.000000,-12279.000000) [-12279.000000|0.000000] "" Motor_BEV
 SG_ ESC_Raddruck_max  : 248|8@1+ (1.000000,0.000000) [0.000000|250.000000] "Unit_Bar" Vector__XXX
 SG_ EPB_QBit_Pedalweg_Kuppl  : 269|1@1+ (1.000000,0.000000) [0.000000|1.000000] "" Vector__XXX
 SG_ EPB_Freig_Verzoeg_Anf  : 271|1@1+ (1.000000,0.000000) [0.000000|1.000000] "" Vector__XXX
 SG_ EPB_Verzoeg_Anf  : 272|8@1+ (0.048000,-7.968000) [-7.968000|4.224000] "Unit_MeterPerSeconSquar" Vector__XXX
 SG_ EPB_Pedalweg_Kuppl  : 288|8@1+ (0.400000,0.000000) [8.000000|92.000000] "Unit_PerCent" Vector__XXX
 SG_ EPB_DAA_Randbed_erf  : 305|1@1+ (1.000000,0.000000) [0.000000|1.000000] "" Vector__XXX
 SG_ EPB_Fehlerstatus_02  : 306|2@1+ (1.000000,0.000000) [0.000000|3.000000] "" Vector__XXX
 SG_ EPB_Schalterposition  : 308|2@1+ (1.000000,0.000000) [0.000000|3.000000] "" Airbag
 SG_ EPB_QBit_Schalterpos  : 310|1@1+ (1.000000,0.000000) [0.000000|1.000000] "" Vector__XXX
 SG_ EPB_Spannkraft  : 312|5@1+ (1.000000,0.000000) [0.000000|29.000000] "Unit_KiloNewto" Vector__XXX
 SG_ EPB_Status_02  : 317|3@1+ (1.000000,0.000000) [0.000000|7.000000] "" Motor_BEV
 SG_ EPB_Status  : 320|2@1+ (1.000000,0.000000) [0.000000|3.000000] "" Vector__XXX
 SG_ ESP_Status_Bremsentemp_02  : 322|2@1+ (1.000000,0.000000) [0.000000|3.000000] "" Motor_BEV

BU_:  Airbag BAP_Tester ICAS1_Gateway ICAS1_KommunikationsServer LE1 LE2 Motor_BEV Schaltbetaetigung

BO_ 192 EM1_01: 32 LE1
 SG_ EM1_01_CRC  : 0|8@1+ (1.000000,0.000000) [0.000000|255.000000] "" ICAS1_Gateway Motor_BEV
 SG_ EM1_01_BZ  : 8|4@1+ (1.000000,0.000000) [0.000000|15.000000] "" ICAS1_Gateway Motor_BEV
 SG_ EM1_Istmodus  : 12|4@1+ (1.000000,0.000000) [0.000000|15.000000] "" ICAS1_Gateway Motor_BEV
 SG_ EM1_IstMoment  : 16|12@1+ (0.500000,-1023.000000) [-1023.000000|1023.500000] "Unit_NewtoMeter" ICAS1_Gateway Motor_BEV
 SG_ EM1_Moment_AR_Eingriff  : 28|12@1+ (0.500000,-1023.000000) [-1023.000000|1023.500000] "Unit_NewtoMeter" ICAS1_Gateway Motor_BEV
 SG_ EM1_IstDrehzahl  : 40|15@1+ (1.000000,-10000.000000) [-10000.000000|22765.000000] "Unit_MinutInver" ICAS1_Gateway Motor_BEV
 SG_ EM1_AR_aktiv  : 55|1@1+ (1.000000,0.000000) [0.000000|1.000000] "" ICAS1_Gateway Motor_BEV
 SG_ EM1_IstSpannung  : 56|12@1+ (0.250000,0.000000) [0.000000|1023.250000] "Unit_Volt" ICAS1_Gateway Motor_BEV
 SG_ EM1_Strom_HV  : 68|12@1+ (0.500000,-1023.000000) [-1023.000000|1023.500000] "Unit_Amper" ICAS1_Gateway Motor_BEV
 SG_ EM1_Max_Moment  : 80|11@1+ (1.000000,-1023.000000) [-1023.000000|1022.000000] "Unit_NewtoMeter" ICAS1_Gateway Motor_BEV
 SG_ EM1_ErwGrenzen_aktiv  : 91|1@1+ (1.000000,0.000000) [0.000000|1.000000] "" ICAS1_Gateway Motor_BEV
 SG_ EM1_Min_Moment  : 92|11@1+ (1.000000,-1023.000000) [-1023.000000|1022.000000] "Unit_NewtoMeter" ICAS1_Gateway Motor_BEV
 SG_ EM1_Fehler_ElAntriebAbschaltung  : 103|1@1+ (1.000000,0.000000) [0.000000|1.000000] "" ICAS1_Gateway Motor_BEV
 SG_ EM1_Max_Moment_Lim  : 104|11@1+ (1.000000,-1023.000000) [-1023.000000|1022.000000] "Unit_NewtoMeter" ICAS1_Gateway Motor_BEV
 SG_ EM1_Fehler_Notabschaltung  : 115|1@1+ (1.000000,0.000000) [0.000000|1.000000] "" ICAS1_Gateway Motor_BEV
 SG_ EM1_Min_Moment_Lim  : 116|11@1+ (1.000000,-1023.000000) [-1023.000000|1022.000000] "Unit_NewtoMeter" ICAS1_Gateway Motor_BEV
 SG_ EM1_Status_DrzEingriff  : 127|2@1+ (1.000000,0.000000) [0.000000|3.000000] "" ICAS1_Gateway Motor_BEV
 SG_ EM1_Mom_DrzEingriff  : 129|11@1+ (1.000000,-1023.000000) [-1023.000000|1022.000000] "Unit_NewtoMeter" ICAS1_Gateway Motor_BEV

BO_ 2463978673 EM1_02: 32 LE1
 SG_ EM1_Status_Spgfreiheit  : 12|2@1+ (1.000000,0.000000) [0.000000|3.000000] "" Motor_BEV
 SG_ EM1_Status_EoHVL  : 14|2@1+ (1.000000,0.000000) [0.000000|3.000000] "" Motor_BEV
 SG_ EM1_Max_LeistungMech_Sockel  : 16|13@1+ (200.000000,-819000.000000) [-819000.000000|818800.000000] "Unit_Watt" Vector__XXX
 SG_ EM1_Max_Moment_Sockel  : 29|11@1+ (1.000000,-1023.000000) [-1023.000000|1022.000000] "Unit_NewtoMeter" Vector__XXX
 SG_ EM1_Min_LeistungMech_Sockel  : 40|13@1+ (200.000000,-819000.000000) [-819000.000000|818800.000000] "Unit_Watt" Vector__XXX
 SG_ EM1_Min_Moment_Sockel  : 53|11@1+ (1.000000,-1023.000000) [-1023.000000|1022.000000] "Unit_NewtoMeter" Vector__XXX
 SG_ EM1_PerfInd_MaxLeistung  : 64|10@1+ (0.200000,0.000000) [0.000000|200.000000] "Unit_PerCent" Motor_BEV
 SG_ EM1_PerfInd_MaxMoment  : 74|10@1+ (0.200000,0.000000) [0.000000|200.000000] "Unit_PerCent" Motor_BEV
 SG_ EM1_AnlernenElMotor_Anf  : 84|1@1+ (1.000000,0.000000) [0.000000|1.000000] "" Motor_BEV
 SG_ EM1_OBD_Lampe_Anf  : 85|1@1+ (1.000000,0.000000) [0.000000|1.000000] "" Motor_BEV
 SG_ EM1_Generator_Moment  : 86|10@1+ (1.000000,0.000000) [0.000000|1021.000000] "Unit_NewtoMeter" Motor_BEV
 SG_ EM1_PerfInd_Temperatur  : 96|8@1+ (0.800000,0.000000) [0.000000|200.000000] "Unit_PerCent" Motor_BEV
 SG_ EM1_MaxZul_Drehzahl  : 104|8@1+ (80.000000,0.000000) [0.000000|20240.000000] "Unit_RevPerMinute" Motor_BEV
 SG_ EM1_Min_Moment_Gesamt  : 112|11@1+ (1.000000,-1023.000000) [-1023.000000|1022.000000] "Unit_NewtoMeter" Motor_BEV
 SG_ EM1_Fehlerlampe_Anf  : 123|1@1+ (1.000000,0.000000) [0.000000|1.000000] "" Motor_BEV
 SG_ EM1_Max_Moment_Gesamt  : 124|11@1+ (1.000000,-1023.000000) [-1023.000000|1022.000000] "Unit_NewtoMeter" Motor_BEV
 SG_ EM1_Warnlampe_Anf  : 135|1@1+ (1.000000,0.000000) [0.000000|1.000000] "" Motor_BEV
 SG_ EM1_Rekuperation  : 136|15@1+ (10.000000,0.000000) [0.000000|327670.000000] "Unit_WattSecond" Motor_BEV
 SG_ EM1_Rekuperation_Ueberlauf  : 151|1@1+ (1.000000,0.000000) [0.000000|1.000000] "" Motor_BEV
 SG_ EM1_Verbrauch  : 152|15@1+ (10.000000,0.000000) [0.000000|327670.000000] "Unit_WattSecond" Motor_BEV
 SG_ EM1_Verbrauch_Ueberlauf  : 167|1@1+ (1.000000,0.000000) [0.000000|1.000000] "" Motor_BEV
 SG_ EM1_Fehler_AE  : 168|1@1+ (1.000000,0.000000) [0.000000|1.000000] "" Motor_BEV
 SG_ EM1_Fehler_Leistungsred  : 169|1@1+ (1.000000,0.000000) [0.000000|1.000000] "" Motor_BEV
 SG_ EM1_Fehler_ElAntriebFreilauf  : 170|1@1+ (1.000000,0.000000) [0.000000|1.000000] "" Motor_BEV
 SG_ EM1_PWR_SollVolumenstrom  : 171|6@1+ (0.500000,0.000000) [0.000000|30.500000] "Unit_LiterPerMinut" Motor_BEV

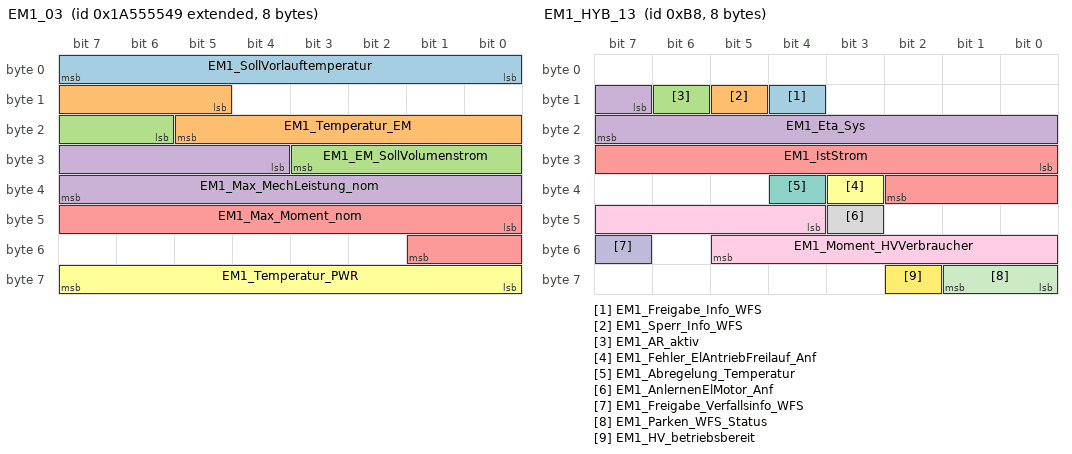
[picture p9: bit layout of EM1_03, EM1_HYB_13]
BO_ 2589283657 EM1_03: 8 LE1
 SG_ EM1_SollVorlauftemperatur  : 0|8@1+ (0.500000,-40.000000) [-40.000000|86.500000] "Unit_DegreCelsi" Motor_BEV
 SG_ EM1_Temperatur_EM  : 13|9@1+ (1.000000,-40.000000) [-40.000000|469.000000] "Unit_DegreCelsi" ICAS1_Gateway Motor_BEV
 SG_ EM1_EM_SollVolumenstrom  : 22|6@1+ (0.500000,0.000000) [0.000000|30.500000] "Unit_LiterPerMinut" Motor_BEV
 SG_ EM1_Max_MechLeistung_nom  : 28|12@1+ (200.000000,0.000000) [0.000000|818600.000000] "Unit_Watt" Motor_BEV
 SG_ EM1_Max_Moment_nom  : 40|10@1+ (1.000000,0.000000) [0.000000|1021.000000] "Unit_NewtoMeter" Motor_BEV
 SG_ EM1_Temperatur_PWR  : 56|8@1+ (1.000000,-40.000000) [-40.000000|213.000000] "Unit_DegreCelsi" ICAS1_Gateway Motor_BEV

BO_ 184 EM1_HYB_13: 8 LE1
 SG_ EM1_Freigabe_Info_WFS  : 12|1@1+ (1.000000,0.000000) [0.000000|1.000000] "" ICAS1_Gateway Motor_BEV
 SG_ EM1_Sperr_Info_WFS  : 13|1@1+ (1.000000,0.000000) [0.000000|1.000000] "" ICAS1_Gateway Motor_BEV
 SG_ EM1_AR_aktiv  : 14|1@1+ (1.000000,0.000000) [0.000000|1.000000] "" ICAS1_Gateway
 SG_ EM1_Eta_Sys  : 15|9@1+ (0.200000,0.000000) [0.000000|101.800000] "Unit_PerCent" ICAS1_Gateway
 SG_ EM1_IstStrom  : 24|11@1+ (1.000000,-1023.000000) [-1023.000000|1022.000000] "Unit_Amper" ICAS1_Gateway
 SG_ EM1_Fehler_ElAntriebFreilauf_Anf  : 35|1@1+ (1.000000,0.000000) [0.000000|1.000000] "" ICAS1_Gateway
 SG_ EM1_Abregelung_Temperatur  : 36|1@1+ (1.000000,0.000000) [0.000000|1.000000] "" ICAS1_Gateway
 SG_ EM1_AnlernenElMotor_Anf  : 43|1@1+ (1.000000,0.000000) [0.000000|1.000000] "" ICAS1_Gateway
 SG_ EM1_Moment_HVVerbraucher  : 44|10@1+ (1.000000,-511.000000) [-511.000000|511.000000] "Unit_NewtoMeter" ICAS1_Gateway
 SG_ EM1_Freigabe_Verfallsinfo_WFS  : 55|1@1+ (1.000000,0.000000) [0.000000|1.000000] "" ICAS1_Gateway Motor_BEV
 SG_ EM1_Parken_WFS_Status  : 56|2@1+ (1.000000,0.000000) [0.000000|3.000000] "" ICAS1_Gateway
 SG_ EM1_HV_betriebsbereit  : 58|1@1+ (1.000000,0.000000) [0.000000|1.000000] "" ICAS1_Gateway

BO_ 2527679712 EM1_HYB_27: 8 LE1
 SG_ EM1_RtmWarnKommunikation  : 12|3@1+ (1.000000,0.000000) [0.000000|7.000000] "" Vector__XXX
 SG_ EM1_RtmWarnUeberdrehzahl  : 15|3@1+ (1.000000,0.000000) [0.000000|7.000000] "" ICAS1_Gateway
 SG_ EM1_RtmWarnUeberstrom  : 18|3@1+ (1.000000,0.000000) [0.000000|7.000000] "" ICAS1_Gateway
 SG_ EM1_RtmWarnTempEM  : 21|3@1+ (1.000000,0.000000) [0.000000|7.000000] "" ICAS1_Gateway
 SG_ EM1_RtmWarnTempPWR  : 24|3@1+ (1.000000,0.000000) [0.000000|7.000000] "" ICAS1_Gateway

BO_ 193 EM2_01: 32 LE2
 SG_ EM2_01_CRC  : 0|8@1+ (1.000000,0.000000) [0.000000|255.000000] "" Motor_BEV
 SG_ EM2_01_BZ  : 8|4@1+ (1.000000,0.000000) [0.000000|15.000000] "" Motor_BEV
 SG_ EM2_Istmodus  : 12|4@1+ (1.000000,0.000000) [0.000000|15.000000] "" ICAS1_Gateway Motor_BEV
 SG_ EM2_IstMoment  : 16|12@1+ (0.500000,-1023.000000) [-1023.000000|1023.500000] "Unit_NewtoMeter" ICAS1_Gateway Motor_BEV
 SG_ EM2_Moment_AR_Eingriff  : 28|12@1+ (0.500000,-1023.000000) [-1023.000000|1023.500000] "Unit_NewtoMeter" Motor_BEV
 SG_ EM2_IstDrehzahl  : 40|15@1+ (1.000000,-10000.000000) [-10000.000000|22765.000000] "Unit_MinutInver" ICAS1_Gateway Motor_BEV
 SG_ EM2_AR_aktiv  : 55|1@1+ (1.000000,0.000000) [0.000000|1.000000] "" Motor_BEV
 SG_ EM2_IstSpannung  : 56|12@1+ (0.250000,0.000000) [0.000000|1023.250000] "Unit_Volt" ICAS1_Gateway Motor_BEV
 SG_ EM2_Strom_HV  : 68|12@1+ (0.500000,-1023.000000) [-1023.000000|1023.500000] "Unit_Amper" ICAS1_Gateway Motor_BEV
 SG_ EM2_Max_Moment  : 80|11@1+ (1.000000,-1023.000000) [-1023.000000|1022.000000] "Unit_NewtoMeter" Motor_BEV
 SG_ EM2_ErwGrenzen_aktiv  : 91|1@1+ (1.000000,0.000000) [0.000000|1.000000] "" Motor_BEV
 SG_ EM2_Min_Moment  : 92|11@1+ (1.000000,-1023.000000) [-1023.000000|1022.000000] "Unit_NewtoMeter" Motor_BEV
 SG_ EM2_Fehler_ElAntriebAbschaltung  : 103|1@1+ (1.000000,0.000000) [0.000000|1.000000] "" Motor_BEV
 SG_ EM2_Max_Moment_Lim  : 104|11@1+ (1.000000,-1023.000000) [-1023.000000|1022.000000] "Unit_NewtoMeter" Motor_BEV
 SG_ EM2_Fehler_Notabschaltung  : 115|1@1+ (1.000000,0.000000) [0.000000|1.000000] "" ICAS1_Gateway Motor_BEV
 SG_ EM2_Min_Moment_Lim  : 116|11@1+ (1.000000,-1023.000000) [-1023.000000|1022.000000] "Unit_NewtoMeter" Motor_BEV
 SG_ EM2_Status_DrzEingriff  : 127|2@1+ (1.000000,0.000000) [0.000000|3.000000] "" ICAS1_Gateway Motor_BEV
 SG_ EM2_Mom_DrzEingriff  : 129|11@1+ (1.000000,-1023.000000) [-1023.000000|1022.000000] "Unit_NewtoMeter" Motor_BEV

BO_ 2463978674 EM2_02: 32 LE2
 SG_ EM2_Status_Spgfreiheit  : 12|2@1+ (1.000000,0.000000) [0.000000|3.000000] "" Motor_BEV
 SG_ EM2_Status_EoHVL  : 14|2@1+ (1.000000,0.000000) [0.000000|3.000000] "" Motor_BEV
 SG_ EM2_Max_LeistungMech_Sockel  : 16|13@1+ (200.000000,-819000.000000) [-819000.000000|818800.000000] "Unit_Watt" Vector__XXX
 SG_ EM2_Max_Moment_Sockel  : 29|11@1+ (1.000000,-1023.000000) [-1023.000000|1022.000000] "Unit_NewtoMeter" Vector__XXX
 SG_ EM2_Min_LeistungMech_Sockel  : 40|13@1+ (200.000000,-819000.000000) [-819000.000000|818800.000000] "Unit_Watt" Vector__XXX
 SG_ EM2_Min_Moment_Sockel  : 53|11@1+ (1.000000,-1023.000000) [-1023.000000|1022.000000] "Unit_NewtoMeter" Vector__XXX
 SG_ EM2_PerfInd_MaxLeistung  : 64|10@1+ (0.200000,0.000000) [0.000000|200.000000] "Unit_PerCent" Motor_BEV
 SG_ EM2_PerfInd_MaxMoment  : 74|10@1+ (0.200000,0.000000) [0.000000|200.000000] "Unit_PerCent" Motor_BEV
 SG_ EM2_AnlernenElMotor_Anf  : 84|1@1+ (1.000000,0.000000) [0.000000|1.000000] "" Motor_BEV
 SG_ EM2_OBD_Lampe_Anf  : 85|1@1+ (1.000000,0.000000) [0.000000|1.000000] "" Motor_BEV
 SG_ EM2_Generator_Moment  : 86|10@1+ (1.000000,0.000000) [0.000000|1021.000000] "Unit_NewtoMeter" Motor_BEV
 SG_ EM2_PerfInd_Temperatur  : 96|8@1+ (0.800000,0.000000) [0.000000|200.000000] "Unit_PerCent" Motor_BEV
 SG_ EM2_MaxZul_Drehzahl  : 104|8@1+ (80.000000,0.000000) [0.000000|20240.000000] "Unit_RevPerMinute" Motor_BEV
 SG_ EM2_Min_Moment_Gesamt  : 112|11@1+ (1.000000,-1023.000000) [-1023.000000|1022.000000] "Unit_NewtoMeter" Motor_BEV
 SG_ EM2_Fehlerlampe_Anf  : 123|1@1+ (1.000000,0.000000) [0.000000|1.000000] "" Motor_BEV
 SG_ EM2_Max_Moment_Gesamt  : 124|11@1+ (1.000000,-1023.000000) [-1023.000000|1022.000000] "Unit_NewtoMeter" Motor_BEV
 SG_ EM2_Warnlampe_Anf  : 135|1@1+ (1.000000,0.000000) [0.000000|1.000000] "" Motor_BEV
 SG_ EM2_Rekuperation  : 136|15@1+ (10.000000,0.000000) [0.000000|327670.000000] "Unit_WattSecond" Motor_BEV
 SG_ EM2_Rekuperation_Ueberlauf  : 151|1@1+ (1.000000,0.000000) [0.000000|1.000000] "" Motor_BEV
 SG_ EM2_Verbrauch  : 152|15@1+ (10.000000,0.000000) [0.000000|327670.000000] "Unit_WattSecond" Motor_BEV
 SG_ EM2_Verbrauch_Ueberlauf  : 167|1@1+ (1.000000,0.000000) [0.000000|1.000000] "" Motor_BEV
 SG_ EM2_Fehler_AE  : 168|1@1+ (1.000000,0.000000) [0.000000|1.000000] "" Motor_BEV
 SG_ EM2_Fehler_Leistungsred  : 169|1@1+ (1.000000,0.000000) [0.000000|1.000000] "" Motor_BEV
 SG_ EM2_Fehler_ElAntriebFreilauf  : 170|1@1+ (1.000000,0.000000) [0.000000|1.000000] "" Motor_BEV
 SG_ EM2_PWR_SollVolumenstrom  : 171|6@1+ (0.500000,0.000000) [0.000000|30.500000] "Unit_LiterPerMinut" Motor_BEV

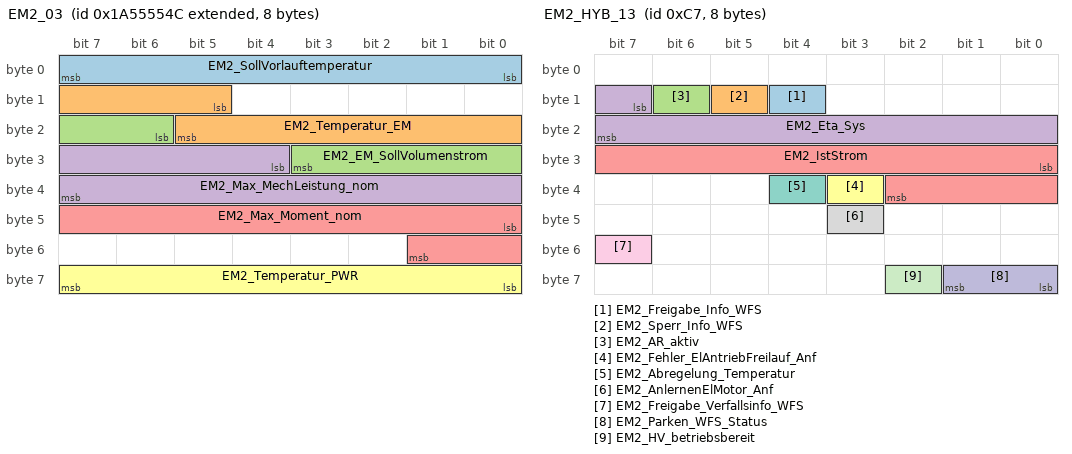
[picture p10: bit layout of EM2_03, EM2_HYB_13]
BO_ 2589283660 EM2_03: 8 LE2
 SG_ EM2_SollVorlauftemperatur  : 0|8@1+ (0.500000,-40.000000) [-40.000000|86.500000] "Unit_DegreCelsi" Motor_BEV
 SG_ EM2_Temperatur_EM  : 13|9@1+ (1.000000,-40.000000) [-40.000000|469.000000] "Unit_DegreCelsi" ICAS1_Gateway Motor_BEV
 SG_ EM2_EM_SollVolumenstrom  : 22|6@1+ (0.500000,0.000000) [0.000000|30.500000] "Unit_LiterPerMinut" Motor_BEV
 SG_ EM2_Max_MechLeistung_nom  : 28|12@1+ (200.000000,0.000000) [0.000000|818600.000000] "Unit_Watt" Motor_BEV
 SG_ EM2_Max_Moment_nom  : 40|10@1+ (1.000000,0.000000) [0.000000|1021.000000] "Unit_NewtoMeter" Motor_BEV
 SG_ EM2_Temperatur_PWR  : 56|8@1+ (1.000000,-40.000000) [-40.000000|213.000000] "Unit_DegreCelsi" ICAS1_Gateway Motor_BEV

BO_ 199 EM2_HYB_13: 8 LE2
 SG_ EM2_Freigabe_Info_WFS  : 12|1@1+ (1.000000,0.000000) [0.000000|1.000000] "" ICAS1_Gateway Motor_BEV
 SG_ EM2_Sperr_Info_WFS  : 13|1@1+ (1.000000,0.000000) [0.000000|1.000000] "" ICAS1_Gateway Motor_BEV
 SG_ EM2_AR_aktiv  : 14|1@1+ (1.000000,0.000000) [0.000000|1.000000] "" ICAS1_Gateway
 SG_ EM2_Eta_Sys  : 15|9@1+ (0.200000,0.000000) [0.000000|101.800000] "Unit_PerCent" ICAS1_Gateway
 SG_ EM2_IstStrom  : 24|11@1+ (1.000000,-1023.000000) [-1023.000000|1022.000000] "Unit_Amper" ICAS1_Gateway
 SG_ EM2_Fehler_ElAntriebFreilauf_Anf  : 35|1@1+ (1.000000,0.000000) [0.000000|1.000000] "" ICAS1_Gateway
 SG_ EM2_Abregelung_Temperatur  : 36|1@1+ (1.000000,0.000000) [0.000000|1.000000] "" ICAS1_Gateway
 SG_ EM2_AnlernenElMotor_Anf  : 43|1@1+ (1.000000,0.000000) [0.000000|1.000000] "" ICAS1_Gateway
 SG_ EM2_Freigabe_Verfallsinfo_WFS  : 55|1@1+ (1.000000,0.000000) [0.000000|1.000000] "" ICAS1_Gateway Motor_BEV
 SG_ EM2_Parken_WFS_Status  : 56|2@1+ (1.000000,0.000000) [0.000000|3.000000] "" ICAS1_Gateway
 SG_ EM2_HV_betriebsbereit  : 58|1@1+ (1.000000,0.000000) [0.000000|1.000000] "" ICAS1_Gateway

BO_ 2527679713 EM2_HYB_27: 8 LE2
 SG_ EM2_RtmWarnKommunikation  : 12|3@1+ (1.000000,0.000000) [0.000000|7.000000] "" Vector__XXX
 SG_ EM2_RtmWarnUeberdrehzahl  : 15|3@1+ (1.000000,0.000000) [0.000000|7.000000] "" ICAS1_Gateway
 SG_ EM2_RtmWarnUeberstrom  : 18|3@1+ (1.000000,0.000000) [0.000000|7.000000] "" ICAS1_Gateway
 SG_ EM2_RtmWarnTempEM  : 21|3@1+ (1.000000,0.000000) [0.000000|7.000000] "" ICAS1_Gateway
 SG_ EM2_RtmWarnTempPWR  : 24|3@1+ (1.000000,0.000000) [0.000000|7.000000] "" ICAS1_Gateway

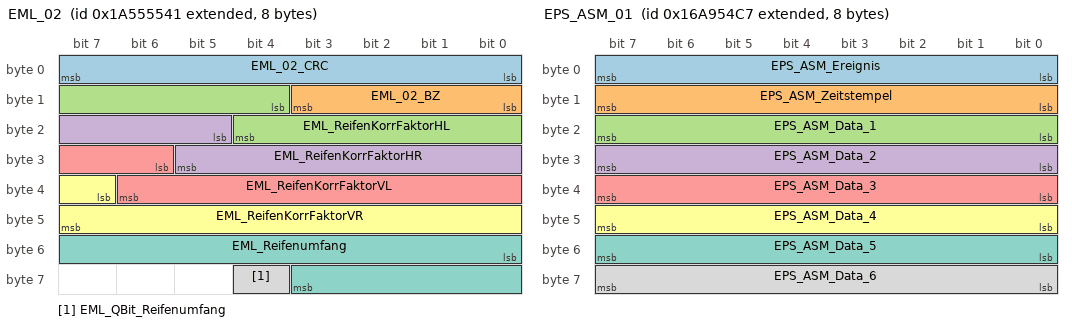
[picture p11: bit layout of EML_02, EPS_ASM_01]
BO_ 2589283649 EML_02: 8 ICAS1_Gateway
 SG_ EML_02_CRC  : 0|8@1+ (1.000000,0.000000) [0.000000|255.000000] "" Vector__XXX
 SG_ EML_02_BZ  : 8|4@1+ (1.000000,0.000000) [0.000000|15.000000] "" Vector__XXX
 SG_ EML_ReifenKorrFaktorHL  : 12|9@1+ (0.000488,0.850000) [0.850000|1.098535] "" Vector__XXX
 SG_ EML_ReifenKorrFaktorHR  : 21|9@1+ (0.000488,0.850000) [0.850000|1.098535] "" Vector__XXX
 SG_ EML_ReifenKorrFaktorVL  : 30|9@1+ (0.000488,0.850000) [0.850000|1.098535] "" Vector__XXX
 SG_ EML_ReifenKorrFaktorVR  : 39|9@1+ (0.000488,0.850000) [0.850000|1.098535] "" Vector__XXX
 SG_ EML_Reifenumfang  : 48|12@1+ (1.000000,0.000000) [0.000000|4095.000000] "Unit_MilliMeter" Motor_BEV
 SG_ EML_QBit_Reifenumfang  : 60|1@1+ (1.000000,0.000000) [0.000000|1.000000] "" Motor_BEV

BO_ 608 EML_07: 8 ICAS1_Gateway
 SG_ EML_AnzeigeGeschw  : 54|10@1+ (0.320000,0.000000) [0.000000|325.120000] "Unit_KiloMeterPerHour" Motor_BEV

BO_ 2589283751 Entfernungen_01: 8 ICAS1_KommunikationsServer
 SG_ KBI_Kilometerstand_HiRes_meter  : 32|32@1+ (1.000000,0.000000) [0.000000|4294967295.000000] "Unit_Meter" Motor_BEV

BO_ 2527679687 EPS_ASM_01: 8 ICAS1_Gateway
 SG_ EPS_ASM_Ereignis  : 0|8@1+ (1.000000,0.000000) [1.000000|254.000000] "Unit_None" Airbag
 SG_ EPS_ASM_Zeitstempel  : 8|8@1+ (0.080000,0.000000) [0.000000|20.320000] "Unit_None" Airbag
 SG_ EPS_ASM_Data_1  : 16|8@1+ (1.000000,0.000000) [0.000000|255.000000] "Unit_None" Airbag
 SG_ EPS_ASM_Data_2  : 24|8@1+ (1.000000,0.000000) [0.000000|255.000000] "Unit_None" Airbag
 SG_ EPS_ASM_Data_3  : 32|8@1+ (1.000000,0.000000) [0.000000|255.000000] "Unit_None" Airbag
 SG_ EPS_ASM_Data_4  : 40|8@1+ (1.000000,0.000000) [0.000000|255.000000] "Unit_None" Airbag
 SG_ EPS_ASM_Data_5  : 48|8@1+ (1.000000,0.000000) [0.000000|255.000000] "Unit_None" Airbag
 SG_ EPS_ASM_Data_6  : 56|8@1+ (1.000000,0.000000) [0.000000|255.000000] "Unit_None" Airbag

BO_ 258 ESC_50: 48 ICAS1_Gateway
 SG_ ESC_50_CRC  : 0|8@1+ (1.000000,0.000000) [0.000000|255.000000] "" Motor_BEV
 SG_ ESC_50_BZ  : 8|4@1+ (1.000000,0.000000) [0.000000|15.000000] "" Motor_BEV
 SG_ ESP_QBit_Gierrate  : 12|1@1+ (1.000000,0.000000) [0.000000|1.000000] "" Motor_BEV
 SG_ ESP_QBit_Laengsbeschl  : 13|1@1+ (1.000000,0.000000) [0.000000|1.000000] "" Motor_BEV
 SG_ ESP_QBit_Querb  : 14|1@1+ (1.000000,0.000000) [0.000000|1.000000] "" Motor_BEV
 SG_ ESP_Querbeschleunigung  : 16|8@1+ (0.010000,-1.270000) [-1.270000|1.270000] "Unit_ForceOfGravi" Airbag Motor_BEV
 SG_ ESP_Laengsbeschl  : 24|10@1+ (0.031250,-16.000000) [-16.000000|15.906250] "Unit_MeterPerSeconSquar" Airbag Motor_BEV
 SG_ ESC_Motorstartverzoegerung  : 34|1@1+ (1.000000,0.000000) [0.000000|1.000000] "" Vector__XXX
 SG_ ESC_SeitenwindAssistent_Eingriff  : 35|1@1+ (1.000000,0.000000) [0.000000|1.000000] "" Vector__XXX
 SG_ ESP_Anschleppstart_Freigabe  : 36|2@1+ (1.000000,0.000000) [0.000000|3.000000] "" Vector__XXX
 SG_ ESC_Unterdruckmangel_erkannt  : 38|1@1+ (1.000000,0.000000) [0.000000|1.000000] "" Vector__XXX
 SG_ ESP_Gierrate  : 40|14@1+ (0.010000,0.000000) [0.000000|163.820000] "Unit_DegreOfArcPerSecon" Airbag Motor_BEV
 SG_ ESP_VZ_Gierrate  : 54|1@1+ (1.000000,0.000000) [0.000000|1.000000] "" Airbag Motor_BEV
 SG_ ESP_Notbremsanzeige  : 55|1@1+ (1.000000,0.000000) [0.000000|1.000000] "" Vector__XXX
 SG_ ESP_SpannungsAnf  : 56|1@1+ (1.000000,0.000000) [0.000000|1.000000] "" Vector__XXX
 SG_ ESP_PLA_Abbruch  : 57|3@1+ (1.000000,0.000000) [0.000000|7.000000] "" Vector__XXX
 SG_ ESP_Status_ESP_PLA  : 60|4@1+ (1.000000,0.000000) [0.000000|15.000000] "" Vector__XXX
 SG_ ESP_QBit_Bremsdruck  : 76|1@1+ (1.000000,0.000000) [0.000000|1.000000] "" Airbag Motor_BEV
 SG_ ESP_QBit_Fahrer_bremst  : 77|1@1+ (1.000000,0.000000) [0.000000|1.000000] "" Vector__XXX
 SG_ ESP_Schwelle_Unterdruck  : 78|2@1+ (1.000000,0.000000) [0.000000|3.000000] "" Vector__XXX
 SG_ ESP_Bremsdruck  : 80|10@1+ (0.300000,-30.000000) [-30.000000|276.600000] "Unit_Bar" Motor_BEV
 SG_ ESP_Fahrer_bremst  : 90|1@1+ (1.000000,0.000000) [0.000000|1.000000] "" Vector__XXX
 SG_ ESP_Verz_TSK_aktiv  : 91|1@1+ (1.000000,0.000000) [0.000000|1.000000] "" Vector__XXX
 SG_ ESP_Lenkeingriff_ADS  : 92|1@1+ (1.000000,0.000000) [0.000000|1.000000] "" Vector__XXX
 SG_ ESP_Konsistenz_TSK  : 93|1@1+ (1.000000,0.000000) [0.000000|1.000000] "" Vector__XXX
 SG_ ESP_Bremsruck_AWV2  : 94|1@1+ (1.000000,0.000000) [0.000000|1.000000] "" Vector__XXX
 SG_ ESP_Konsistenz_AWV2  : 95|1@1+ (1.000000,0.000000) [0.000000|1.000000] "" Vector__XXX
 SG_ ECD_Fehler  : 96|1@1+ (1.000000,0.000000) [0.000000|1.000000] "" Vector__XXX
 SG_ ECD_nicht_verfuegbar  : 97|1@1+ (1.000000,0.000000) [0.000000|1.000000] "" Vector__XXX
 SG_ ESP_Status_Bremsentemp  : 98|1@1+ (1.000000,0.000000) [0.000000|1.000000] "" Vector__XXX
 SG_ ESP_Autohold_Standby  : 99|1@1+ (1.000000,0.000000) [0.000000|1.000000] "" Vector__XXX
 SG_ ESP_HDC_Standby  : 100|1@1+ (1.000000,0.000000) [0.000000|1.000000] "" Vector__XXX
 SG_ ESP_HBA_aktiv  : 101|1@1+ (1.000000,0.000000) [0.000000|1.000000] "" Vector__XXX
 SG_ ESP_Prefill_ausgeloest  : 102|1@1+ (1.000000,0.000000) [0.000000|1.000000] "" Vector__XXX
 SG_ ESP_Rueckwaertsfahrt_erkannt  : 103|1@1+ (1.000000,0.000000) [0.000000|1.000000] "" Vector__XXX
 SG_ ESP_Status_Anfahrhilfe  : 104|1@1+ (1.000000,0.000000) [0.000000|1.000000] "" Vector__XXX
 SG_ ESP_HDC_aktiv  : 105|1@1+ (1.000000,0.000000) [0.000000|1.000000] "" Vector__XXX
 SG_ ESP_StartStopp_Info  : 106|2@1+ (1.000000,0.000000) [0.000000|3.000000] "" Vector__XXX
 SG_ ESP_Eingr_HL  : 108|1@1+ (1.000000,0.000000) [0.000000|1.000000] "" Vector__XXX
 SG_ ESP_Eingr_HR  : 109|1@1+ (1.000000,0.000000) [0.000000|1.000000] "" Vector__XXX
 SG_ ESP_Eingr_VL  : 110|1@1+ (1.000000,0.000000) [0.000000|1.000000] "" Vector__XXX
 SG_ ESP_Eingr_VR  : 111|1@1+ (1.000000,0.000000) [0.000000|1.000000] "" Vector__XXX
 SG_ ESP_BKV_Unterdruck  : 112|8@1+ (4.000000,0.000000) [4.000000|1012.000000] "Unit_MilliBar" Vector__XXX
 SG_ ESP_Autohold_aktiv  : 120|1@1+ (1.000000,0.000000) [0.000000|1.000000] "" Vector__XXX
 SG_ ESP_FStatus_Anfahrhilfe  : 121|1@1+ (1.000000,0.000000) [0.000000|1.000000] "" Vector__XXX
 SG_ ESP_Verz_EPB_aktiv  : 122|1@1+ (1.000000,0.000000) [0.000000|1.000000] "" Vector__XXX
 SG_ ECD_Bremslicht  : 123|1@1+ (1.000000,0.000000) [0.000000|1.000000] "" Motor_BEV
 SG_ ESP_Verzoeg_EPB_verf  : 124|1@1+ (1.000000,0.000000) [0.000000|1.000000] "" Vector__XXX
 SG_ ESP_Status_Bremsdruck  : 125|1@1+ (1.000000,0.000000) [0.000000|1.000000] "" Vector__XXX
 SG_ ESP_Anforderung_EPB  : 126|2@1+ (1.000000,0.000000) [0.000000|3.000000] "" Vector__XXX
 SG_ ESP_ANB_CM_Rueckk_Umsetz  : 140|1@1+ (1.000000,0.000000) [0.000000|1.000000] "" Vector__XXX
 SG_ ESP_Konsistenz_ACC_Botschaft  : 141|1@1+ (1.000000,0.000000) [0.000000|1.000000] "" Vector__XXX
 SG_ ESP_Stillstandsphase_erschoepft  : 142|1@1+ (1.000000,0.000000) [0.000000|1.000000] "" Vector__XXX
 SG_ ESP_ZT_Rueckk_Umsetz  : 143|1@1+ (1.000000,0.000000) [0.000000|1.000000] "" Vector__XXX
 SG_ ESP_Tuerkontakt_Fahrertuer  : 144|1@1+ (1.000000,0.000000) [0.000000|1.000000] "" Vector__XXX
 SG_ ESP_Abrutschen_Stillstand  : 146|1@1+ (1.000000,0.000000) [0.000000|1.000000] "" Vector__XXX
 SG_ ESP_Fahrer_tritt_ZBR_Schw  : 147|1@1+ (1.000000,0.000000) [0.000000|1.000000] "" Vector__XXX
 SG_ ESP_QBit_v_ref  : 169|1@1+ (1.000000,0.000000) [0.000000|1.000000] "" Vector__XXX
 SG_ ESP_v_ref_Fahrtrichtung  : 170|2@1+ (1.000000,0.000000) [0.000000|3.000000] "" Motor_BEV
 SG_ ESC_Bremsdruckgradient  : 172|8@1+ (10.000000,0.000000) [0.000000|2500.000000] "Unit_BarPerSecon" Vector__XXX
 SG_ ESP_v_ref  : 180|12@1+ (0.125000,0.000000) [0.000000|511.500000] "Unit_KiloMeterPerHour" Airbag Motor_BEV
 SG_ ESC_Hydr_Fkt_aktiv  : 223|2@1+ (1.000000,0.000000) [0.000000|3.000000] "" Vector__XXX
 SG_ ESC_QBit_Fahrerbremswunsch  : 225|1@1+ (1.000000,0.000000) [0.000000|1.000000] "" Motor_BEV
 SG_ ESC_Fahrerbremswunsch  : 226|10@1+ (0.300000,-30.000000) [-30.000000|276.600000] "Unit_Bar" Motor_BEV
 SG_ ESCGeneratorSollMoment  : 236|12@1+ (3.000000,-12279.000000) [-12279.000000|0.000000] "" Motor_BEV
 SG_ ESC_Raddruck_max  : 248|8@1+ (1.000000,0.000000) [0.000000|250.000000] "Unit_Bar" Vector__XXX
 SG_ EPB_QBit_Pedalweg_Kuppl  : 269|1@1+ (1.000000,0.000000) [0.000000|1.000000] "" Vector__XXX
 SG_ EPB_Freig_Verzoeg_Anf  : 271|1@1+ (1.000000,0.000000) [0.000000|1.000000] "" Vector__XXX
 SG_ EPB_Verzoeg_Anf  : 272|8@1+ (0.048000,-7.968000) [-7.968000|4.224000] "Unit_MeterPerSeconSquar" Vector__XXX
 SG_ EPB_Pedalweg_Kuppl  : 288|8@1+ (0.400000,0.000000) [8.000000|92.000000] "Unit_PerCent" Vector__XXX
 SG_ EPB_DAA_Randbed_erf  : 305|1@1+ (1.000000,0.000000) [0.000000|1.000000] "" Vector__XXX
 SG_ EPB_Fehlerstatus_02  : 306|2@1+ (1.000000,0.000000) [0.000000|3.000000] "" Vector__XXX
 SG_ EPB_Schalterposition  : 308|2@1+ (1.000000,0.000000) [0.000000|3.000000] "" Airbag
 SG_ EPB_QBit_Schalterpos  : 310|1@1+ (1.000000,0.000000) [0.000000|1.000000] "" Vector__XXX
 SG_ EPB_Spannkraft  : 312|5@1+ (1.000000,0.000000) [0.000000|29.000000] "Unit_KiloNewto" Vector__XXX
 SG_ EPB_Status_02  : 317|3@1+ (1.000000,0.000000) [0.000000|7.000000] "" Motor_BEV
 SG_ EPB_Status  : 320|2@1+ (1.000000,0.000000) [0.000000|3.000000] "" Vector__XXX
 SG_ ESP_Status_Bremsentemp_02  : 322|2@1+ (1.000000,0.000000) [0.000000|3.000000] "" Motor_BEV

BU_:  Airbag BAP_Tester ICAS1_Gateway ICAS1_KommunikationsServer LE1 LE2 Motor_BEV Schaltbetaetigung

BO_ 192 EM1_01: 32 LE1
 SG_ EM1_01_CRC  : 0|8@1+ (1.000000,0.000000) [0.000000|255.000000] "" ICAS1_Gateway Motor_BEV
 SG_ EM1_01_BZ  : 8|4@1+ (1.000000,0.000000) [0.000000|15.000000] "" ICAS1_Gateway Motor_BEV
 SG_ EM1_Istmodus  : 12|4@1+ (1.000000,0.000000) [0.000000|15.000000] "" ICAS1_Gateway Motor_BEV
 SG_ EM1_IstMoment  : 16|12@1+ (0.500000,-1023.000000) [-1023.000000|1023.500000] "Unit_NewtoMeter" ICAS1_Gateway Motor_BEV
 SG_ EM1_Moment_AR_Eingriff  : 28|12@1+ (0.500000,-1023.000000) [-1023.000000|1023.500000] "Unit_NewtoMeter" ICAS1_Gateway Motor_BEV
 SG_ EM1_IstDrehzahl  : 40|15@1+ (1.000000,-10000.000000) [-10000.000000|22765.000000] "Unit_MinutInver" ICAS1_Gateway Motor_BEV
 SG_ EM1_AR_aktiv  : 55|1@1+ (1.000000,0.000000) [0.000000|1.000000] "" ICAS1_Gateway Motor_BEV
 SG_ EM1_IstSpannung  : 56|12@1+ (0.250000,0.000000) [0.000000|1023.250000] "Unit_Volt" ICAS1_Gateway Motor_BEV
 SG_ EM1_Strom_HV  : 68|12@1+ (0.500000,-1023.000000) [-1023.000000|1023.500000] "Unit_Amper" ICAS1_Gateway Motor_BEV
 SG_ EM1_Max_Moment  : 80|11@1+ (1.000000,-1023.000000) [-1023.000000|1022.000000] "Unit_NewtoMeter" ICAS1_Gateway Motor_BEV
 SG_ EM1_ErwGrenzen_aktiv  : 91|1@1+ (1.000000,0.000000) [0.000000|1.000000] "" ICAS1_Gateway Motor_BEV
 SG_ EM1_Min_Moment  : 92|11@1+ (1.000000,-1023.000000) [-1023.000000|1022.000000] "Unit_NewtoMeter" ICAS1_Gateway Motor_BEV
 SG_ EM1_Fehler_ElAntriebAbschaltung  : 103|1@1+ (1.000000,0.000000) [0.000000|1.000000] "" ICAS1_Gateway Motor_BEV
 SG_ EM1_Max_Moment_Lim  : 104|11@1+ (1.000000,-1023.000000) [-1023.000000|1022.000000] "Unit_NewtoMeter" ICAS1_Gateway Motor_BEV
 SG_ EM1_Fehler_Notabschaltung  : 115|1@1+ (1.000000,0.000000) [0.000000|1.000000] "" ICAS1_Gateway Motor_BEV
 SG_ EM1_Min_Moment_Lim  : 116|11@1+ (1.000000,-1023.000000) [-1023.000000|1022.000000] "Unit_NewtoMeter" ICAS1_Gateway Motor_BEV
 SG_ EM1_Status_DrzEingriff  : 127|2@1+ (1.000000,0.000000) [0.000000|3.000000] "" ICAS1_Gateway Motor_BEV
 SG_ EM1_Mom_DrzEingriff  : 129|11@1+ (1.000000,-1023.000000) [-1023.000000|1022.000000] "Unit_NewtoMeter" ICAS1_Gateway Motor_BEV

BO_ 2463978673 EM1_02: 32 LE1
 SG_ EM1_Status_Spgfreiheit  : 12|2@1+ (1.000000,0.000000) [0.000000|3.000000] "" Motor_BEV
 SG_ EM1_Status_EoHVL  : 14|2@1+ (1.000000,0.000000) [0.000000|3.000000] "" Motor_BEV
 SG_ EM1_Max_LeistungMech_Sockel  : 16|13@1+ (200.000000,-819000.000000) [-819000.000000|818800.000000] "Unit_Watt" Vector__XXX
 SG_ EM1_Max_Moment_Sockel  : 29|11@1+ (1.000000,-1023.000000) [-1023.000000|1022.000000] "Unit_NewtoMeter" Vector__XXX
 SG_ EM1_Min_LeistungMech_Sockel  : 40|13@1+ (200.000000,-819000.000000) [-819000.000000|818800.000000] "Unit_Watt" Vector__XXX
 SG_ EM1_Min_Moment_Sockel  : 53|11@1+ (1.000000,-1023.000000) [-1023.000000|1022.000000] "Unit_NewtoMeter" Vector__XXX
 SG_ EM1_PerfInd_MaxLeistung  : 64|10@1+ (0.200000,0.000000) [0.000000|200.000000] "Unit_PerCent" Motor_BEV
 SG_ EM1_PerfInd_MaxMoment  : 74|10@1+ (0.200000,0.000000) [0.000000|200.000000] "Unit_PerCent" Motor_BEV
 SG_ EM1_AnlernenElMotor_Anf  : 84|1@1+ (1.000000,0.000000) [0.000000|1.000000] "" Motor_BEV
 SG_ EM1_OBD_Lampe_Anf  : 85|1@1+ (1.000000,0.000000) [0.000000|1.000000] "" Motor_BEV
 SG_ EM1_Generator_Moment  : 86|10@1+ (1.000000,0.000000) [0.000000|1021.000000] "Unit_NewtoMeter" Motor_BEV
 SG_ EM1_PerfInd_Temperatur  : 96|8@1+ (0.800000,0.000000) [0.000000|200.000000] "Unit_PerCent" Motor_BEV
 SG_ EM1_MaxZul_Drehzahl  : 104|8@1+ (80.000000,0.000000) [0.000000|20240.000000] "Unit_RevPerMinute" Motor_BEV
 SG_ EM1_Min_Moment_Gesamt  : 112|11@1+ (1.000000,-1023.000000) [-1023.000000|1022.000000] "Unit_NewtoMeter" Motor_BEV
 SG_ EM1_Fehlerlampe_Anf  : 123|1@1+ (1.000000,0.000000) [0.000000|1.000000] "" Motor_BEV
 SG_ EM1_Max_Moment_Gesamt  : 124|11@1+ (1.000000,-1023.000000) [-1023.000000|1022.000000] "Unit_NewtoMeter" Motor_BEV
 SG_ EM1_Warnlampe_Anf  : 135|1@1+ (1.000000,0.000000) [0.000000|1.000000] "" Motor_BEV
 SG_ EM1_Rekuperation  : 136|15@1+ (10.000000,0.000000) [0.000000|327670.000000] "Unit_WattSecond" Motor_BEV
 SG_ EM1_Rekuperation_Ueberlauf  : 151|1@1+ (1.000000,0.000000) [0.000000|1.000000] "" Motor_BEV
 SG_ EM1_Verbrauch  : 152|15@1+ (10.000000,0.000000) [0.000000|327670.000000] "Unit_WattSecond" Motor_BEV
 SG_ EM1_Verbrauch_Ueberlauf  : 167|1@1+ (1.000000,0.000000) [0.000000|1.000000] "" Motor_BEV
 SG_ EM1_Fehler_AE  : 168|1@1+ (1.000000,0.000000) [0.000000|1.000000] "" Motor_BEV
 SG_ EM1_Fehler_Leistungsred  : 169|1@1+ (1.000000,0.000000) [0.000000|1.000000] "" Motor_BEV
 SG_ EM1_Fehler_ElAntriebFreilauf  : 170|1@1+ (1.000000,0.000000) [0.000000|1.000000] "" Motor_BEV
 SG_ EM1_PWR_SollVolumenstrom  : 171|6@1+ (0.500000,0.000000) [0.000000|30.500000] "Unit_LiterPerMinut" Motor_BEV

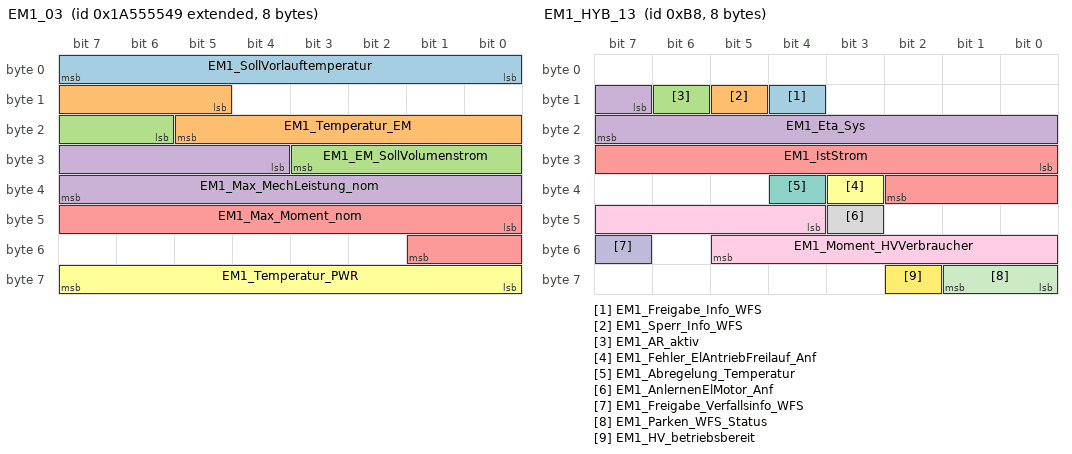
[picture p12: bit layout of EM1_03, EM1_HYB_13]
BO_ 2589283657 EM1_03: 8 LE1
 SG_ EM1_SollVorlauftemperatur  : 0|8@1+ (0.500000,-40.000000) [-40.000000|86.500000] "Unit_DegreCelsi" Motor_BEV
 SG_ EM1_Temperatur_EM  : 13|9@1+ (1.000000,-40.000000) [-40.000000|469.000000] "Unit_DegreCelsi" ICAS1_Gateway Motor_BEV
 SG_ EM1_EM_SollVolumenstrom  : 22|6@1+ (0.500000,0.000000) [0.000000|30.500000] "Unit_LiterPerMinut" Motor_BEV
 SG_ EM1_Max_MechLeistung_nom  : 28|12@1+ (200.000000,0.000000) [0.000000|818600.000000] "Unit_Watt" Motor_BEV
 SG_ EM1_Max_Moment_nom  : 40|10@1+ (1.000000,0.000000) [0.000000|1021.000000] "Unit_NewtoMeter" Motor_BEV
 SG_ EM1_Temperatur_PWR  : 56|8@1+ (1.000000,-40.000000) [-40.000000|213.000000] "Unit_DegreCelsi" ICAS1_Gateway Motor_BEV

BO_ 184 EM1_HYB_13: 8 LE1
 SG_ EM1_Freigabe_Info_WFS  : 12|1@1+ (1.000000,0.000000) [0.000000|1.000000] "" ICAS1_Gateway Motor_BEV
 SG_ EM1_Sperr_Info_WFS  : 13|1@1+ (1.000000,0.000000) [0.000000|1.000000] "" ICAS1_Gateway Motor_BEV
 SG_ EM1_AR_aktiv  : 14|1@1+ (1.000000,0.000000) [0.000000|1.000000] "" ICAS1_Gateway
 SG_ EM1_Eta_Sys  : 15|9@1+ (0.200000,0.000000) [0.000000|101.800000] "Unit_PerCent" ICAS1_Gateway
 SG_ EM1_IstStrom  : 24|11@1+ (1.000000,-1023.000000) [-1023.000000|1022.000000] "Unit_Amper" ICAS1_Gateway
 SG_ EM1_Fehler_ElAntriebFreilauf_Anf  : 35|1@1+ (1.000000,0.000000) [0.000000|1.000000] "" ICAS1_Gateway
 SG_ EM1_Abregelung_Temperatur  : 36|1@1+ (1.000000,0.000000) [0.000000|1.000000] "" ICAS1_Gateway
 SG_ EM1_AnlernenElMotor_Anf  : 43|1@1+ (1.000000,0.000000) [0.000000|1.000000] "" ICAS1_Gateway
 SG_ EM1_Moment_HVVerbraucher  : 44|10@1+ (1.000000,-511.000000) [-511.000000|511.000000] "Unit_NewtoMeter" ICAS1_Gateway
 SG_ EM1_Freigabe_Verfallsinfo_WFS  : 55|1@1+ (1.000000,0.000000) [0.000000|1.000000] "" ICAS1_Gateway Motor_BEV
 SG_ EM1_Parken_WFS_Status  : 56|2@1+ (1.000000,0.000000) [0.000000|3.000000] "" ICAS1_Gateway
 SG_ EM1_HV_betriebsbereit  : 58|1@1+ (1.000000,0.000000) [0.000000|1.000000] "" ICAS1_Gateway

BO_ 2527679712 EM1_HYB_27: 8 LE1
 SG_ EM1_RtmWarnKommunikation  : 12|3@1+ (1.000000,0.000000) [0.000000|7.000000] "" Vector__XXX
 SG_ EM1_RtmWarnUeberdrehzahl  : 15|3@1+ (1.000000,0.000000) [0.000000|7.000000] "" ICAS1_Gateway
 SG_ EM1_RtmWarnUeberstrom  : 18|3@1+ (1.000000,0.000000) [0.000000|7.000000] "" ICAS1_Gateway
 SG_ EM1_RtmWarnTempEM  : 21|3@1+ (1.000000,0.000000) [0.000000|7.000000] "" ICAS1_Gateway
 SG_ EM1_RtmWarnTempPWR  : 24|3@1+ (1.000000,0.000000) [0.000000|7.000000] "" ICAS1_Gateway

BO_ 193 EM2_01: 32 LE2
 SG_ EM2_01_CRC  : 0|8@1+ (1.000000,0.000000) [0.000000|255.000000] "" Motor_BEV
 SG_ EM2_01_BZ  : 8|4@1+ (1.000000,0.000000) [0.000000|15.000000] "" Motor_BEV
 SG_ EM2_Istmodus  : 12|4@1+ (1.000000,0.000000) [0.000000|15.000000] "" ICAS1_Gateway Motor_BEV
 SG_ EM2_IstMoment  : 16|12@1+ (0.500000,-1023.000000) [-1023.000000|1023.500000] "Unit_NewtoMeter" ICAS1_Gateway Motor_BEV
 SG_ EM2_Moment_AR_Eingriff  : 28|12@1+ (0.500000,-1023.000000) [-1023.000000|1023.500000] "Unit_NewtoMeter" Motor_BEV
 SG_ EM2_IstDrehzahl  : 40|15@1+ (1.000000,-10000.000000) [-10000.000000|22765.000000] "Unit_MinutInver" ICAS1_Gateway Motor_BEV
 SG_ EM2_AR_aktiv  : 55|1@1+ (1.000000,0.000000) [0.000000|1.000000] "" Motor_BEV
 SG_ EM2_IstSpannung  : 56|12@1+ (0.250000,0.000000) [0.000000|1023.250000] "Unit_Volt" ICAS1_Gateway Motor_BEV
 SG_ EM2_Strom_HV  : 68|12@1+ (0.500000,-1023.000000) [-1023.000000|1023.500000] "Unit_Amper" ICAS1_Gateway Motor_BEV
 SG_ EM2_Max_Moment  : 80|11@1+ (1.000000,-1023.000000) [-1023.000000|1022.000000] "Unit_NewtoMeter" Motor_BEV
 SG_ EM2_ErwGrenzen_aktiv  : 91|1@1+ (1.000000,0.000000) [0.000000|1.000000] "" Motor_BEV
 SG_ EM2_Min_Moment  : 92|11@1+ (1.000000,-1023.000000) [-1023.000000|1022.000000] "Unit_NewtoMeter" Motor_BEV
 SG_ EM2_Fehler_ElAntriebAbschaltung  : 103|1@1+ (1.000000,0.000000) [0.000000|1.000000] "" Motor_BEV
 SG_ EM2_Max_Moment_Lim  : 104|11@1+ (1.000000,-1023.000000) [-1023.000000|1022.000000] "Unit_NewtoMeter" Motor_BEV
 SG_ EM2_Fehler_Notabschaltung  : 115|1@1+ (1.000000,0.000000) [0.000000|1.000000] "" ICAS1_Gateway Motor_BEV
 SG_ EM2_Min_Moment_Lim  : 116|11@1+ (1.000000,-1023.000000) [-1023.000000|1022.000000] "Unit_NewtoMeter" Motor_BEV
 SG_ EM2_Status_DrzEingriff  : 127|2@1+ (1.000000,0.000000) [0.000000|3.000000] "" ICAS1_Gateway Motor_BEV
 SG_ EM2_Mom_DrzEingriff  : 129|11@1+ (1.000000,-1023.000000) [-1023.000000|1022.000000] "Unit_NewtoMeter" Motor_BEV

BO_ 2463978674 EM2_02: 32 LE2
 SG_ EM2_Status_Spgfreiheit  : 12|2@1+ (1.000000,0.000000) [0.000000|3.000000] "" Motor_BEV
 SG_ EM2_Status_EoHVL  : 14|2@1+ (1.000000,0.000000) [0.000000|3.000000] "" Motor_BEV
 SG_ EM2_Max_LeistungMech_Sockel  : 16|13@1+ (200.000000,-819000.000000) [-819000.000000|818800.000000] "Unit_Watt" Vector__XXX
 SG_ EM2_Max_Moment_Sockel  : 29|11@1+ (1.000000,-1023.000000) [-1023.000000|1022.000000] "Unit_NewtoMeter" Vector__XXX
 SG_ EM2_Min_LeistungMech_Sockel  : 40|13@1+ (200.000000,-819000.000000) [-819000.000000|818800.000000] "Unit_Watt" Vector__XXX
 SG_ EM2_Min_Moment_Sockel  : 53|11@1+ (1.000000,-1023.000000) [-1023.000000|1022.000000] "Unit_NewtoMeter" Vector__XXX
 SG_ EM2_PerfInd_MaxLeistung  : 64|10@1+ (0.200000,0.000000) [0.000000|200.000000] "Unit_PerCent" Motor_BEV
 SG_ EM2_PerfInd_MaxMoment  : 74|10@1+ (0.200000,0.000000) [0.000000|200.000000] "Unit_PerCent" Motor_BEV
 SG_ EM2_AnlernenElMotor_Anf  : 84|1@1+ (1.000000,0.000000) [0.000000|1.000000] "" Motor_BEV
 SG_ EM2_OBD_Lampe_Anf  : 85|1@1+ (1.000000,0.000000) [0.000000|1.000000] "" Motor_BEV
 SG_ EM2_Generator_Moment  : 86|10@1+ (1.000000,0.000000) [0.000000|1021.000000] "Unit_NewtoMeter" Motor_BEV
 SG_ EM2_PerfInd_Temperatur  : 96|8@1+ (0.800000,0.000000) [0.000000|200.000000] "Unit_PerCent" Motor_BEV
 SG_ EM2_MaxZul_Drehzahl  : 104|8@1+ (80.000000,0.000000) [0.000000|20240.000000] "Unit_RevPerMinute" Motor_BEV
 SG_ EM2_Min_Moment_Gesamt  : 112|11@1+ (1.000000,-1023.000000) [-1023.000000|1022.000000] "Unit_NewtoMeter" Motor_BEV
 SG_ EM2_Fehlerlampe_Anf  : 123|1@1+ (1.000000,0.000000) [0.000000|1.000000] "" Motor_BEV
 SG_ EM2_Max_Moment_Gesamt  : 124|11@1+ (1.000000,-1023.000000) [-1023.000000|1022.000000] "Unit_NewtoMeter" Motor_BEV
 SG_ EM2_Warnlampe_Anf  : 135|1@1+ (1.000000,0.000000) [0.000000|1.000000] "" Motor_BEV
 SG_ EM2_Rekuperation  : 136|15@1+ (10.000000,0.000000) [0.000000|327670.000000] "Unit_WattSecond" Motor_BEV
 SG_ EM2_Rekuperation_Ueberlauf  : 151|1@1+ (1.000000,0.000000) [0.000000|1.000000] "" Motor_BEV
 SG_ EM2_Verbrauch  : 152|15@1+ (10.000000,0.000000) [0.000000|327670.000000] "Unit_WattSecond" Motor_BEV
 SG_ EM2_Verbrauch_Ueberlauf  : 167|1@1+ (1.000000,0.000000) [0.000000|1.000000] "" Motor_BEV
 SG_ EM2_Fehler_AE  : 168|1@1+ (1.000000,0.000000) [0.000000|1.000000] "" Motor_BEV
 SG_ EM2_Fehler_Leistungsred  : 169|1@1+ (1.000000,0.000000) [0.000000|1.000000] "" Motor_BEV
 SG_ EM2_Fehler_ElAntriebFreilauf  : 170|1@1+ (1.000000,0.000000) [0.000000|1.000000] "" Motor_BEV
 SG_ EM2_PWR_SollVolumenstrom  : 171|6@1+ (0.500000,0.000000) [0.000000|30.500000] "Unit_LiterPerMinut" Motor_BEV

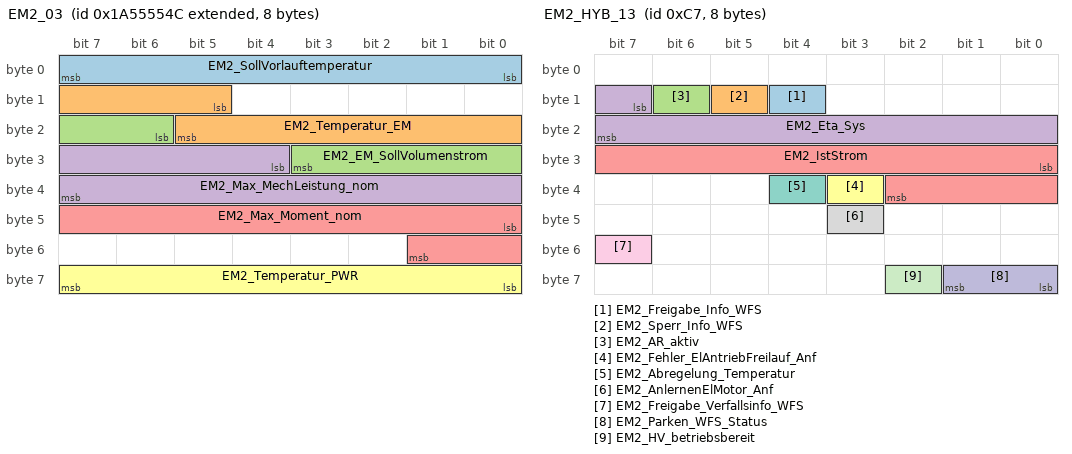
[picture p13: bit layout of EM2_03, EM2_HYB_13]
BO_ 2589283660 EM2_03: 8 LE2
 SG_ EM2_SollVorlauftemperatur  : 0|8@1+ (0.500000,-40.000000) [-40.000000|86.500000] "Unit_DegreCelsi" Motor_BEV
 SG_ EM2_Temperatur_EM  : 13|9@1+ (1.000000,-40.000000) [-40.000000|469.000000] "Unit_DegreCelsi" ICAS1_Gateway Motor_BEV
 SG_ EM2_EM_SollVolumenstrom  : 22|6@1+ (0.500000,0.000000) [0.000000|30.500000] "Unit_LiterPerMinut" Motor_BEV
 SG_ EM2_Max_MechLeistung_nom  : 28|12@1+ (200.000000,0.000000) [0.000000|818600.000000] "Unit_Watt" Motor_BEV
 SG_ EM2_Max_Moment_nom  : 40|10@1+ (1.000000,0.000000) [0.000000|1021.000000] "Unit_NewtoMeter" Motor_BEV
 SG_ EM2_Temperatur_PWR  : 56|8@1+ (1.000000,-40.000000) [-40.000000|213.000000] "Unit_DegreCelsi" ICAS1_Gateway Motor_BEV

BO_ 199 EM2_HYB_13: 8 LE2
 SG_ EM2_Freigabe_Info_WFS  : 12|1@1+ (1.000000,0.000000) [0.000000|1.000000] "" ICAS1_Gateway Motor_BEV
 SG_ EM2_Sperr_Info_WFS  : 13|1@1+ (1.000000,0.000000) [0.000000|1.000000] "" ICAS1_Gateway Motor_BEV
 SG_ EM2_AR_aktiv  : 14|1@1+ (1.000000,0.000000) [0.000000|1.000000] "" ICAS1_Gateway
 SG_ EM2_Eta_Sys  : 15|9@1+ (0.200000,0.000000) [0.000000|101.800000] "Unit_PerCent" ICAS1_Gateway
 SG_ EM2_IstStrom  : 24|11@1+ (1.000000,-1023.000000) [-1023.000000|1022.000000] "Unit_Amper" ICAS1_Gateway
 SG_ EM2_Fehler_ElAntriebFreilauf_Anf  : 35|1@1+ (1.000000,0.000000) [0.000000|1.000000] "" ICAS1_Gateway
 SG_ EM2_Abregelung_Temperatur  : 36|1@1+ (1.000000,0.000000) [0.000000|1.000000] "" ICAS1_Gateway
 SG_ EM2_AnlernenElMotor_Anf  : 43|1@1+ (1.000000,0.000000) [0.000000|1.000000] "" ICAS1_Gateway
 SG_ EM2_Freigabe_Verfallsinfo_WFS  : 55|1@1+ (1.000000,0.000000) [0.000000|1.000000] "" ICAS1_Gateway Motor_BEV
 SG_ EM2_Parken_WFS_Status  : 56|2@1+ (1.000000,0.000000) [0.000000|3.000000] "" ICAS1_Gateway
 SG_ EM2_HV_betriebsbereit  : 58|1@1+ (1.000000,0.000000) [0.000000|1.000000] "" ICAS1_Gateway

BO_ 2527679713 EM2_HYB_27: 8 LE2
 SG_ EM2_RtmWarnKommunikation  : 12|3@1+ (1.000000,0.000000) [0.000000|7.000000] "" Vector__XXX
 SG_ EM2_RtmWarnUeberdrehzahl  : 15|3@1+ (1.000000,0.000000) [0.000000|7.000000] "" ICAS1_Gateway
 SG_ EM2_RtmWarnUeberstrom  : 18|3@1+ (1.000000,0.000000) [0.000000|7.000000] "" ICAS1_Gateway
 SG_ EM2_RtmWarnTempEM  : 21|3@1+ (1.000000,0.000000) [0.000000|7.000000] "" ICAS1_Gateway
 SG_ EM2_RtmWarnTempPWR  : 24|3@1+ (1.000000,0.000000) [0.000000|7.000000] "" ICAS1_Gateway

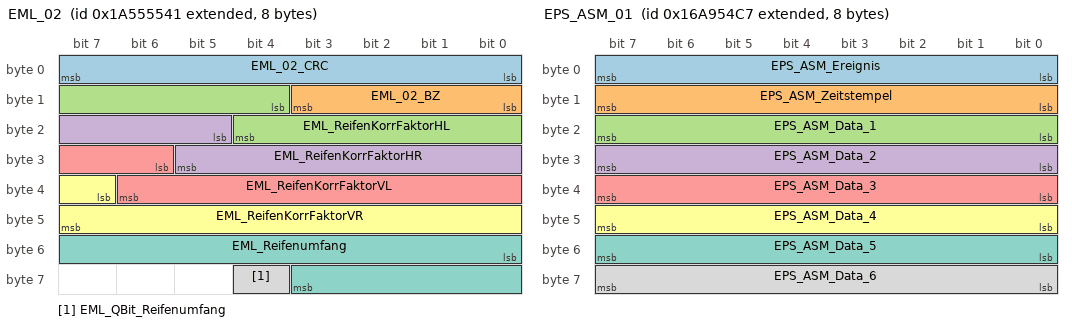
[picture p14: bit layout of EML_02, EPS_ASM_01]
BO_ 2589283649 EML_02: 8 ICAS1_Gateway
 SG_ EML_02_CRC  : 0|8@1+ (1.000000,0.000000) [0.000000|255.000000] "" Vector__XXX
 SG_ EML_02_BZ  : 8|4@1+ (1.000000,0.000000) [0.000000|15.000000] "" Vector__XXX
 SG_ EML_ReifenKorrFaktorHL  : 12|9@1+ (0.000488,0.850000) [0.850000|1.098535] "" Vector__XXX
 SG_ EML_ReifenKorrFaktorHR  : 21|9@1+ (0.000488,0.850000) [0.850000|1.098535] "" Vector__XXX
 SG_ EML_ReifenKorrFaktorVL  : 30|9@1+ (0.000488,0.850000) [0.850000|1.098535] "" Vector__XXX
 SG_ EML_ReifenKorrFaktorVR  : 39|9@1+ (0.000488,0.850000) [0.850000|1.098535] "" Vector__XXX
 SG_ EML_Reifenumfang  : 48|12@1+ (1.000000,0.000000) [0.000000|4095.000000] "Unit_MilliMeter" Motor_BEV
 SG_ EML_QBit_Reifenumfang  : 60|1@1+ (1.000000,0.000000) [0.000000|1.000000] "" Motor_BEV

BO_ 608 EML_07: 8 ICAS1_Gateway
 SG_ EML_AnzeigeGeschw  : 54|10@1+ (0.320000,0.000000) [0.000000|325.120000] "Unit_KiloMeterPerHour" Motor_BEV

BO_ 2589283751 Entfernungen_01: 8 ICAS1_KommunikationsServer
 SG_ KBI_Kilometerstand_HiRes_meter  : 32|32@1+ (1.000000,0.000000) [0.000000|4294967295.000000] "Unit_Meter" Motor_BEV

BO_ 2527679687 EPS_ASM_01: 8 ICAS1_Gateway
 SG_ EPS_ASM_Ereignis  : 0|8@1+ (1.000000,0.000000) [1.000000|254.000000] "Unit_None" Airbag
 SG_ EPS_ASM_Zeitstempel  : 8|8@1+ (0.080000,0.000000) [0.000000|20.320000] "Unit_None" Airbag
 SG_ EPS_ASM_Data_1  : 16|8@1+ (1.000000,0.000000) [0.000000|255.000000] "Unit_None" Airbag
 SG_ EPS_ASM_Data_2  : 24|8@1+ (1.000000,0.000000) [0.000000|255.000000] "Unit_None" Airbag
 SG_ EPS_ASM_Data_3  : 32|8@1+ (1.000000,0.000000) [0.000000|255.000000] "Unit_None" Airbag
 SG_ EPS_ASM_Data_4  : 40|8@1+ (1.000000,0.000000) [0.000000|255.000000] "Unit_None" Airbag
 SG_ EPS_ASM_Data_5  : 48|8@1+ (1.000000,0.000000) [0.000000|255.000000] "Unit_None" Airbag
 SG_ EPS_ASM_Data_6  : 56|8@1+ (1.000000,0.000000) [0.000000|255.000000] "Unit_None" Airbag

BO_ 258 ESC_50: 48 ICAS1_Gateway
 SG_ ESC_50_CRC  : 0|8@1+ (1.000000,0.000000) [0.000000|255.000000] "" Motor_BEV
 SG_ ESC_50_BZ  : 8|4@1+ (1.000000,0.000000) [0.000000|15.000000] "" Motor_BEV
 SG_ ESP_QBit_Gierrate  : 12|1@1+ (1.000000,0.000000) [0.000000|1.000000] "" Motor_BEV
 SG_ ESP_QBit_Laengsbeschl  : 13|1@1+ (1.000000,0.000000) [0.000000|1.000000] "" Motor_BEV
 SG_ ESP_QBit_Querb  : 14|1@1+ (1.000000,0.000000) [0.000000|1.000000] "" Motor_BEV
 SG_ ESP_Querbeschleunigung  : 16|8@1+ (0.010000,-1.270000) [-1.270000|1.270000] "Unit_ForceOfGravi" Airbag Motor_BEV
 SG_ ESP_Laengsbeschl  : 24|10@1+ (0.031250,-16.000000) [-16.000000|15.906250] "Unit_MeterPerSeconSquar" Airbag Motor_BEV
 SG_ ESC_Motorstartverzoegerung  : 34|1@1+ (1.000000,0.000000) [0.000000|1.000000] "" Vector__XXX
 SG_ ESC_SeitenwindAssistent_Eingriff  : 35|1@1+ (1.000000,0.000000) [0.000000|1.000000] "" Vector__XXX
 SG_ ESP_Anschleppstart_Freigabe  : 36|2@1+ (1.000000,0.000000) [0.000000|3.000000] "" Vector__XXX
 SG_ ESC_Unterdruckmangel_erkannt  : 38|1@1+ (1.000000,0.000000) [0.000000|1.000000] "" Vector__XXX
 SG_ ESP_Gierrate  : 40|14@1+ (0.010000,0.000000) [0.000000|163.820000] "Unit_DegreOfArcPerSecon" Airbag Motor_BEV
 SG_ ESP_VZ_Gierrate  : 54|1@1+ (1.000000,0.000000) [0.000000|1.000000] "" Airbag Motor_BEV
 SG_ ESP_Notbremsanzeige  : 55|1@1+ (1.000000,0.000000) [0.000000|1.000000] "" Vector__XXX
 SG_ ESP_SpannungsAnf  : 56|1@1+ (1.000000,0.000000) [0.000000|1.000000] "" Vector__XXX
 SG_ ESP_PLA_Abbruch  : 57|3@1+ (1.000000,0.000000) [0.000000|7.000000] "" Vector__XXX
 SG_ ESP_Status_ESP_PLA  : 60|4@1+ (1.000000,0.000000) [0.000000|15.000000] "" Vector__XXX
 SG_ ESP_QBit_Bremsdruck  : 76|1@1+ (1.000000,0.000000) [0.000000|1.000000] "" Airbag Motor_BEV
 SG_ ESP_QBit_Fahrer_bremst  : 77|1@1+ (1.000000,0.000000) [0.000000|1.000000] "" Vector__XXX
 SG_ ESP_Schwelle_Unterdruck  : 78|2@1+ (1.000000,0.000000) [0.000000|3.000000] "" Vector__XXX
 SG_ ESP_Bremsdruck  : 80|10@1+ (0.300000,-30.000000) [-30.000000|276.600000] "Unit_Bar" Motor_BEV
 SG_ ESP_Fahrer_bremst  : 90|1@1+ (1.000000,0.000000) [0.000000|1.000000] "" Vector__XXX
 SG_ ESP_Verz_TSK_aktiv  : 91|1@1+ (1.000000,0.000000) [0.000000|1.000000] "" Vector__XXX
 SG_ ESP_Lenkeingriff_ADS  : 92|1@1+ (1.000000,0.000000) [0.000000|1.000000] "" Vector__XXX
 SG_ ESP_Konsistenz_TSK  : 93|1@1+ (1.000000,0.000000) [0.000000|1.000000] "" Vector__XXX
 SG_ ESP_Bremsruck_AWV2  : 94|1@1+ (1.000000,0.000000) [0.000000|1.000000] "" Vector__XXX
 SG_ ESP_Konsistenz_AWV2  : 95|1@1+ (1.000000,0.000000) [0.000000|1.000000] "" Vector__XXX
 SG_ ECD_Fehler  : 96|1@1+ (1.000000,0.000000) [0.000000|1.000000] "" Vector__XXX
 SG_ ECD_nicht_verfuegbar  : 97|1@1+ (1.000000,0.000000) [0.000000|1.000000] "" Vector__XXX
 SG_ ESP_Status_Bremsentemp  : 98|1@1+ (1.000000,0.000000) [0.000000|1.000000] "" Vector__XXX
 SG_ ESP_Autohold_Standby  : 99|1@1+ (1.000000,0.000000) [0.000000|1.000000] "" Vector__XXX
 SG_ ESP_HDC_Standby  : 100|1@1+ (1.000000,0.000000) [0.000000|1.000000] "" Vector__XXX
 SG_ ESP_HBA_aktiv  : 101|1@1+ (1.000000,0.000000) [0.000000|1.000000] "" Vector__XXX
 SG_ ESP_Prefill_ausgeloest  : 102|1@1+ (1.000000,0.000000) [0.000000|1.000000] "" Vector__XXX
 SG_ ESP_Rueckwaertsfahrt_erkannt  : 103|1@1+ (1.000000,0.000000) [0.000000|1.000000] "" Vector__XXX
 SG_ ESP_Status_Anfahrhilfe  : 104|1@1+ (1.000000,0.000000) [0.000000|1.000000] "" Vector__XXX
 SG_ ESP_HDC_aktiv  : 105|1@1+ (1.000000,0.000000) [0.000000|1.000000] "" Vector__XXX
 SG_ ESP_StartStopp_Info  : 106|2@1+ (1.000000,0.000000) [0.000000|3.000000] "" Vector__XXX
 SG_ ESP_Eingr_HL  : 108|1@1+ (1.000000,0.000000) [0.000000|1.000000] "" Vector__XXX
 SG_ ESP_Eingr_HR  : 109|1@1+ (1.000000,0.000000) [0.000000|1.000000] "" Vector__XXX
 SG_ ESP_Eingr_VL  : 110|1@1+ (1.000000,0.000000) [0.000000|1.000000] "" Vector__XXX
 SG_ ESP_Eingr_VR  : 111|1@1+ (1.000000,0.000000) [0.000000|1.000000] "" Vector__XXX
 SG_ ESP_BKV_Unterdruck  : 112|8@1+ (4.000000,0.000000) [4.000000|1012.000000] "Unit_MilliBar" Vector__XXX
 SG_ ESP_Autohold_aktiv  : 120|1@1+ (1.000000,0.000000) [0.000000|1.000000] "" Vector__XXX
 SG_ ESP_FStatus_Anfahrhilfe  : 121|1@1+ (1.000000,0.000000) [0.000000|1.000000] "" Vector__XXX
 SG_ ESP_Verz_EPB_aktiv  : 122|1@1+ (1.000000,0.000000) [0.000000|1.000000] "" Vector__XXX
 SG_ ECD_Bremslicht  : 123|1@1+ (1.000000,0.000000) [0.000000|1.000000] "" Motor_BEV
 SG_ ESP_Verzoeg_EPB_verf  : 124|1@1+ (1.000000,0.000000) [0.000000|1.000000] "" Vector__XXX
 SG_ ESP_Status_Bremsdruck  : 125|1@1+ (1.000000,0.000000) [0.000000|1.000000] "" Vector__XXX
 SG_ ESP_Anforderung_EPB  : 126|2@1+ (1.000000,0.000000) [0.000000|3.000000] "" Vector__XXX
 SG_ ESP_ANB_CM_Rueckk_Umsetz  : 140|1@1+ (1.000000,0.000000) [0.000000|1.000000] "" Vector__XXX
 SG_ ESP_Konsistenz_ACC_Botschaft  : 141|1@1+ (1.000000,0.000000) [0.000000|1.000000] "" Vector__XXX
 SG_ ESP_Stillstandsphase_erschoepft  : 142|1@1+ (1.000000,0.000000) [0.000000|1.000000] "" Vector__XXX
 SG_ ESP_ZT_Rueckk_Umsetz  : 143|1@1+ (1.000000,0.000000) [0.000000|1.000000] "" Vector__XXX
 SG_ ESP_Tuerkontakt_Fahrertuer  : 144|1@1+ (1.000000,0.000000) [0.000000|1.000000] "" Vector__XXX
 SG_ ESP_Abrutschen_Stillstand  : 146|1@1+ (1.000000,0.000000) [0.000000|1.000000] "" Vector__XXX
 SG_ ESP_Fahrer_tritt_ZBR_Schw  : 147|1@1+ (1.000000,0.000000) [0.000000|1.000000] "" Vector__XXX
 SG_ ESP_QBit_v_ref  : 169|1@1+ (1.000000,0.000000) [0.000000|1.000000] "" Vector__XXX
 SG_ ESP_v_ref_Fahrtrichtung  : 170|2@1+ (1.000000,0.000000) [0.000000|3.000000] "" Motor_BEV
 SG_ ESC_Bremsdruckgradient  : 172|8@1+ (10.000000,0.000000) [0.000000|2500.000000] "Unit_BarPerSecon" Vector__XXX
 SG_ ESP_v_ref  : 180|12@1+ (0.125000,0.000000) [0.000000|511.500000] "Unit_KiloMeterPerHour" Airbag Motor_BEV
 SG_ ESC_Hydr_Fkt_aktiv  : 223|2@1+ (1.000000,0.000000) [0.000000|3.000000] "" Vector__XXX
 SG_ ESC_QBit_Fahrerbremswunsch  : 225|1@1+ (1.000000,0.000000) [0.000000|1.000000] "" Motor_BEV
 SG_ ESC_Fahrerbremswunsch  : 226|10@1+ (0.300000,-30.000000) [-30.000000|276.600000] "Unit_Bar" Motor_BEV
 SG_ ESCGeneratorSollMoment  : 236|12@1+ (3.000000,-12279.000000) [-12279.000000|0.000000] "" Motor_BEV
 SG_ ESC_Raddruck_max  : 248|8@1+ (1.000000,0.000000) [0.000000|250.000000] "Unit_Bar" Vector__XXX
 SG_ EPB_QBit_Pedalweg_Kuppl  : 269|1@1+ (1.000000,0.000000) [0.000000|1.000000] "" Vector__XXX
 SG_ EPB_Freig_Verzoeg_Anf  : 271|1@1+ (1.000000,0.000000) [0.000000|1.000000] "" Vector__XXX
 SG_ EPB_Verzoeg_Anf  : 272|8@1+ (0.048000,-7.968000) [-7.968000|4.224000] "Unit_MeterPerSeconSquar" Vector__XXX
 SG_ EPB_Pedalweg_Kuppl  : 288|8@1+ (0.400000,0.000000) [8.000000|92.000000] "Unit_PerCent" Vector__XXX
 SG_ EPB_DAA_Randbed_erf  : 305|1@1+ (1.000000,0.000000) [0.000000|1.000000] "" Vector__XXX
 SG_ EPB_Fehlerstatus_02  : 306|2@1+ (1.000000,0.000000) [0.000000|3.000000] "" Vector__XXX
 SG_ EPB_Schalterposition  : 308|2@1+ (1.000000,0.000000) [0.000000|3.000000] "" Airbag
 SG_ EPB_QBit_Schalterpos  : 310|1@1+ (1.000000,0.000000) [0.000000|1.000000] "" Vector__XXX
 SG_ EPB_Spannkraft  : 312|5@1+ (1.000000,0.000000) [0.000000|29.000000] "Unit_KiloNewto" Vector__XXX
 SG_ EPB_Status_02  : 317|3@1+ (1.000000,0.000000) [0.000000|7.000000] "" Motor_BEV
 SG_ EPB_Status  : 320|2@1+ (1.000000,0.000000) [0.000000|3.000000] "" Vector__XXX
 SG_ ESP_Status_Bremsentemp_02  : 322|2@1+ (1.000000,0.000000) [0.000000|3.000000] "" Motor_BEV

BU_:  Airbag BAP_Tester ICAS1_Gateway ICAS1_KommunikationsServer LE1 LE2 Motor_BEV Schaltbetaetigung

BO_ 192 EM1_01: 32 LE1
 SG_ EM1_01_CRC  : 0|8@1+ (1.000000,0.000000) [0.000000|255.000000] "" ICAS1_Gateway Motor_BEV
 SG_ EM1_01_BZ  : 8|4@1+ (1.000000,0.000000) [0.000000|15.000000] "" ICAS1_Gateway Motor_BEV
 SG_ EM1_Istmodus  : 12|4@1+ (1.000000,0.000000) [0.000000|15.000000] "" ICAS1_Gateway Motor_BEV
 SG_ EM1_IstMoment  : 16|12@1+ (0.500000,-1023.000000) [-1023.000000|1023.500000] "Unit_NewtoMeter" ICAS1_Gateway Motor_BEV
 SG_ EM1_Moment_AR_Eingriff  : 28|12@1+ (0.500000,-1023.000000) [-1023.000000|1023.500000] "Unit_NewtoMeter" ICAS1_Gateway Motor_BEV
 SG_ EM1_IstDrehzahl  : 40|15@1+ (1.000000,-10000.000000) [-10000.000000|22765.000000] "Unit_MinutInver" ICAS1_Gateway Motor_BEV
 SG_ EM1_AR_aktiv  : 55|1@1+ (1.000000,0.000000) [0.000000|1.000000] "" ICAS1_Gateway Motor_BEV
 SG_ EM1_IstSpannung  : 56|12@1+ (0.250000,0.000000) [0.000000|1023.250000] "Unit_Volt" ICAS1_Gateway Motor_BEV
 SG_ EM1_Strom_HV  : 68|12@1+ (0.500000,-1023.000000) [-1023.000000|1023.500000] "Unit_Amper" ICAS1_Gateway Motor_BEV
 SG_ EM1_Max_Moment  : 80|11@1+ (1.000000,-1023.000000) [-1023.000000|1022.000000] "Unit_NewtoMeter" ICAS1_Gateway Motor_BEV
 SG_ EM1_ErwGrenzen_aktiv  : 91|1@1+ (1.000000,0.000000) [0.000000|1.000000] "" ICAS1_Gateway Motor_BEV
 SG_ EM1_Min_Moment  : 92|11@1+ (1.000000,-1023.000000) [-1023.000000|1022.000000] "Unit_NewtoMeter" ICAS1_Gateway Motor_BEV
 SG_ EM1_Fehler_ElAntriebAbschaltung  : 103|1@1+ (1.000000,0.000000) [0.000000|1.000000] "" ICAS1_Gateway Motor_BEV
 SG_ EM1_Max_Moment_Lim  : 104|11@1+ (1.000000,-1023.000000) [-1023.000000|1022.000000] "Unit_NewtoMeter" ICAS1_Gateway Motor_BEV
 SG_ EM1_Fehler_Notabschaltung  : 115|1@1+ (1.000000,0.000000) [0.000000|1.000000] "" ICAS1_Gateway Motor_BEV
 SG_ EM1_Min_Moment_Lim  : 116|11@1+ (1.000000,-1023.000000) [-1023.000000|1022.000000] "Unit_NewtoMeter" ICAS1_Gateway Motor_BEV
 SG_ EM1_Status_DrzEingriff  : 127|2@1+ (1.000000,0.000000) [0.000000|3.000000] "" ICAS1_Gateway Motor_BEV
 SG_ EM1_Mom_DrzEingriff  : 129|11@1+ (1.000000,-1023.000000) [-1023.000000|1022.000000] "Unit_NewtoMeter" ICAS1_Gateway Motor_BEV

BO_ 2463978673 EM1_02: 32 LE1
 SG_ EM1_Status_Spgfreiheit  : 12|2@1+ (1.000000,0.000000) [0.000000|3.000000] "" Motor_BEV
 SG_ EM1_Status_EoHVL  : 14|2@1+ (1.000000,0.000000) [0.000000|3.000000] "" Motor_BEV
 SG_ EM1_Max_LeistungMech_Sockel  : 16|13@1+ (200.000000,-819000.000000) [-819000.000000|818800.000000] "Unit_Watt" Vector__XXX
 SG_ EM1_Max_Moment_Sockel  : 29|11@1+ (1.000000,-1023.000000) [-1023.000000|1022.000000] "Unit_NewtoMeter" Vector__XXX
 SG_ EM1_Min_LeistungMech_Sockel  : 40|13@1+ (200.000000,-819000.000000) [-819000.000000|818800.000000] "Unit_Watt" Vector__XXX
 SG_ EM1_Min_Moment_Sockel  : 53|11@1+ (1.000000,-1023.000000) [-1023.000000|1022.000000] "Unit_NewtoMeter" Vector__XXX
 SG_ EM1_PerfInd_MaxLeistung  : 64|10@1+ (0.200000,0.000000) [0.000000|200.000000] "Unit_PerCent" Motor_BEV
 SG_ EM1_PerfInd_MaxMoment  : 74|10@1+ (0.200000,0.000000) [0.000000|200.000000] "Unit_PerCent" Motor_BEV
 SG_ EM1_AnlernenElMotor_Anf  : 84|1@1+ (1.000000,0.000000) [0.000000|1.000000] "" Motor_BEV
 SG_ EM1_OBD_Lampe_Anf  : 85|1@1+ (1.000000,0.000000) [0.000000|1.000000] "" Motor_BEV
 SG_ EM1_Generator_Moment  : 86|10@1+ (1.000000,0.000000) [0.000000|1021.000000] "Unit_NewtoMeter" Motor_BEV
 SG_ EM1_PerfInd_Temperatur  : 96|8@1+ (0.800000,0.000000) [0.000000|200.000000] "Unit_PerCent" Motor_BEV
 SG_ EM1_MaxZul_Drehzahl  : 104|8@1+ (80.000000,0.000000) [0.000000|20240.000000] "Unit_RevPerMinute" Motor_BEV
 SG_ EM1_Min_Moment_Gesamt  : 112|11@1+ (1.000000,-1023.000000) [-1023.000000|1022.000000] "Unit_NewtoMeter" Motor_BEV
 SG_ EM1_Fehlerlampe_Anf  : 123|1@1+ (1.000000,0.000000) [0.000000|1.000000] "" Motor_BEV
 SG_ EM1_Max_Moment_Gesamt  : 124|11@1+ (1.000000,-1023.000000) [-1023.000000|1022.000000] "Unit_NewtoMeter" Motor_BEV
 SG_ EM1_Warnlampe_Anf  : 135|1@1+ (1.000000,0.000000) [0.000000|1.000000] "" Motor_BEV
 SG_ EM1_Rekuperation  : 136|15@1+ (10.000000,0.000000) [0.000000|327670.000000] "Unit_WattSecond" Motor_BEV
 SG_ EM1_Rekuperation_Ueberlauf  : 151|1@1+ (1.000000,0.000000) [0.000000|1.000000] "" Motor_BEV
 SG_ EM1_Verbrauch  : 152|15@1+ (10.000000,0.000000) [0.000000|327670.000000] "Unit_WattSecond" Motor_BEV
 SG_ EM1_Verbrauch_Ueberlauf  : 167|1@1+ (1.000000,0.000000) [0.000000|1.000000] "" Motor_BEV
 SG_ EM1_Fehler_AE  : 168|1@1+ (1.000000,0.000000) [0.000000|1.000000] "" Motor_BEV
 SG_ EM1_Fehler_Leistungsred  : 169|1@1+ (1.000000,0.000000) [0.000000|1.000000] "" Motor_BEV
 SG_ EM1_Fehler_ElAntriebFreilauf  : 170|1@1+ (1.000000,0.000000) [0.000000|1.000000] "" Motor_BEV
 SG_ EM1_PWR_SollVolumenstrom  : 171|6@1+ (0.500000,0.000000) [0.000000|30.500000] "Unit_LiterPerMinut" Motor_BEV

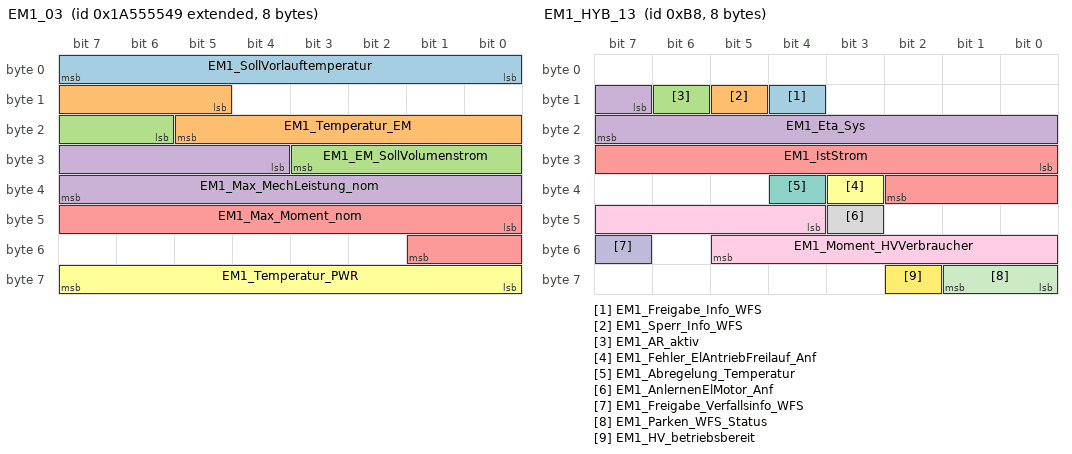
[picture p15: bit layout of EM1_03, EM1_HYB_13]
BO_ 2589283657 EM1_03: 8 LE1
 SG_ EM1_SollVorlauftemperatur  : 0|8@1+ (0.500000,-40.000000) [-40.000000|86.500000] "Unit_DegreCelsi" Motor_BEV
 SG_ EM1_Temperatur_EM  : 13|9@1+ (1.000000,-40.000000) [-40.000000|469.000000] "Unit_DegreCelsi" ICAS1_Gateway Motor_BEV
 SG_ EM1_EM_SollVolumenstrom  : 22|6@1+ (0.500000,0.000000) [0.000000|30.500000] "Unit_LiterPerMinut" Motor_BEV
 SG_ EM1_Max_MechLeistung_nom  : 28|12@1+ (200.000000,0.000000) [0.000000|818600.000000] "Unit_Watt" Motor_BEV
 SG_ EM1_Max_Moment_nom  : 40|10@1+ (1.000000,0.000000) [0.000000|1021.000000] "Unit_NewtoMeter" Motor_BEV
 SG_ EM1_Temperatur_PWR  : 56|8@1+ (1.000000,-40.000000) [-40.000000|213.000000] "Unit_DegreCelsi" ICAS1_Gateway Motor_BEV

BO_ 184 EM1_HYB_13: 8 LE1
 SG_ EM1_Freigabe_Info_WFS  : 12|1@1+ (1.000000,0.000000) [0.000000|1.000000] "" ICAS1_Gateway Motor_BEV
 SG_ EM1_Sperr_Info_WFS  : 13|1@1+ (1.000000,0.000000) [0.000000|1.000000] "" ICAS1_Gateway Motor_BEV
 SG_ EM1_AR_aktiv  : 14|1@1+ (1.000000,0.000000) [0.000000|1.000000] "" ICAS1_Gateway
 SG_ EM1_Eta_Sys  : 15|9@1+ (0.200000,0.000000) [0.000000|101.800000] "Unit_PerCent" ICAS1_Gateway
 SG_ EM1_IstStrom  : 24|11@1+ (1.000000,-1023.000000) [-1023.000000|1022.000000] "Unit_Amper" ICAS1_Gateway
 SG_ EM1_Fehler_ElAntriebFreilauf_Anf  : 35|1@1+ (1.000000,0.000000) [0.000000|1.000000] "" ICAS1_Gateway
 SG_ EM1_Abregelung_Temperatur  : 36|1@1+ (1.000000,0.000000) [0.000000|1.000000] "" ICAS1_Gateway
 SG_ EM1_AnlernenElMotor_Anf  : 43|1@1+ (1.000000,0.000000) [0.000000|1.000000] "" ICAS1_Gateway
 SG_ EM1_Moment_HVVerbraucher  : 44|10@1+ (1.000000,-511.000000) [-511.000000|511.000000] "Unit_NewtoMeter" ICAS1_Gateway
 SG_ EM1_Freigabe_Verfallsinfo_WFS  : 55|1@1+ (1.000000,0.000000) [0.000000|1.000000] "" ICAS1_Gateway Motor_BEV
 SG_ EM1_Parken_WFS_Status  : 56|2@1+ (1.000000,0.000000) [0.000000|3.000000] "" ICAS1_Gateway
 SG_ EM1_HV_betriebsbereit  : 58|1@1+ (1.000000,0.000000) [0.000000|1.000000] "" ICAS1_Gateway

BO_ 2527679712 EM1_HYB_27: 8 LE1
 SG_ EM1_RtmWarnKommunikation  : 12|3@1+ (1.000000,0.000000) [0.000000|7.000000] "" Vector__XXX
 SG_ EM1_RtmWarnUeberdrehzahl  : 15|3@1+ (1.000000,0.000000) [0.000000|7.000000] "" ICAS1_Gateway
 SG_ EM1_RtmWarnUeberstrom  : 18|3@1+ (1.000000,0.000000) [0.000000|7.000000] "" ICAS1_Gateway
 SG_ EM1_RtmWarnTempEM  : 21|3@1+ (1.000000,0.000000) [0.000000|7.000000] "" ICAS1_Gateway
 SG_ EM1_RtmWarnTempPWR  : 24|3@1+ (1.000000,0.000000) [0.000000|7.000000] "" ICAS1_Gateway

BO_ 193 EM2_01: 32 LE2
 SG_ EM2_01_CRC  : 0|8@1+ (1.000000,0.000000) [0.000000|255.000000] "" Motor_BEV
 SG_ EM2_01_BZ  : 8|4@1+ (1.000000,0.000000) [0.000000|15.000000] "" Motor_BEV
 SG_ EM2_Istmodus  : 12|4@1+ (1.000000,0.000000) [0.000000|15.000000] "" ICAS1_Gateway Motor_BEV
 SG_ EM2_IstMoment  : 16|12@1+ (0.500000,-1023.000000) [-1023.000000|1023.500000] "Unit_NewtoMeter" ICAS1_Gateway Motor_BEV
 SG_ EM2_Moment_AR_Eingriff  : 28|12@1+ (0.500000,-1023.000000) [-1023.000000|1023.500000] "Unit_NewtoMeter" Motor_BEV
 SG_ EM2_IstDrehzahl  : 40|15@1+ (1.000000,-10000.000000) [-10000.000000|22765.000000] "Unit_MinutInver" ICAS1_Gateway Motor_BEV
 SG_ EM2_AR_aktiv  : 55|1@1+ (1.000000,0.000000) [0.000000|1.000000] "" Motor_BEV
 SG_ EM2_IstSpannung  : 56|12@1+ (0.250000,0.000000) [0.000000|1023.250000] "Unit_Volt" ICAS1_Gateway Motor_BEV
 SG_ EM2_Strom_HV  : 68|12@1+ (0.500000,-1023.000000) [-1023.000000|1023.500000] "Unit_Amper" ICAS1_Gateway Motor_BEV
 SG_ EM2_Max_Moment  : 80|11@1+ (1.000000,-1023.000000) [-1023.000000|1022.000000] "Unit_NewtoMeter" Motor_BEV
 SG_ EM2_ErwGrenzen_aktiv  : 91|1@1+ (1.000000,0.000000) [0.000000|1.000000] "" Motor_BEV
 SG_ EM2_Min_Moment  : 92|11@1+ (1.000000,-1023.000000) [-1023.000000|1022.000000] "Unit_NewtoMeter" Motor_BEV
 SG_ EM2_Fehler_ElAntriebAbschaltung  : 103|1@1+ (1.000000,0.000000) [0.000000|1.000000] "" Motor_BEV
 SG_ EM2_Max_Moment_Lim  : 104|11@1+ (1.000000,-1023.000000) [-1023.000000|1022.000000] "Unit_NewtoMeter" Motor_BEV
 SG_ EM2_Fehler_Notabschaltung  : 115|1@1+ (1.000000,0.000000) [0.000000|1.000000] "" ICAS1_Gateway Motor_BEV
 SG_ EM2_Min_Moment_Lim  : 116|11@1+ (1.000000,-1023.000000) [-1023.000000|1022.000000] "Unit_NewtoMeter" Motor_BEV
 SG_ EM2_Status_DrzEingriff  : 127|2@1+ (1.000000,0.000000) [0.000000|3.000000] "" ICAS1_Gateway Motor_BEV
 SG_ EM2_Mom_DrzEingriff  : 129|11@1+ (1.000000,-1023.000000) [-1023.000000|1022.000000] "Unit_NewtoMeter" Motor_BEV

BO_ 2463978674 EM2_02: 32 LE2
 SG_ EM2_Status_Spgfreiheit  : 12|2@1+ (1.000000,0.000000) [0.000000|3.000000] "" Motor_BEV
 SG_ EM2_Status_EoHVL  : 14|2@1+ (1.000000,0.000000) [0.000000|3.000000] "" Motor_BEV
 SG_ EM2_Max_LeistungMech_Sockel  : 16|13@1+ (200.000000,-819000.000000) [-819000.000000|818800.000000] "Unit_Watt" Vector__XXX
 SG_ EM2_Max_Moment_Sockel  : 29|11@1+ (1.000000,-1023.000000) [-1023.000000|1022.000000] "Unit_NewtoMeter" Vector__XXX
 SG_ EM2_Min_LeistungMech_Sockel  : 40|13@1+ (200.000000,-819000.000000) [-819000.000000|818800.000000] "Unit_Watt" Vector__XXX
 SG_ EM2_Min_Moment_Sockel  : 53|11@1+ (1.000000,-1023.000000) [-1023.000000|1022.000000] "Unit_NewtoMeter" Vector__XXX
 SG_ EM2_PerfInd_MaxLeistung  : 64|10@1+ (0.200000,0.000000) [0.000000|200.000000] "Unit_PerCent" Motor_BEV
 SG_ EM2_PerfInd_MaxMoment  : 74|10@1+ (0.200000,0.000000) [0.000000|200.000000] "Unit_PerCent" Motor_BEV
 SG_ EM2_AnlernenElMotor_Anf  : 84|1@1+ (1.000000,0.000000) [0.000000|1.000000] "" Motor_BEV
 SG_ EM2_OBD_Lampe_Anf  : 85|1@1+ (1.000000,0.000000) [0.000000|1.000000] "" Motor_BEV
 SG_ EM2_Generator_Moment  : 86|10@1+ (1.000000,0.000000) [0.000000|1021.000000] "Unit_NewtoMeter" Motor_BEV
 SG_ EM2_PerfInd_Temperatur  : 96|8@1+ (0.800000,0.000000) [0.000000|200.000000] "Unit_PerCent" Motor_BEV
 SG_ EM2_MaxZul_Drehzahl  : 104|8@1+ (80.000000,0.000000) [0.000000|20240.000000] "Unit_RevPerMinute" Motor_BEV
 SG_ EM2_Min_Moment_Gesamt  : 112|11@1+ (1.000000,-1023.000000) [-1023.000000|1022.000000] "Unit_NewtoMeter" Motor_BEV
 SG_ EM2_Fehlerlampe_Anf  : 123|1@1+ (1.000000,0.000000) [0.000000|1.000000] "" Motor_BEV
 SG_ EM2_Max_Moment_Gesamt  : 124|11@1+ (1.000000,-1023.000000) [-1023.000000|1022.000000] "Unit_NewtoMeter" Motor_BEV
 SG_ EM2_Warnlampe_Anf  : 135|1@1+ (1.000000,0.000000) [0.000000|1.000000] "" Motor_BEV
 SG_ EM2_Rekuperation  : 136|15@1+ (10.000000,0.000000) [0.000000|327670.000000] "Unit_WattSecond" Motor_BEV
 SG_ EM2_Rekuperation_Ueberlauf  : 151|1@1+ (1.000000,0.000000) [0.000000|1.000000] "" Motor_BEV
 SG_ EM2_Verbrauch  : 152|15@1+ (10.000000,0.000000) [0.000000|327670.000000] "Unit_WattSecond" Motor_BEV
 SG_ EM2_Verbrauch_Ueberlauf  : 167|1@1+ (1.000000,0.000000) [0.000000|1.000000] "" Motor_BEV
 SG_ EM2_Fehler_AE  : 168|1@1+ (1.000000,0.000000) [0.000000|1.000000] "" Motor_BEV
 SG_ EM2_Fehler_Leistungsred  : 169|1@1+ (1.000000,0.000000) [0.000000|1.000000] "" Motor_BEV
 SG_ EM2_Fehler_ElAntriebFreilauf  : 170|1@1+ (1.000000,0.000000) [0.000000|1.000000] "" Motor_BEV
 SG_ EM2_PWR_SollVolumenstrom  : 171|6@1+ (0.500000,0.000000) [0.000000|30.500000] "Unit_LiterPerMinut" Motor_BEV

BO_ 2589283660 EM2_03: 8 LE2
 SG_ EM2_SollVorlauftemperatur  : 0|8@1+ (0.500000,-40.000000) [-40.000000|86.500000] "Unit_DegreCelsi" Motor_BEV
 SG_ EM2_Temperatur_EM  : 13|9@1+ (1.000000,-40.000000) [-40.000000|469.000000] "Unit_DegreCelsi" ICAS1_Gateway Motor_BEV
 SG_ EM2_EM_SollVolumenstrom  : 22|6@1+ (0.500000,0.000000) [0.000000|30.500000] "Unit_LiterPerMinut" Motor_BEV
 SG_ EM2_Max_MechLeistung_nom  : 28|12@1+ (200.000000,0.000000) [0.000000|818600.000000] "Unit_Watt" Motor_BEV
 SG_ EM2_Max_Moment_nom  : 40|10@1+ (1.000000,0.000000) [0.000000|1021.000000] "Unit_NewtoMeter" Motor_BEV
 SG_ EM2_Temperatur_PWR  : 56|8@1+ (1.000000,-40.000000) [-40.000000|213.000000] "Unit_DegreCelsi" ICAS1_Gateway Motor_BEV

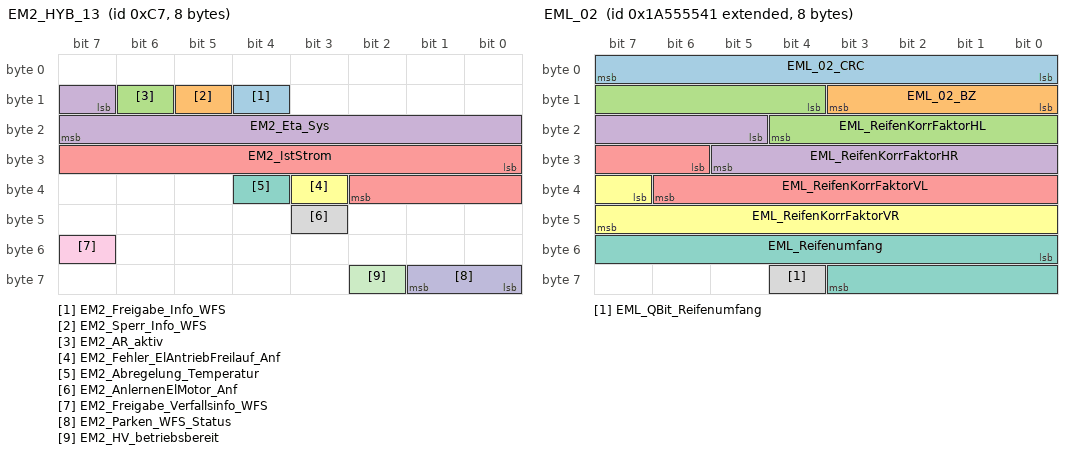
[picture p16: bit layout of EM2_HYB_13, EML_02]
BO_ 199 EM2_HYB_13: 8 LE2
 SG_ EM2_Freigabe_Info_WFS  : 12|1@1+ (1.000000,0.000000) [0.000000|1.000000] "" ICAS1_Gateway Motor_BEV
 SG_ EM2_Sperr_Info_WFS  : 13|1@1+ (1.000000,0.000000) [0.000000|1.000000] "" ICAS1_Gateway Motor_BEV
 SG_ EM2_AR_aktiv  : 14|1@1+ (1.000000,0.000000) [0.000000|1.000000] "" ICAS1_Gateway
 SG_ EM2_Eta_Sys  : 15|9@1+ (0.200000,0.000000) [0.000000|101.800000] "Unit_PerCent" ICAS1_Gateway
 SG_ EM2_IstStrom  : 24|11@1+ (1.000000,-1023.000000) [-1023.000000|1022.000000] "Unit_Amper" ICAS1_Gateway
 SG_ EM2_Fehler_ElAntriebFreilauf_Anf  : 35|1@1+ (1.000000,0.000000) [0.000000|1.000000] "" ICAS1_Gateway
 SG_ EM2_Abregelung_Temperatur  : 36|1@1+ (1.000000,0.000000) [0.000000|1.000000] "" ICAS1_Gateway
 SG_ EM2_AnlernenElMotor_Anf  : 43|1@1+ (1.000000,0.000000) [0.000000|1.000000] "" ICAS1_Gateway
 SG_ EM2_Freigabe_Verfallsinfo_WFS  : 55|1@1+ (1.000000,0.000000) [0.000000|1.000000] "" ICAS1_Gateway Motor_BEV
 SG_ EM2_Parken_WFS_Status  : 56|2@1+ (1.000000,0.000000) [0.000000|3.000000] "" ICAS1_Gateway
 SG_ EM2_HV_betriebsbereit  : 58|1@1+ (1.000000,0.000000) [0.000000|1.000000] "" ICAS1_Gateway

BO_ 2527679713 EM2_HYB_27: 8 LE2
 SG_ EM2_RtmWarnKommunikation  : 12|3@1+ (1.000000,0.000000) [0.000000|7.000000] "" Vector__XXX
 SG_ EM2_RtmWarnUeberdrehzahl  : 15|3@1+ (1.000000,0.000000) [0.000000|7.000000] "" ICAS1_Gateway
 SG_ EM2_RtmWarnUeberstrom  : 18|3@1+ (1.000000,0.000000) [0.000000|7.000000] "" ICAS1_Gateway
 SG_ EM2_RtmWarnTempEM  : 21|3@1+ (1.000000,0.000000) [0.000000|7.000000] "" ICAS1_Gateway
 SG_ EM2_RtmWarnTempPWR  : 24|3@1+ (1.000000,0.000000) [0.000000|7.000000] "" ICAS1_Gateway

BO_ 2589283649 EML_02: 8 ICAS1_Gateway
 SG_ EML_02_CRC  : 0|8@1+ (1.000000,0.000000) [0.000000|255.000000] "" Vector__XXX
 SG_ EML_02_BZ  : 8|4@1+ (1.000000,0.000000) [0.000000|15.000000] "" Vector__XXX
 SG_ EML_ReifenKorrFaktorHL  : 12|9@1+ (0.000488,0.850000) [0.850000|1.098535] "" Vector__XXX
 SG_ EML_ReifenKorrFaktorHR  : 21|9@1+ (0.000488,0.850000) [0.850000|1.098535] "" Vector__XXX
 SG_ EML_ReifenKorrFaktorVL  : 30|9@1+ (0.000488,0.850000) [0.850000|1.098535] "" Vector__XXX
 SG_ EML_ReifenKorrFaktorVR  : 39|9@1+ (0.000488,0.850000) [0.850000|1.098535] "" Vector__XXX
 SG_ EML_Reifenumfang  : 48|12@1+ (1.000000,0.000000) [0.000000|4095.000000] "Unit_MilliMeter" Motor_BEV
 SG_ EML_QBit_Reifenumfang  : 60|1@1+ (1.000000,0.000000) [0.000000|1.000000] "" Motor_BEV

BO_ 608 EML_07: 8 ICAS1_Gateway
 SG_ EML_AnzeigeGeschw  : 54|10@1+ (0.320000,0.000000) [0.000000|325.120000] "Unit_KiloMeterPerHour" Motor_BEV

BO_ 2589283751 Entfernungen_01: 8 ICAS1_KommunikationsServer
 SG_ KBI_Kilometerstand_HiRes_meter  : 32|32@1+ (1.000000,0.000000) [0.000000|4294967295.000000] "Unit_Meter" Motor_BEV

BO_ 2527679687 EPS_ASM_01: 8 ICAS1_Gateway
 SG_ EPS_ASM_Ereignis  : 0|8@1+ (1.000000,0.000000) [1.000000|254.000000] "Unit_None" Airbag
 SG_ EPS_ASM_Zeitstempel  : 8|8@1+ (0.080000,0.000000) [0.000000|20.320000] "Unit_None" Airbag
 SG_ EPS_ASM_Data_1  : 16|8@1+ (1.000000,0.000000) [0.000000|255.000000] "Unit_None" Airbag
 SG_ EPS_ASM_Data_2  : 24|8@1+ (1.000000,0.000000) [0.000000|255.000000] "Unit_None" Airbag
 SG_ EPS_ASM_Data_3  : 32|8@1+ (1.000000,0.000000) [0.000000|255.000000] "Unit_None" Airbag
 SG_ EPS_ASM_Data_4  : 40|8@1+ (1.000000,0.000000) [0.000000|255.000000] "Unit_None" Airbag
 SG_ EPS_ASM_Data_5  : 48|8@1+ (1.000000,0.000000) [0.000000|255.000000] "Unit_None" Airbag
 SG_ EPS_ASM_Data_6  : 56|8@1+ (1.000000,0.000000) [0.000000|255.000000] "Unit_None" Airbag

BO_ 258 ESC_50: 48 ICAS1_Gateway
 SG_ ESC_50_CRC  : 0|8@1+ (1.000000,0.000000) [0.000000|255.000000] "" Motor_BEV
 SG_ ESC_50_BZ  : 8|4@1+ (1.000000,0.000000) [0.000000|15.000000] "" Motor_BEV
 SG_ ESP_QBit_Gierrate  : 12|1@1+ (1.000000,0.000000) [0.000000|1.000000] "" Motor_BEV
 SG_ ESP_QBit_Laengsbeschl  : 13|1@1+ (1.000000,0.000000) [0.000000|1.000000] "" Motor_BEV
 SG_ ESP_QBit_Querb  : 14|1@1+ (1.000000,0.000000) [0.000000|1.000000] "" Motor_BEV
 SG_ ESP_Querbeschleunigung  : 16|8@1+ (0.010000,-1.270000) [-1.270000|1.270000] "Unit_ForceOfGravi" Airbag Motor_BEV
 SG_ ESP_Laengsbeschl  : 24|10@1+ (0.031250,-16.000000) [-16.000000|15.906250] "Unit_MeterPerSeconSquar" Airbag Motor_BEV
 SG_ ESC_Motorstartverzoegerung  : 34|1@1+ (1.000000,0.000000) [0.000000|1.000000] "" Vector__XXX
 SG_ ESC_SeitenwindAssistent_Eingriff  : 35|1@1+ (1.000000,0.000000) [0.000000|1.000000] "" Vector__XXX
 SG_ ESP_Anschleppstart_Freigabe  : 36|2@1+ (1.000000,0.000000) [0.000000|3.000000] "" Vector__XXX
 SG_ ESC_Unterdruckmangel_erkannt  : 38|1@1+ (1.000000,0.000000) [0.000000|1.000000] "" Vector__XXX
 SG_ ESP_Gierrate  : 40|14@1+ (0.010000,0.000000) [0.000000|163.820000] "Unit_DegreOfArcPerSecon" Airbag Motor_BEV
 SG_ ESP_VZ_Gierrate  : 54|1@1+ (1.000000,0.000000) [0.000000|1.000000] "" Airbag Motor_BEV
 SG_ ESP_Notbremsanzeige  : 55|1@1+ (1.000000,0.000000) [0.000000|1.000000] "" Vector__XXX
 SG_ ESP_SpannungsAnf  : 56|1@1+ (1.000000,0.000000) [0.000000|1.000000] "" Vector__XXX
 SG_ ESP_PLA_Abbruch  : 57|3@1+ (1.000000,0.000000) [0.000000|7.000000] "" Vector__XXX
 SG_ ESP_Status_ESP_PLA  : 60|4@1+ (1.000000,0.000000) [0.000000|15.000000] "" Vector__XXX
 SG_ ESP_QBit_Bremsdruck  : 76|1@1+ (1.000000,0.000000) [0.000000|1.000000] "" Airbag Motor_BEV
 SG_ ESP_QBit_Fahrer_bremst  : 77|1@1+ (1.000000,0.000000) [0.000000|1.000000] "" Vector__XXX
 SG_ ESP_Schwelle_Unterdruck  : 78|2@1+ (1.000000,0.000000) [0.000000|3.000000] "" Vector__XXX
 SG_ ESP_Bremsdruck  : 80|10@1+ (0.300000,-30.000000) [-30.000000|276.600000] "Unit_Bar" Motor_BEV
 SG_ ESP_Fahrer_bremst  : 90|1@1+ (1.000000,0.000000) [0.000000|1.000000] "" Vector__XXX
 SG_ ESP_Verz_TSK_aktiv  : 91|1@1+ (1.000000,0.000000) [0.000000|1.000000] "" Vector__XXX
 SG_ ESP_Lenkeingriff_ADS  : 92|1@1+ (1.000000,0.000000) [0.000000|1.000000] "" Vector__XXX
 SG_ ESP_Konsistenz_TSK  : 93|1@1+ (1.000000,0.000000) [0.000000|1.000000] "" Vector__XXX
 SG_ ESP_Bremsruck_AWV2  : 94|1@1+ (1.000000,0.000000) [0.000000|1.000000] "" Vector__XXX
 SG_ ESP_Konsistenz_AWV2  : 95|1@1+ (1.000000,0.000000) [0.000000|1.000000] "" Vector__XXX
 SG_ ECD_Fehler  : 96|1@1+ (1.000000,0.000000) [0.000000|1.000000] "" Vector__XXX
 SG_ ECD_nicht_verfuegbar  : 97|1@1+ (1.000000,0.000000) [0.000000|1.000000] "" Vector__XXX
 SG_ ESP_Status_Bremsentemp  : 98|1@1+ (1.000000,0.000000) [0.000000|1.000000] "" Vector__XXX
 SG_ ESP_Autohold_Standby  : 99|1@1+ (1.000000,0.000000) [0.000000|1.000000] "" Vector__XXX
 SG_ ESP_HDC_Standby  : 100|1@1+ (1.000000,0.000000) [0.000000|1.000000] "" Vector__XXX
 SG_ ESP_HBA_aktiv  : 101|1@1+ (1.000000,0.000000) [0.000000|1.000000] "" Vector__XXX
 SG_ ESP_Prefill_ausgeloest  : 102|1@1+ (1.000000,0.000000) [0.000000|1.000000] "" Vector__XXX
 SG_ ESP_Rueckwaertsfahrt_erkannt  : 103|1@1+ (1.000000,0.000000) [0.000000|1.000000] "" Vector__XXX
 SG_ ESP_Status_Anfahrhilfe  : 104|1@1+ (1.000000,0.000000) [0.000000|1.000000] "" Vector__XXX
 SG_ ESP_HDC_aktiv  : 105|1@1+ (1.000000,0.000000) [0.000000|1.000000] "" Vector__XXX
 SG_ ESP_StartStopp_Info  : 106|2@1+ (1.000000,0.000000) [0.000000|3.000000] "" Vector__XXX
 SG_ ESP_Eingr_HL  : 108|1@1+ (1.000000,0.000000) [0.000000|1.000000] "" Vector__XXX
 SG_ ESP_Eingr_HR  : 109|1@1+ (1.000000,0.000000) [0.000000|1.000000] "" Vector__XXX
 SG_ ESP_Eingr_VL  : 110|1@1+ (1.000000,0.000000) [0.000000|1.000000] "" Vector__XXX
 SG_ ESP_Eingr_VR  : 111|1@1+ (1.000000,0.000000) [0.000000|1.000000] "" Vector__XXX
 SG_ ESP_BKV_Unterdruck  : 112|8@1+ (4.000000,0.000000) [4.000000|1012.000000] "Unit_MilliBar" Vector__XXX
 SG_ ESP_Autohold_aktiv  : 120|1@1+ (1.000000,0.000000) [0.000000|1.000000] "" Vector__XXX
 SG_ ESP_FStatus_Anfahrhilfe  : 121|1@1+ (1.000000,0.000000) [0.000000|1.000000] "" Vector__XXX
 SG_ ESP_Verz_EPB_aktiv  : 122|1@1+ (1.000000,0.000000) [0.000000|1.000000] "" Vector__XXX
 SG_ ECD_Bremslicht  : 123|1@1+ (1.000000,0.000000) [0.000000|1.000000] "" Motor_BEV
 SG_ ESP_Verzoeg_EPB_verf  : 124|1@1+ (1.000000,0.000000) [0.000000|1.000000] "" Vector__XXX
 SG_ ESP_Status_Bremsdruck  : 125|1@1+ (1.000000,0.000000) [0.000000|1.000000] "" Vector__XXX
 SG_ ESP_Anforderung_EPB  : 126|2@1+ (1.000000,0.000000) [0.000000|3.000000] "" Vector__XXX
 SG_ ESP_ANB_CM_Rueckk_Umsetz  : 140|1@1+ (1.000000,0.000000) [0.000000|1.000000] "" Vector__XXX
 SG_ ESP_Konsistenz_ACC_Botschaft  : 141|1@1+ (1.000000,0.000000) [0.000000|1.000000] "" Vector__XXX
 SG_ ESP_Stillstandsphase_erschoepft  : 142|1@1+ (1.000000,0.000000) [0.000000|1.000000] "" Vector__XXX
 SG_ ESP_ZT_Rueckk_Umsetz  : 143|1@1+ (1.000000,0.000000) [0.000000|1.000000] "" Vector__XXX
 SG_ ESP_Tuerkontakt_Fahrertuer  : 144|1@1+ (1.000000,0.000000) [0.000000|1.000000] "" Vector__XXX
 SG_ ESP_Abrutschen_Stillstand  : 146|1@1+ (1.000000,0.000000) [0.000000|1.000000] "" Vector__XXX
 SG_ ESP_Fahrer_tritt_ZBR_Schw  : 147|1@1+ (1.000000,0.000000) [0.000000|1.000000] "" Vector__XXX
 SG_ ESP_QBit_v_ref  : 169|1@1+ (1.000000,0.000000) [0.000000|1.000000] "" Vector__XXX
 SG_ ESP_v_ref_Fahrtrichtung  : 170|2@1+ (1.000000,0.000000) [0.000000|3.000000] "" Motor_BEV
 SG_ ESC_Bremsdruckgradient  : 172|8@1+ (10.000000,0.000000) [0.000000|2500.000000] "Unit_BarPerSecon" Vector__XXX
 SG_ ESP_v_ref  : 180|12@1+ (0.125000,0.000000) [0.000000|511.500000] "Unit_KiloMeterPerHour" Airbag Motor_BEV
 SG_ ESC_Hydr_Fkt_aktiv  : 223|2@1+ (1.000000,0.000000) [0.000000|3.000000] "" Vector__XXX
 SG_ ESC_QBit_Fahrerbremswunsch  : 225|1@1+ (1.000000,0.000000) [0.000000|1.000000] "" Motor_BEV
 SG_ ESC_Fahrerbremswunsch  : 226|10@1+ (0.300000,-30.000000) [-30.000000|276.600000] "Unit_Bar" Motor_BEV
 SG_ ESCGeneratorSollMoment  : 236|12@1+ (3.000000,-12279.000000) [-12279.000000|0.000000] "" Motor_BEV
 SG_ ESC_Raddruck_max  : 248|8@1+ (1.000000,0.000000) [0.000000|250.000000] "Unit_Bar" Vector__XXX
 SG_ EPB_QBit_Pedalweg_Kuppl  : 269|1@1+ (1.000000,0.000000) [0.000000|1.000000] "" Vector__XXX
 SG_ EPB_Freig_Verzoeg_Anf  : 271|1@1+ (1.000000,0.000000) [0.000000|1.000000] "" Vector__XXX
 SG_ EPB_Verzoeg_Anf  : 272|8@1+ (0.048000,-7.968000) [-7.968000|4.224000] "Unit_MeterPerSeconSquar" Vector__XXX
 SG_ EPB_Pedalweg_Kuppl  : 288|8@1+ (0.400000,0.000000) [8.000000|92.000000] "Unit_PerCent" Vector__XXX
 SG_ EPB_DAA_Randbed_erf  : 305|1@1+ (1.000000,0.000000) [0.000000|1.000000] "" Vector__XXX
 SG_ EPB_Fehlerstatus_02  : 306|2@1+ (1.000000,0.000000) [0.000000|3.000000] "" Vector__XXX
 SG_ EPB_Schalterposition  : 308|2@1+ (1.000000,0.000000) [0.000000|3.000000] "" Airbag
 SG_ EPB_QBit_Schalterpos  : 310|1@1+ (1.000000,0.000000) [0.000000|1.000000] "" Vector__XXX
 SG_ EPB_Spannkraft  : 312|5@1+ (1.000000,0.000000) [0.000000|29.000000] "Unit_KiloNewto" Vector__XXX
 SG_ EPB_Status_02  : 317|3@1+ (1.000000,0.000000) [0.000000|7.000000] "" Motor_BEV
 SG_ EPB_Status  : 320|2@1+ (1.000000,0.000000) [0.000000|3.000000] "" Vector__XXX
 SG_ ESP_Status_Bremsentemp_02  : 322|2@1+ (1.000000,0.000000) [0.000000|3.000000] "" Motor_BEV

BU_:  Airbag BAP_Tester ICAS1_Gateway ICAS1_KommunikationsServer LE1 LE2 Motor_BEV Schaltbetaetigung

BO_ 192 EM1_01: 32 LE1
 SG_ EM1_01_CRC  : 0|8@1+ (1.000000,0.000000) [0.000000|255.000000] "" ICAS1_Gateway Motor_BEV
 SG_ EM1_01_BZ  : 8|4@1+ (1.000000,0.000000) [0.000000|15.000000] "" ICAS1_Gateway Motor_BEV
 SG_ EM1_Istmodus  : 12|4@1+ (1.000000,0.000000) [0.000000|15.000000] "" ICAS1_Gateway Motor_BEV
 SG_ EM1_IstMoment  : 16|12@1+ (0.500000,-1023.000000) [-1023.000000|1023.500000] "Unit_NewtoMeter" ICAS1_Gateway Motor_BEV
 SG_ EM1_Moment_AR_Eingriff  : 28|12@1+ (0.500000,-1023.000000) [-1023.000000|1023.500000] "Unit_NewtoMeter" ICAS1_Gateway Motor_BEV
 SG_ EM1_IstDrehzahl  : 40|15@1+ (1.000000,-10000.000000) [-10000.000000|22765.000000] "Unit_MinutInver" ICAS1_Gateway Motor_BEV
 SG_ EM1_AR_aktiv  : 55|1@1+ (1.000000,0.000000) [0.000000|1.000000] "" ICAS1_Gateway Motor_BEV
 SG_ EM1_IstSpannung  : 56|12@1+ (0.250000,0.000000) [0.000000|1023.250000] "Unit_Volt" ICAS1_Gateway Motor_BEV
 SG_ EM1_Strom_HV  : 68|12@1+ (0.500000,-1023.000000) [-1023.000000|1023.500000] "Unit_Amper" ICAS1_Gateway Motor_BEV
 SG_ EM1_Max_Moment  : 80|11@1+ (1.000000,-1023.000000) [-1023.000000|1022.000000] "Unit_NewtoMeter" ICAS1_Gateway Motor_BEV
 SG_ EM1_ErwGrenzen_aktiv  : 91|1@1+ (1.000000,0.000000) [0.000000|1.000000] "" ICAS1_Gateway Motor_BEV
 SG_ EM1_Min_Moment  : 92|11@1+ (1.000000,-1023.000000) [-1023.000000|1022.000000] "Unit_NewtoMeter" ICAS1_Gateway Motor_BEV
 SG_ EM1_Fehler_ElAntriebAbschaltung  : 103|1@1+ (1.000000,0.000000) [0.000000|1.000000] "" ICAS1_Gateway Motor_BEV
 SG_ EM1_Max_Moment_Lim  : 104|11@1+ (1.000000,-1023.000000) [-1023.000000|1022.000000] "Unit_NewtoMeter" ICAS1_Gateway Motor_BEV
 SG_ EM1_Fehler_Notabschaltung  : 115|1@1+ (1.000000,0.000000) [0.000000|1.000000] "" ICAS1_Gateway Motor_BEV
 SG_ EM1_Min_Moment_Lim  : 116|11@1+ (1.000000,-1023.000000) [-1023.000000|1022.000000] "Unit_NewtoMeter" ICAS1_Gateway Motor_BEV
 SG_ EM1_Status_DrzEingriff  : 127|2@1+ (1.000000,0.000000) [0.000000|3.000000] "" ICAS1_Gateway Motor_BEV
 SG_ EM1_Mom_DrzEingriff  : 129|11@1+ (1.000000,-1023.000000) [-1023.000000|1022.000000] "Unit_NewtoMeter" ICAS1_Gateway Motor_BEV

BO_ 2463978673 EM1_02: 32 LE1
 SG_ EM1_Status_Spgfreiheit  : 12|2@1+ (1.000000,0.000000) [0.000000|3.000000] "" Motor_BEV
 SG_ EM1_Status_EoHVL  : 14|2@1+ (1.000000,0.000000) [0.000000|3.000000] "" Motor_BEV
 SG_ EM1_Max_LeistungMech_Sockel  : 16|13@1+ (200.000000,-819000.000000) [-819000.000000|818800.000000] "Unit_Watt" Vector__XXX
 SG_ EM1_Max_Moment_Sockel  : 29|11@1+ (1.000000,-1023.000000) [-1023.000000|1022.000000] "Unit_NewtoMeter" Vector__XXX
 SG_ EM1_Min_LeistungMech_Sockel  : 40|13@1+ (200.000000,-819000.000000) [-819000.000000|818800.000000] "Unit_Watt" Vector__XXX
 SG_ EM1_Min_Moment_Sockel  : 53|11@1+ (1.000000,-1023.000000) [-1023.000000|1022.000000] "Unit_NewtoMeter" Vector__XXX
 SG_ EM1_PerfInd_MaxLeistung  : 64|10@1+ (0.200000,0.000000) [0.000000|200.000000] "Unit_PerCent" Motor_BEV
 SG_ EM1_PerfInd_MaxMoment  : 74|10@1+ (0.200000,0.000000) [0.000000|200.000000] "Unit_PerCent" Motor_BEV
 SG_ EM1_AnlernenElMotor_Anf  : 84|1@1+ (1.000000,0.000000) [0.000000|1.000000] "" Motor_BEV
 SG_ EM1_OBD_Lampe_Anf  : 85|1@1+ (1.000000,0.000000) [0.000000|1.000000] "" Motor_BEV
 SG_ EM1_Generator_Moment  : 86|10@1+ (1.000000,0.000000) [0.000000|1021.000000] "Unit_NewtoMeter" Motor_BEV
 SG_ EM1_PerfInd_Temperatur  : 96|8@1+ (0.800000,0.000000) [0.000000|200.000000] "Unit_PerCent" Motor_BEV
 SG_ EM1_MaxZul_Drehzahl  : 104|8@1+ (80.000000,0.000000) [0.000000|20240.000000] "Unit_RevPerMinute" Motor_BEV
 SG_ EM1_Min_Moment_Gesamt  : 112|11@1+ (1.000000,-1023.000000) [-1023.000000|1022.000000] "Unit_NewtoMeter" Motor_BEV
 SG_ EM1_Fehlerlampe_Anf  : 123|1@1+ (1.000000,0.000000) [0.000000|1.000000] "" Motor_BEV
 SG_ EM1_Max_Moment_Gesamt  : 124|11@1+ (1.000000,-1023.000000) [-1023.000000|1022.000000] "Unit_NewtoMeter" Motor_BEV
 SG_ EM1_Warnlampe_Anf  : 135|1@1+ (1.000000,0.000000) [0.000000|1.000000] "" Motor_BEV
 SG_ EM1_Rekuperation  : 136|15@1+ (10.000000,0.000000) [0.000000|327670.000000] "Unit_WattSecond" Motor_BEV
 SG_ EM1_Rekuperation_Ueberlauf  : 151|1@1+ (1.000000,0.000000) [0.000000|1.000000] "" Motor_BEV
 SG_ EM1_Verbrauch  : 152|15@1+ (10.000000,0.000000) [0.000000|327670.000000] "Unit_WattSecond" Motor_BEV
 SG_ EM1_Verbrauch_Ueberlauf  : 167|1@1+ (1.000000,0.000000) [0.000000|1.000000] "" Motor_BEV
 SG_ EM1_Fehler_AE  : 168|1@1+ (1.000000,0.000000) [0.000000|1.000000] "" Motor_BEV
 SG_ EM1_Fehler_Leistungsred  : 169|1@1+ (1.000000,0.000000) [0.000000|1.000000] "" Motor_BEV
 SG_ EM1_Fehler_ElAntriebFreilauf  : 170|1@1+ (1.000000,0.000000) [0.000000|1.000000] "" Motor_BEV
 SG_ EM1_PWR_SollVolumenstrom  : 171|6@1+ (0.500000,0.000000) [0.000000|30.500000] "Unit_LiterPerMinut" Motor_BEV

BO_ 2589283657 EM1_03: 8 LE1
 SG_ EM1_SollVorlauftemperatur  : 0|8@1+ (0.500000,-40.000000) [-40.000000|86.500000] "Unit_DegreCelsi" Motor_BEV
 SG_ EM1_Temperatur_EM  : 13|9@1+ (1.000000,-40.000000) [-40.000000|469.000000] "Unit_DegreCelsi" ICAS1_Gateway Motor_BEV
 SG_ EM1_EM_SollVolumenstrom  : 22|6@1+ (0.500000,0.000000) [0.000000|30.500000] "Unit_LiterPerMinut" Motor_BEV
 SG_ EM1_Max_MechLeistung_nom  : 28|12@1+ (200.000000,0.000000) [0.000000|818600.000000] "Unit_Watt" Motor_BEV
 SG_ EM1_Max_Moment_nom  : 40|10@1+ (1.000000,0.000000) [0.000000|1021.000000] "Unit_NewtoMeter" Motor_BEV
 SG_ EM1_Temperatur_PWR  : 56|8@1+ (1.000000,-40.000000) [-40.000000|213.000000] "Unit_DegreCelsi" ICAS1_Gateway Motor_BEV

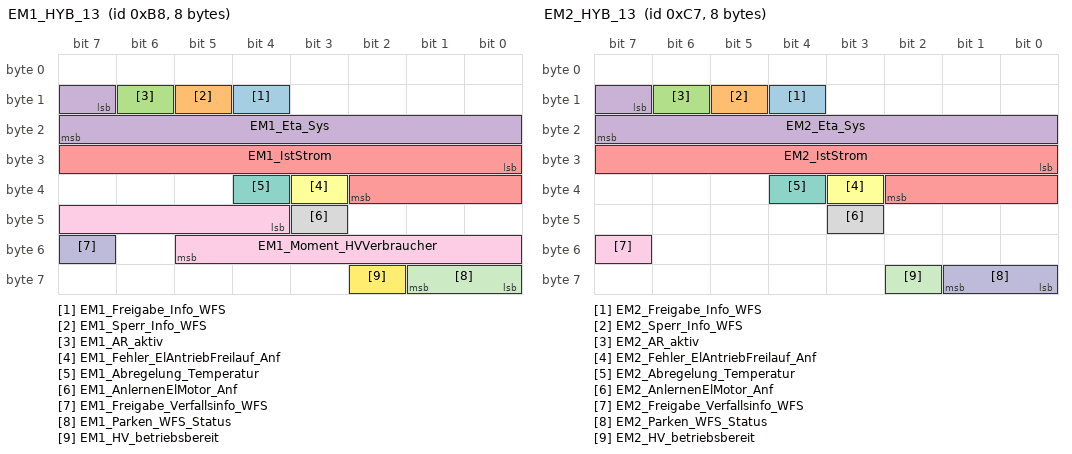
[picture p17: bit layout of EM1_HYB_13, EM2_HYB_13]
BO_ 184 EM1_HYB_13: 8 LE1
 SG_ EM1_Freigabe_Info_WFS  : 12|1@1+ (1.000000,0.000000) [0.000000|1.000000] "" ICAS1_Gateway Motor_BEV
 SG_ EM1_Sperr_Info_WFS  : 13|1@1+ (1.000000,0.000000) [0.000000|1.000000] "" ICAS1_Gateway Motor_BEV
 SG_ EM1_AR_aktiv  : 14|1@1+ (1.000000,0.000000) [0.000000|1.000000] "" ICAS1_Gateway
 SG_ EM1_Eta_Sys  : 15|9@1+ (0.200000,0.000000) [0.000000|101.800000] "Unit_PerCent" ICAS1_Gateway
 SG_ EM1_IstStrom  : 24|11@1+ (1.000000,-1023.000000) [-1023.000000|1022.000000] "Unit_Amper" ICAS1_Gateway
 SG_ EM1_Fehler_ElAntriebFreilauf_Anf  : 35|1@1+ (1.000000,0.000000) [0.000000|1.000000] "" ICAS1_Gateway
 SG_ EM1_Abregelung_Temperatur  : 36|1@1+ (1.000000,0.000000) [0.000000|1.000000] "" ICAS1_Gateway
 SG_ EM1_AnlernenElMotor_Anf  : 43|1@1+ (1.000000,0.000000) [0.000000|1.000000] "" ICAS1_Gateway
 SG_ EM1_Moment_HVVerbraucher  : 44|10@1+ (1.000000,-511.000000) [-511.000000|511.000000] "Unit_NewtoMeter" ICAS1_Gateway
 SG_ EM1_Freigabe_Verfallsinfo_WFS  : 55|1@1+ (1.000000,0.000000) [0.000000|1.000000] "" ICAS1_Gateway Motor_BEV
 SG_ EM1_Parken_WFS_Status  : 56|2@1+ (1.000000,0.000000) [0.000000|3.000000] "" ICAS1_Gateway
 SG_ EM1_HV_betriebsbereit  : 58|1@1+ (1.000000,0.000000) [0.000000|1.000000] "" ICAS1_Gateway

BO_ 2527679712 EM1_HYB_27: 8 LE1
 SG_ EM1_RtmWarnKommunikation  : 12|3@1+ (1.000000,0.000000) [0.000000|7.000000] "" Vector__XXX
 SG_ EM1_RtmWarnUeberdrehzahl  : 15|3@1+ (1.000000,0.000000) [0.000000|7.000000] "" ICAS1_Gateway
 SG_ EM1_RtmWarnUeberstrom  : 18|3@1+ (1.000000,0.000000) [0.000000|7.000000] "" ICAS1_Gateway
 SG_ EM1_RtmWarnTempEM  : 21|3@1+ (1.000000,0.000000) [0.000000|7.000000] "" ICAS1_Gateway
 SG_ EM1_RtmWarnTempPWR  : 24|3@1+ (1.000000,0.000000) [0.000000|7.000000] "" ICAS1_Gateway

BO_ 193 EM2_01: 32 LE2
 SG_ EM2_01_CRC  : 0|8@1+ (1.000000,0.000000) [0.000000|255.000000] "" Motor_BEV
 SG_ EM2_01_BZ  : 8|4@1+ (1.000000,0.000000) [0.000000|15.000000] "" Motor_BEV
 SG_ EM2_Istmodus  : 12|4@1+ (1.000000,0.000000) [0.000000|15.000000] "" ICAS1_Gateway Motor_BEV
 SG_ EM2_IstMoment  : 16|12@1+ (0.500000,-1023.000000) [-1023.000000|1023.500000] "Unit_NewtoMeter" ICAS1_Gateway Motor_BEV
 SG_ EM2_Moment_AR_Eingriff  : 28|12@1+ (0.500000,-1023.000000) [-1023.000000|1023.500000] "Unit_NewtoMeter" Motor_BEV
 SG_ EM2_IstDrehzahl  : 40|15@1+ (1.000000,-10000.000000) [-10000.000000|22765.000000] "Unit_MinutInver" ICAS1_Gateway Motor_BEV
 SG_ EM2_AR_aktiv  : 55|1@1+ (1.000000,0.000000) [0.000000|1.000000] "" Motor_BEV
 SG_ EM2_IstSpannung  : 56|12@1+ (0.250000,0.000000) [0.000000|1023.250000] "Unit_Volt" ICAS1_Gateway Motor_BEV
 SG_ EM2_Strom_HV  : 68|12@1+ (0.500000,-1023.000000) [-1023.000000|1023.500000] "Unit_Amper" ICAS1_Gateway Motor_BEV
 SG_ EM2_Max_Moment  : 80|11@1+ (1.000000,-1023.000000) [-1023.000000|1022.000000] "Unit_NewtoMeter" Motor_BEV
 SG_ EM2_ErwGrenzen_aktiv  : 91|1@1+ (1.000000,0.000000) [0.000000|1.000000] "" Motor_BEV
 SG_ EM2_Min_Moment  : 92|11@1+ (1.000000,-1023.000000) [-1023.000000|1022.000000] "Unit_NewtoMeter" Motor_BEV
 SG_ EM2_Fehler_ElAntriebAbschaltung  : 103|1@1+ (1.000000,0.000000) [0.000000|1.000000] "" Motor_BEV
 SG_ EM2_Max_Moment_Lim  : 104|11@1+ (1.000000,-1023.000000) [-1023.000000|1022.000000] "Unit_NewtoMeter" Motor_BEV
 SG_ EM2_Fehler_Notabschaltung  : 115|1@1+ (1.000000,0.000000) [0.000000|1.000000] "" ICAS1_Gateway Motor_BEV
 SG_ EM2_Min_Moment_Lim  : 116|11@1+ (1.000000,-1023.000000) [-1023.000000|1022.000000] "Unit_NewtoMeter" Motor_BEV
 SG_ EM2_Status_DrzEingriff  : 127|2@1+ (1.000000,0.000000) [0.000000|3.000000] "" ICAS1_Gateway Motor_BEV
 SG_ EM2_Mom_DrzEingriff  : 129|11@1+ (1.000000,-1023.000000) [-1023.000000|1022.000000] "Unit_NewtoMeter" Motor_BEV

BO_ 2463978674 EM2_02: 32 LE2
 SG_ EM2_Status_Spgfreiheit  : 12|2@1+ (1.000000,0.000000) [0.000000|3.000000] "" Motor_BEV
 SG_ EM2_Status_EoHVL  : 14|2@1+ (1.000000,0.000000) [0.000000|3.000000] "" Motor_BEV
 SG_ EM2_Max_LeistungMech_Sockel  : 16|13@1+ (200.000000,-819000.000000) [-819000.000000|818800.000000] "Unit_Watt" Vector__XXX
 SG_ EM2_Max_Moment_Sockel  : 29|11@1+ (1.000000,-1023.000000) [-1023.000000|1022.000000] "Unit_NewtoMeter" Vector__XXX
 SG_ EM2_Min_LeistungMech_Sockel  : 40|13@1+ (200.000000,-819000.000000) [-819000.000000|818800.000000] "Unit_Watt" Vector__XXX
 SG_ EM2_Min_Moment_Sockel  : 53|11@1+ (1.000000,-1023.000000) [-1023.000000|1022.000000] "Unit_NewtoMeter" Vector__XXX
 SG_ EM2_PerfInd_MaxLeistung  : 64|10@1+ (0.200000,0.000000) [0.000000|200.000000] "Unit_PerCent" Motor_BEV
 SG_ EM2_PerfInd_MaxMoment  : 74|10@1+ (0.200000,0.000000) [0.000000|200.000000] "Unit_PerCent" Motor_BEV
 SG_ EM2_AnlernenElMotor_Anf  : 84|1@1+ (1.000000,0.000000) [0.000000|1.000000] "" Motor_BEV
 SG_ EM2_OBD_Lampe_Anf  : 85|1@1+ (1.000000,0.000000) [0.000000|1.000000] "" Motor_BEV
 SG_ EM2_Generator_Moment  : 86|10@1+ (1.000000,0.000000) [0.000000|1021.000000] "Unit_NewtoMeter" Motor_BEV
 SG_ EM2_PerfInd_Temperatur  : 96|8@1+ (0.800000,0.000000) [0.000000|200.000000] "Unit_PerCent" Motor_BEV
 SG_ EM2_MaxZul_Drehzahl  : 104|8@1+ (80.000000,0.000000) [0.000000|20240.000000] "Unit_RevPerMinute" Motor_BEV
 SG_ EM2_Min_Moment_Gesamt  : 112|11@1+ (1.000000,-1023.000000) [-1023.000000|1022.000000] "Unit_NewtoMeter" Motor_BEV
 SG_ EM2_Fehlerlampe_Anf  : 123|1@1+ (1.000000,0.000000) [0.000000|1.000000] "" Motor_BEV
 SG_ EM2_Max_Moment_Gesamt  : 124|11@1+ (1.000000,-1023.000000) [-1023.000000|1022.000000] "Unit_NewtoMeter" Motor_BEV
 SG_ EM2_Warnlampe_Anf  : 135|1@1+ (1.000000,0.000000) [0.000000|1.000000] "" Motor_BEV
 SG_ EM2_Rekuperation  : 136|15@1+ (10.000000,0.000000) [0.000000|327670.000000] "Unit_WattSecond" Motor_BEV
 SG_ EM2_Rekuperation_Ueberlauf  : 151|1@1+ (1.000000,0.000000) [0.000000|1.000000] "" Motor_BEV
 SG_ EM2_Verbrauch  : 152|15@1+ (10.000000,0.000000) [0.000000|327670.000000] "Unit_WattSecond" Motor_BEV
 SG_ EM2_Verbrauch_Ueberlauf  : 167|1@1+ (1.000000,0.000000) [0.000000|1.000000] "" Motor_BEV
 SG_ EM2_Fehler_AE  : 168|1@1+ (1.000000,0.000000) [0.000000|1.000000] "" Motor_BEV
 SG_ EM2_Fehler_Leistungsred  : 169|1@1+ (1.000000,0.000000) [0.000000|1.000000] "" Motor_BEV
 SG_ EM2_Fehler_ElAntriebFreilauf  : 170|1@1+ (1.000000,0.000000) [0.000000|1.000000] "" Motor_BEV
 SG_ EM2_PWR_SollVolumenstrom  : 171|6@1+ (0.500000,0.000000) [0.000000|30.500000] "Unit_LiterPerMinut" Motor_BEV

BO_ 2589283660 EM2_03: 8 LE2
 SG_ EM2_SollVorlauftemperatur  : 0|8@1+ (0.500000,-40.000000) [-40.000000|86.500000] "Unit_DegreCelsi" Motor_BEV
 SG_ EM2_Temperatur_EM  : 13|9@1+ (1.000000,-40.000000) [-40.000000|469.000000] "Unit_DegreCelsi" ICAS1_Gateway Motor_BEV
 SG_ EM2_EM_SollVolumenstrom  : 22|6@1+ (0.500000,0.000000) [0.000000|30.500000] "Unit_LiterPerMinut" Motor_BEV
 SG_ EM2_Max_MechLeistung_nom  : 28|12@1+ (200.000000,0.000000) [0.000000|818600.000000] "Unit_Watt" Motor_BEV
 SG_ EM2_Max_Moment_nom  : 40|10@1+ (1.000000,0.000000) [0.000000|1021.000000] "Unit_NewtoMeter" Motor_BEV
 SG_ EM2_Temperatur_PWR  : 56|8@1+ (1.000000,-40.000000) [-40.000000|213.000000] "Unit_DegreCelsi" ICAS1_Gateway Motor_BEV

BO_ 199 EM2_HYB_13: 8 LE2
 SG_ EM2_Freigabe_Info_WFS  : 12|1@1+ (1.000000,0.000000) [0.000000|1.000000] "" ICAS1_Gateway Motor_BEV
 SG_ EM2_Sperr_Info_WFS  : 13|1@1+ (1.000000,0.000000) [0.000000|1.000000] "" ICAS1_Gateway Motor_BEV
 SG_ EM2_AR_aktiv  : 14|1@1+ (1.000000,0.000000) [0.000000|1.000000] "" ICAS1_Gateway
 SG_ EM2_Eta_Sys  : 15|9@1+ (0.200000,0.000000) [0.000000|101.800000] "Unit_PerCent" ICAS1_Gateway
 SG_ EM2_IstStrom  : 24|11@1+ (1.000000,-1023.000000) [-1023.000000|1022.000000] "Unit_Amper" ICAS1_Gateway
 SG_ EM2_Fehler_ElAntriebFreilauf_Anf  : 35|1@1+ (1.000000,0.000000) [0.000000|1.000000] "" ICAS1_Gateway
 SG_ EM2_Abregelung_Temperatur  : 36|1@1+ (1.000000,0.000000) [0.000000|1.000000] "" ICAS1_Gateway
 SG_ EM2_AnlernenElMotor_Anf  : 43|1@1+ (1.000000,0.000000) [0.000000|1.000000] "" ICAS1_Gateway
 SG_ EM2_Freigabe_Verfallsinfo_WFS  : 55|1@1+ (1.000000,0.000000) [0.000000|1.000000] "" ICAS1_Gateway Motor_BEV
 SG_ EM2_Parken_WFS_Status  : 56|2@1+ (1.000000,0.000000) [0.000000|3.000000] "" ICAS1_Gateway
 SG_ EM2_HV_betriebsbereit  : 58|1@1+ (1.000000,0.000000) [0.000000|1.000000] "" ICAS1_Gateway

BO_ 2527679713 EM2_HYB_27: 8 LE2
 SG_ EM2_RtmWarnKommunikation  : 12|3@1+ (1.000000,0.000000) [0.000000|7.000000] "" Vector__XXX
 SG_ EM2_RtmWarnUeberdrehzahl  : 15|3@1+ (1.000000,0.000000) [0.000000|7.000000] "" ICAS1_Gateway
 SG_ EM2_RtmWarnUeberstrom  : 18|3@1+ (1.000000,0.000000) [0.000000|7.000000] "" ICAS1_Gateway
 SG_ EM2_RtmWarnTempEM  : 21|3@1+ (1.000000,0.000000) [0.000000|7.000000] "" ICAS1_Gateway
 SG_ EM2_RtmWarnTempPWR  : 24|3@1+ (1.000000,0.000000) [0.000000|7.000000] "" ICAS1_Gateway

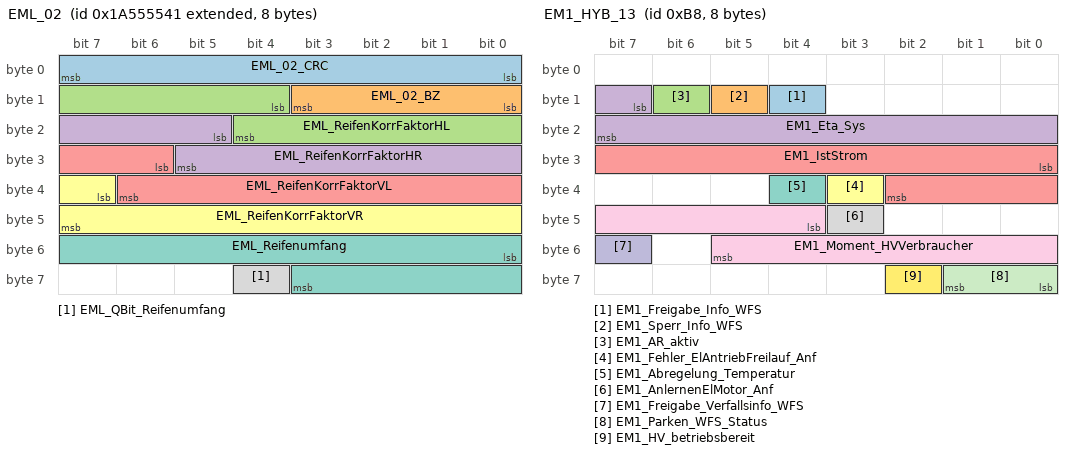
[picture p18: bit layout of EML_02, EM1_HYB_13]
BO_ 2589283649 EML_02: 8 ICAS1_Gateway
 SG_ EML_02_CRC  : 0|8@1+ (1.000000,0.000000) [0.000000|255.000000] "" Vector__XXX
 SG_ EML_02_BZ  : 8|4@1+ (1.000000,0.000000) [0.000000|15.000000] "" Vector__XXX
 SG_ EML_ReifenKorrFaktorHL  : 12|9@1+ (0.000488,0.850000) [0.850000|1.098535] "" Vector__XXX
 SG_ EML_ReifenKorrFaktorHR  : 21|9@1+ (0.000488,0.850000) [0.850000|1.098535] "" Vector__XXX
 SG_ EML_ReifenKorrFaktorVL  : 30|9@1+ (0.000488,0.850000) [0.850000|1.098535] "" Vector__XXX
 SG_ EML_ReifenKorrFaktorVR  : 39|9@1+ (0.000488,0.850000) [0.850000|1.098535] "" Vector__XXX
 SG_ EML_Reifenumfang  : 48|12@1+ (1.000000,0.000000) [0.000000|4095.000000] "Unit_MilliMeter" Motor_BEV
 SG_ EML_QBit_Reifenumfang  : 60|1@1+ (1.000000,0.000000) [0.000000|1.000000] "" Motor_BEV

BO_ 608 EML_07: 8 ICAS1_Gateway
 SG_ EML_AnzeigeGeschw  : 54|10@1+ (0.320000,0.000000) [0.000000|325.120000] "Unit_KiloMeterPerHour" Motor_BEV

BO_ 2589283751 Entfernungen_01: 8 ICAS1_KommunikationsServer
 SG_ KBI_Kilometerstand_HiRes_meter  : 32|32@1+ (1.000000,0.000000) [0.000000|4294967295.000000] "Unit_Meter" Motor_BEV

BO_ 2527679687 EPS_ASM_01: 8 ICAS1_Gateway
 SG_ EPS_ASM_Ereignis  : 0|8@1+ (1.000000,0.000000) [1.000000|254.000000] "Unit_None" Airbag
 SG_ EPS_ASM_Zeitstempel  : 8|8@1+ (0.080000,0.000000) [0.000000|20.320000] "Unit_None" Airbag
 SG_ EPS_ASM_Data_1  : 16|8@1+ (1.000000,0.000000) [0.000000|255.000000] "Unit_None" Airbag
 SG_ EPS_ASM_Data_2  : 24|8@1+ (1.000000,0.000000) [0.000000|255.000000] "Unit_None" Airbag
 SG_ EPS_ASM_Data_3  : 32|8@1+ (1.000000,0.000000) [0.000000|255.000000] "Unit_None" Airbag
 SG_ EPS_ASM_Data_4  : 40|8@1+ (1.000000,0.000000) [0.000000|255.000000] "Unit_None" Airbag
 SG_ EPS_ASM_Data_5  : 48|8@1+ (1.000000,0.000000) [0.000000|255.000000] "Unit_None" Airbag
 SG_ EPS_ASM_Data_6  : 56|8@1+ (1.000000,0.000000) [0.000000|255.000000] "Unit_None" Airbag

BO_ 258 ESC_50: 48 ICAS1_Gateway
 SG_ ESC_50_CRC  : 0|8@1+ (1.000000,0.000000) [0.000000|255.000000] "" Motor_BEV
 SG_ ESC_50_BZ  : 8|4@1+ (1.000000,0.000000) [0.000000|15.000000] "" Motor_BEV
 SG_ ESP_QBit_Gierrate  : 12|1@1+ (1.000000,0.000000) [0.000000|1.000000] "" Motor_BEV
 SG_ ESP_QBit_Laengsbeschl  : 13|1@1+ (1.000000,0.000000) [0.000000|1.000000] "" Motor_BEV
 SG_ ESP_QBit_Querb  : 14|1@1+ (1.000000,0.000000) [0.000000|1.000000] "" Motor_BEV
 SG_ ESP_Querbeschleunigung  : 16|8@1+ (0.010000,-1.270000) [-1.270000|1.270000] "Unit_ForceOfGravi" Airbag Motor_BEV
 SG_ ESP_Laengsbeschl  : 24|10@1+ (0.031250,-16.000000) [-16.000000|15.906250] "Unit_MeterPerSeconSquar" Airbag Motor_BEV
 SG_ ESC_Motorstartverzoegerung  : 34|1@1+ (1.000000,0.000000) [0.000000|1.000000] "" Vector__XXX
 SG_ ESC_SeitenwindAssistent_Eingriff  : 35|1@1+ (1.000000,0.000000) [0.000000|1.000000] "" Vector__XXX
 SG_ ESP_Anschleppstart_Freigabe  : 36|2@1+ (1.000000,0.000000) [0.000000|3.000000] "" Vector__XXX
 SG_ ESC_Unterdruckmangel_erkannt  : 38|1@1+ (1.000000,0.000000) [0.000000|1.000000] "" Vector__XXX
 SG_ ESP_Gierrate  : 40|14@1+ (0.010000,0.000000) [0.000000|163.820000] "Unit_DegreOfArcPerSecon" Airbag Motor_BEV
 SG_ ESP_VZ_Gierrate  : 54|1@1+ (1.000000,0.000000) [0.000000|1.000000] "" Airbag Motor_BEV
 SG_ ESP_Notbremsanzeige  : 55|1@1+ (1.000000,0.000000) [0.000000|1.000000] "" Vector__XXX
 SG_ ESP_SpannungsAnf  : 56|1@1+ (1.000000,0.000000) [0.000000|1.000000] "" Vector__XXX
 SG_ ESP_PLA_Abbruch  : 57|3@1+ (1.000000,0.000000) [0.000000|7.000000] "" Vector__XXX
 SG_ ESP_Status_ESP_PLA  : 60|4@1+ (1.000000,0.000000) [0.000000|15.000000] "" Vector__XXX
 SG_ ESP_QBit_Bremsdruck  : 76|1@1+ (1.000000,0.000000) [0.000000|1.000000] "" Airbag Motor_BEV
 SG_ ESP_QBit_Fahrer_bremst  : 77|1@1+ (1.000000,0.000000) [0.000000|1.000000] "" Vector__XXX
 SG_ ESP_Schwelle_Unterdruck  : 78|2@1+ (1.000000,0.000000) [0.000000|3.000000] "" Vector__XXX
 SG_ ESP_Bremsdruck  : 80|10@1+ (0.300000,-30.000000) [-30.000000|276.600000] "Unit_Bar" Motor_BEV
 SG_ ESP_Fahrer_bremst  : 90|1@1+ (1.000000,0.000000) [0.000000|1.000000] "" Vector__XXX
 SG_ ESP_Verz_TSK_aktiv  : 91|1@1+ (1.000000,0.000000) [0.000000|1.000000] "" Vector__XXX
 SG_ ESP_Lenkeingriff_ADS  : 92|1@1+ (1.000000,0.000000) [0.000000|1.000000] "" Vector__XXX
 SG_ ESP_Konsistenz_TSK  : 93|1@1+ (1.000000,0.000000) [0.000000|1.000000] "" Vector__XXX
 SG_ ESP_Bremsruck_AWV2  : 94|1@1+ (1.000000,0.000000) [0.000000|1.000000] "" Vector__XXX
 SG_ ESP_Konsistenz_AWV2  : 95|1@1+ (1.000000,0.000000) [0.000000|1.000000] "" Vector__XXX
 SG_ ECD_Fehler  : 96|1@1+ (1.000000,0.000000) [0.000000|1.000000] "" Vector__XXX
 SG_ ECD_nicht_verfuegbar  : 97|1@1+ (1.000000,0.000000) [0.000000|1.000000] "" Vector__XXX
 SG_ ESP_Status_Bremsentemp  : 98|1@1+ (1.000000,0.000000) [0.000000|1.000000] "" Vector__XXX
 SG_ ESP_Autohold_Standby  : 99|1@1+ (1.000000,0.000000) [0.000000|1.000000] "" Vector__XXX
 SG_ ESP_HDC_Standby  : 100|1@1+ (1.000000,0.000000) [0.000000|1.000000] "" Vector__XXX
 SG_ ESP_HBA_aktiv  : 101|1@1+ (1.000000,0.000000) [0.000000|1.000000] "" Vector__XXX
 SG_ ESP_Prefill_ausgeloest  : 102|1@1+ (1.000000,0.000000) [0.000000|1.000000] "" Vector__XXX
 SG_ ESP_Rueckwaertsfahrt_erkannt  : 103|1@1+ (1.000000,0.000000) [0.000000|1.000000] "" Vector__XXX
 SG_ ESP_Status_Anfahrhilfe  : 104|1@1+ (1.000000,0.000000) [0.000000|1.000000] "" Vector__XXX
 SG_ ESP_HDC_aktiv  : 105|1@1+ (1.000000,0.000000) [0.000000|1.000000] "" Vector__XXX
 SG_ ESP_StartStopp_Info  : 106|2@1+ (1.000000,0.000000) [0.000000|3.000000] "" Vector__XXX
 SG_ ESP_Eingr_HL  : 108|1@1+ (1.000000,0.000000) [0.000000|1.000000] "" Vector__XXX
 SG_ ESP_Eingr_HR  : 109|1@1+ (1.000000,0.000000) [0.000000|1.000000] "" Vector__XXX
 SG_ ESP_Eingr_VL  : 110|1@1+ (1.000000,0.000000) [0.000000|1.000000] "" Vector__XXX
 SG_ ESP_Eingr_VR  : 111|1@1+ (1.000000,0.000000) [0.000000|1.000000] "" Vector__XXX
 SG_ ESP_BKV_Unterdruck  : 112|8@1+ (4.000000,0.000000) [4.000000|1012.000000] "Unit_MilliBar" Vector__XXX
 SG_ ESP_Autohold_aktiv  : 120|1@1+ (1.000000,0.000000) [0.000000|1.000000] "" Vector__XXX
 SG_ ESP_FStatus_Anfahrhilfe  : 121|1@1+ (1.000000,0.000000) [0.000000|1.000000] "" Vector__XXX
 SG_ ESP_Verz_EPB_aktiv  : 122|1@1+ (1.000000,0.000000) [0.000000|1.000000] "" Vector__XXX
 SG_ ECD_Bremslicht  : 123|1@1+ (1.000000,0.000000) [0.000000|1.000000] "" Motor_BEV
 SG_ ESP_Verzoeg_EPB_verf  : 124|1@1+ (1.000000,0.000000) [0.000000|1.000000] "" Vector__XXX
 SG_ ESP_Status_Bremsdruck  : 125|1@1+ (1.000000,0.000000) [0.000000|1.000000] "" Vector__XXX
 SG_ ESP_Anforderung_EPB  : 126|2@1+ (1.000000,0.000000) [0.000000|3.000000] "" Vector__XXX
 SG_ ESP_ANB_CM_Rueckk_Umsetz  : 140|1@1+ (1.000000,0.000000) [0.000000|1.000000] "" Vector__XXX
 SG_ ESP_Konsistenz_ACC_Botschaft  : 141|1@1+ (1.000000,0.000000) [0.000000|1.000000] "" Vector__XXX
 SG_ ESP_Stillstandsphase_erschoepft  : 142|1@1+ (1.000000,0.000000) [0.000000|1.000000] "" Vector__XXX
 SG_ ESP_ZT_Rueckk_Umsetz  : 143|1@1+ (1.000000,0.000000) [0.000000|1.000000] "" Vector__XXX
 SG_ ESP_Tuerkontakt_Fahrertuer  : 144|1@1+ (1.000000,0.000000) [0.000000|1.000000] "" Vector__XXX
 SG_ ESP_Abrutschen_Stillstand  : 146|1@1+ (1.000000,0.000000) [0.000000|1.000000] "" Vector__XXX
 SG_ ESP_Fahrer_tritt_ZBR_Schw  : 147|1@1+ (1.000000,0.000000) [0.000000|1.000000] "" Vector__XXX
 SG_ ESP_QBit_v_ref  : 169|1@1+ (1.000000,0.000000) [0.000000|1.000000] "" Vector__XXX
 SG_ ESP_v_ref_Fahrtrichtung  : 170|2@1+ (1.000000,0.000000) [0.000000|3.000000] "" Motor_BEV
 SG_ ESC_Bremsdruckgradient  : 172|8@1+ (10.000000,0.000000) [0.000000|2500.000000] "Unit_BarPerSecon" Vector__XXX
 SG_ ESP_v_ref  : 180|12@1+ (0.125000,0.000000) [0.000000|511.500000] "Unit_KiloMeterPerHour" Airbag Motor_BEV
 SG_ ESC_Hydr_Fkt_aktiv  : 223|2@1+ (1.000000,0.000000) [0.000000|3.000000] "" Vector__XXX
 SG_ ESC_QBit_Fahrerbremswunsch  : 225|1@1+ (1.000000,0.000000) [0.000000|1.000000] "" Motor_BEV
 SG_ ESC_Fahrerbremswunsch  : 226|10@1+ (0.300000,-30.000000) [-30.000000|276.600000] "Unit_Bar" Motor_BEV
 SG_ ESCGeneratorSollMoment  : 236|12@1+ (3.000000,-12279.000000) [-12279.000000|0.000000] "" Motor_BEV
 SG_ ESC_Raddruck_max  : 248|8@1+ (1.000000,0.000000) [0.000000|250.000000] "Unit_Bar" Vector__XXX
 SG_ EPB_QBit_Pedalweg_Kuppl  : 269|1@1+ (1.000000,0.000000) [0.000000|1.000000] "" Vector__XXX
 SG_ EPB_Freig_Verzoeg_Anf  : 271|1@1+ (1.000000,0.000000) [0.000000|1.000000] "" Vector__XXX
 SG_ EPB_Verzoeg_Anf  : 272|8@1+ (0.048000,-7.968000) [-7.968000|4.224000] "Unit_MeterPerSeconSquar" Vector__XXX
 SG_ EPB_Pedalweg_Kuppl  : 288|8@1+ (0.400000,0.000000) [8.000000|92.000000] "Unit_PerCent" Vector__XXX
 SG_ EPB_DAA_Randbed_erf  : 305|1@1+ (1.000000,0.000000) [0.000000|1.000000] "" Vector__XXX
 SG_ EPB_Fehlerstatus_02  : 306|2@1+ (1.000000,0.000000) [0.000000|3.000000] "" Vector__XXX
 SG_ EPB_Schalterposition  : 308|2@1+ (1.000000,0.000000) [0.000000|3.000000] "" Airbag
 SG_ EPB_QBit_Schalterpos  : 310|1@1+ (1.000000,0.000000) [0.000000|1.000000] "" Vector__XXX
 SG_ EPB_Spannkraft  : 312|5@1+ (1.000000,0.000000) [0.000000|29.000000] "Unit_KiloNewto" Vector__XXX
 SG_ EPB_Status_02  : 317|3@1+ (1.000000,0.000000) [0.000000|7.000000] "" Motor_BEV
 SG_ EPB_Status  : 320|2@1+ (1.000000,0.000000) [0.000000|3.000000] "" Vector__XXX
 SG_ ESP_Status_Bremsentemp_02  : 322|2@1+ (1.000000,0.000000) [0.000000|3.000000] "" Motor_BEV

BU_:  Airbag BAP_Tester ICAS1_Gateway ICAS1_KommunikationsServer LE1 LE2 Motor_BEV Schaltbetaetigung

BO_ 192 EM1_01: 32 LE1
 SG_ EM1_01_CRC  : 0|8@1+ (1.000000,0.000000) [0.000000|255.000000] "" ICAS1_Gateway Motor_BEV
 SG_ EM1_01_BZ  : 8|4@1+ (1.000000,0.000000) [0.000000|15.000000] "" ICAS1_Gateway Motor_BEV
 SG_ EM1_Istmodus  : 12|4@1+ (1.000000,0.000000) [0.000000|15.000000] "" ICAS1_Gateway Motor_BEV
 SG_ EM1_IstMoment  : 16|12@1+ (0.500000,-1023.000000) [-1023.000000|1023.500000] "Unit_NewtoMeter" ICAS1_Gateway Motor_BEV
 SG_ EM1_Moment_AR_Eingriff  : 28|12@1+ (0.500000,-1023.000000) [-1023.000000|1023.500000] "Unit_NewtoMeter" ICAS1_Gateway Motor_BEV
 SG_ EM1_IstDrehzahl  : 40|15@1+ (1.000000,-10000.000000) [-10000.000000|22765.000000] "Unit_MinutInver" ICAS1_Gateway Motor_BEV
 SG_ EM1_AR_aktiv  : 55|1@1+ (1.000000,0.000000) [0.000000|1.000000] "" ICAS1_Gateway Motor_BEV
 SG_ EM1_IstSpannung  : 56|12@1+ (0.250000,0.000000) [0.000000|1023.250000] "Unit_Volt" ICAS1_Gateway Motor_BEV
 SG_ EM1_Strom_HV  : 68|12@1+ (0.500000,-1023.000000) [-1023.000000|1023.500000] "Unit_Amper" ICAS1_Gateway Motor_BEV
 SG_ EM1_Max_Moment  : 80|11@1+ (1.000000,-1023.000000) [-1023.000000|1022.000000] "Unit_NewtoMeter" ICAS1_Gateway Motor_BEV
 SG_ EM1_ErwGrenzen_aktiv  : 91|1@1+ (1.000000,0.000000) [0.000000|1.000000] "" ICAS1_Gateway Motor_BEV
 SG_ EM1_Min_Moment  : 92|11@1+ (1.000000,-1023.000000) [-1023.000000|1022.000000] "Unit_NewtoMeter" ICAS1_Gateway Motor_BEV
 SG_ EM1_Fehler_ElAntriebAbschaltung  : 103|1@1+ (1.000000,0.000000) [0.000000|1.000000] "" ICAS1_Gateway Motor_BEV
 SG_ EM1_Max_Moment_Lim  : 104|11@1+ (1.000000,-1023.000000) [-1023.000000|1022.000000] "Unit_NewtoMeter" ICAS1_Gateway Motor_BEV
 SG_ EM1_Fehler_Notabschaltung  : 115|1@1+ (1.000000,0.000000) [0.000000|1.000000] "" ICAS1_Gateway Motor_BEV
 SG_ EM1_Min_Moment_Lim  : 116|11@1+ (1.000000,-1023.000000) [-1023.000000|1022.000000] "Unit_NewtoMeter" ICAS1_Gateway Motor_BEV
 SG_ EM1_Status_DrzEingriff  : 127|2@1+ (1.000000,0.000000) [0.000000|3.000000] "" ICAS1_Gateway Motor_BEV
 SG_ EM1_Mom_DrzEingriff  : 129|11@1+ (1.000000,-1023.000000) [-1023.000000|1022.000000] "Unit_NewtoMeter" ICAS1_Gateway Motor_BEV

BO_ 2463978673 EM1_02: 32 LE1
 SG_ EM1_Status_Spgfreiheit  : 12|2@1+ (1.000000,0.000000) [0.000000|3.000000] "" Motor_BEV
 SG_ EM1_Status_EoHVL  : 14|2@1+ (1.000000,0.000000) [0.000000|3.000000] "" Motor_BEV
 SG_ EM1_Max_LeistungMech_Sockel  : 16|13@1+ (200.000000,-819000.000000) [-819000.000000|818800.000000] "Unit_Watt" Vector__XXX
 SG_ EM1_Max_Moment_Sockel  : 29|11@1+ (1.000000,-1023.000000) [-1023.000000|1022.000000] "Unit_NewtoMeter" Vector__XXX
 SG_ EM1_Min_LeistungMech_Sockel  : 40|13@1+ (200.000000,-819000.000000) [-819000.000000|818800.000000] "Unit_Watt" Vector__XXX
 SG_ EM1_Min_Moment_Sockel  : 53|11@1+ (1.000000,-1023.000000) [-1023.000000|1022.000000] "Unit_NewtoMeter" Vector__XXX
 SG_ EM1_PerfInd_MaxLeistung  : 64|10@1+ (0.200000,0.000000) [0.000000|200.000000] "Unit_PerCent" Motor_BEV
 SG_ EM1_PerfInd_MaxMoment  : 74|10@1+ (0.200000,0.000000) [0.000000|200.000000] "Unit_PerCent" Motor_BEV
 SG_ EM1_AnlernenElMotor_Anf  : 84|1@1+ (1.000000,0.000000) [0.000000|1.000000] "" Motor_BEV
 SG_ EM1_OBD_Lampe_Anf  : 85|1@1+ (1.000000,0.000000) [0.000000|1.000000] "" Motor_BEV
 SG_ EM1_Generator_Moment  : 86|10@1+ (1.000000,0.000000) [0.000000|1021.000000] "Unit_NewtoMeter" Motor_BEV
 SG_ EM1_PerfInd_Temperatur  : 96|8@1+ (0.800000,0.000000) [0.000000|200.000000] "Unit_PerCent" Motor_BEV
 SG_ EM1_MaxZul_Drehzahl  : 104|8@1+ (80.000000,0.000000) [0.000000|20240.000000] "Unit_RevPerMinute" Motor_BEV
 SG_ EM1_Min_Moment_Gesamt  : 112|11@1+ (1.000000,-1023.000000) [-1023.000000|1022.000000] "Unit_NewtoMeter" Motor_BEV
 SG_ EM1_Fehlerlampe_Anf  : 123|1@1+ (1.000000,0.000000) [0.000000|1.000000] "" Motor_BEV
 SG_ EM1_Max_Moment_Gesamt  : 124|11@1+ (1.000000,-1023.000000) [-1023.000000|1022.000000] "Unit_NewtoMeter" Motor_BEV
 SG_ EM1_Warnlampe_Anf  : 135|1@1+ (1.000000,0.000000) [0.000000|1.000000] "" Motor_BEV
 SG_ EM1_Rekuperation  : 136|15@1+ (10.000000,0.000000) [0.000000|327670.000000] "Unit_WattSecond" Motor_BEV
 SG_ EM1_Rekuperation_Ueberlauf  : 151|1@1+ (1.000000,0.000000) [0.000000|1.000000] "" Motor_BEV
 SG_ EM1_Verbrauch  : 152|15@1+ (10.000000,0.000000) [0.000000|327670.000000] "Unit_WattSecond" Motor_BEV
 SG_ EM1_Verbrauch_Ueberlauf  : 167|1@1+ (1.000000,0.000000) [0.000000|1.000000] "" Motor_BEV
 SG_ EM1_Fehler_AE  : 168|1@1+ (1.000000,0.000000) [0.000000|1.000000] "" Motor_BEV
 SG_ EM1_Fehler_Leistungsred  : 169|1@1+ (1.000000,0.000000) [0.000000|1.000000] "" Motor_BEV
 SG_ EM1_Fehler_ElAntriebFreilauf  : 170|1@1+ (1.000000,0.000000) [0.000000|1.000000] "" Motor_BEV
 SG_ EM1_PWR_SollVolumenstrom  : 171|6@1+ (0.500000,0.000000) [0.000000|30.500000] "Unit_LiterPerMinut" Motor_BEV

BO_ 2589283657 EM1_03: 8 LE1
 SG_ EM1_SollVorlauftemperatur  : 0|8@1+ (0.500000,-40.000000) [-40.000000|86.500000] "Unit_DegreCelsi" Motor_BEV
 SG_ EM1_Temperatur_EM  : 13|9@1+ (1.000000,-40.000000) [-40.000000|469.000000] "Unit_DegreCelsi" ICAS1_Gateway Motor_BEV
 SG_ EM1_EM_SollVolumenstrom  : 22|6@1+ (0.500000,0.000000) [0.000000|30.500000] "Unit_LiterPerMinut" Motor_BEV
 SG_ EM1_Max_MechLeistung_nom  : 28|12@1+ (200.000000,0.000000) [0.000000|818600.000000] "Unit_Watt" Motor_BEV
 SG_ EM1_Max_Moment_nom  : 40|10@1+ (1.000000,0.000000) [0.000000|1021.000000] "Unit_NewtoMeter" Motor_BEV
 SG_ EM1_Temperatur_PWR  : 56|8@1+ (1.000000,-40.000000) [-40.000000|213.000000] "Unit_DegreCelsi" ICAS1_Gateway Motor_BEV

BO_ 184 EM1_HYB_13: 8 LE1
 SG_ EM1_Freigabe_Info_WFS  : 12|1@1+ (1.000000,0.000000) [0.000000|1.000000] "" ICAS1_Gateway Motor_BEV
 SG_ EM1_Sperr_Info_WFS  : 13|1@1+ (1.000000,0.000000) [0.000000|1.000000] "" ICAS1_Gateway Motor_BEV
 SG_ EM1_AR_aktiv  : 14|1@1+ (1.000000,0.000000) [0.000000|1.000000] "" ICAS1_Gateway
 SG_ EM1_Eta_Sys  : 15|9@1+ (0.200000,0.000000) [0.000000|101.800000] "Unit_PerCent" ICAS1_Gateway
 SG_ EM1_IstStrom  : 24|11@1+ (1.000000,-1023.000000) [-1023.000000|1022.000000] "Unit_Amper" ICAS1_Gateway
 SG_ EM1_Fehler_ElAntriebFreilauf_Anf  : 35|1@1+ (1.000000,0.000000) [0.000000|1.000000] "" ICAS1_Gateway
 SG_ EM1_Abregelung_Temperatur  : 36|1@1+ (1.000000,0.000000) [0.000000|1.000000] "" ICAS1_Gateway
 SG_ EM1_AnlernenElMotor_Anf  : 43|1@1+ (1.000000,0.000000) [0.000000|1.000000] "" ICAS1_Gateway
 SG_ EM1_Moment_HVVerbraucher  : 44|10@1+ (1.000000,-511.000000) [-511.000000|511.000000] "Unit_NewtoMeter" ICAS1_Gateway
 SG_ EM1_Freigabe_Verfallsinfo_WFS  : 55|1@1+ (1.000000,0.000000) [0.000000|1.000000] "" ICAS1_Gateway Motor_BEV
 SG_ EM1_Parken_WFS_Status  : 56|2@1+ (1.000000,0.000000) [0.000000|3.000000] "" ICAS1_Gateway
 SG_ EM1_HV_betriebsbereit  : 58|1@1+ (1.000000,0.000000) [0.000000|1.000000] "" ICAS1_Gateway

BO_ 2527679712 EM1_HYB_27: 8 LE1
 SG_ EM1_RtmWarnKommunikation  : 12|3@1+ (1.000000,0.000000) [0.000000|7.000000] "" Vector__XXX
 SG_ EM1_RtmWarnUeberdrehzahl  : 15|3@1+ (1.000000,0.000000) [0.000000|7.000000] "" ICAS1_Gateway
 SG_ EM1_RtmWarnUeberstrom  : 18|3@1+ (1.000000,0.000000) [0.000000|7.000000] "" ICAS1_Gateway
 SG_ EM1_RtmWarnTempEM  : 21|3@1+ (1.000000,0.000000) [0.000000|7.000000] "" ICAS1_Gateway
 SG_ EM1_RtmWarnTempPWR  : 24|3@1+ (1.000000,0.000000) [0.000000|7.000000] "" ICAS1_Gateway

BO_ 193 EM2_01: 32 LE2
 SG_ EM2_01_CRC  : 0|8@1+ (1.000000,0.000000) [0.000000|255.000000] "" Motor_BEV
 SG_ EM2_01_BZ  : 8|4@1+ (1.000000,0.000000) [0.000000|15.000000] "" Motor_BEV
 SG_ EM2_Istmodus  : 12|4@1+ (1.000000,0.000000) [0.000000|15.000000] "" ICAS1_Gateway Motor_BEV
 SG_ EM2_IstMoment  : 16|12@1+ (0.500000,-1023.000000) [-1023.000000|1023.500000] "Unit_NewtoMeter" ICAS1_Gateway Motor_BEV
 SG_ EM2_Moment_AR_Eingriff  : 28|12@1+ (0.500000,-1023.000000) [-1023.000000|1023.500000] "Unit_NewtoMeter" Motor_BEV
 SG_ EM2_IstDrehzahl  : 40|15@1+ (1.000000,-10000.000000) [-10000.000000|22765.000000] "Unit_MinutInver" ICAS1_Gateway Motor_BEV
 SG_ EM2_AR_aktiv  : 55|1@1+ (1.000000,0.000000) [0.000000|1.000000] "" Motor_BEV
 SG_ EM2_IstSpannung  : 56|12@1+ (0.250000,0.000000) [0.000000|1023.250000] "Unit_Volt" ICAS1_Gateway Motor_BEV
 SG_ EM2_Strom_HV  : 68|12@1+ (0.500000,-1023.000000) [-1023.000000|1023.500000] "Unit_Amper" ICAS1_Gateway Motor_BEV
 SG_ EM2_Max_Moment  : 80|11@1+ (1.000000,-1023.000000) [-1023.000000|1022.000000] "Unit_NewtoMeter" Motor_BEV
 SG_ EM2_ErwGrenzen_aktiv  : 91|1@1+ (1.000000,0.000000) [0.000000|1.000000] "" Motor_BEV
 SG_ EM2_Min_Moment  : 92|11@1+ (1.000000,-1023.000000) [-1023.000000|1022.000000] "Unit_NewtoMeter" Motor_BEV
 SG_ EM2_Fehler_ElAntriebAbschaltung  : 103|1@1+ (1.000000,0.000000) [0.000000|1.000000] "" Motor_BEV
 SG_ EM2_Max_Moment_Lim  : 104|11@1+ (1.000000,-1023.000000) [-1023.000000|1022.000000] "Unit_NewtoMeter" Motor_BEV
 SG_ EM2_Fehler_Notabschaltung  : 115|1@1+ (1.000000,0.000000) [0.000000|1.000000] "" ICAS1_Gateway Motor_BEV
 SG_ EM2_Min_Moment_Lim  : 116|11@1+ (1.000000,-1023.000000) [-1023.000000|1022.000000] "Unit_NewtoMeter" Motor_BEV
 SG_ EM2_Status_DrzEingriff  : 127|2@1+ (1.000000,0.000000) [0.000000|3.000000] "" ICAS1_Gateway Motor_BEV
 SG_ EM2_Mom_DrzEingriff  : 129|11@1+ (1.000000,-1023.000000) [-1023.000000|1022.000000] "Unit_NewtoMeter" Motor_BEV

BO_ 2463978674 EM2_02: 32 LE2
 SG_ EM2_Status_Spgfreiheit  : 12|2@1+ (1.000000,0.000000) [0.000000|3.000000] "" Motor_BEV
 SG_ EM2_Status_EoHVL  : 14|2@1+ (1.000000,0.000000) [0.000000|3.000000] "" Motor_BEV
 SG_ EM2_Max_LeistungMech_Sockel  : 16|13@1+ (200.000000,-819000.000000) [-819000.000000|818800.000000] "Unit_Watt" Vector__XXX
 SG_ EM2_Max_Moment_Sockel  : 29|11@1+ (1.000000,-1023.000000) [-1023.000000|1022.000000] "Unit_NewtoMeter" Vector__XXX
 SG_ EM2_Min_LeistungMech_Sockel  : 40|13@1+ (200.000000,-819000.000000) [-819000.000000|818800.000000] "Unit_Watt" Vector__XXX
 SG_ EM2_Min_Moment_Sockel  : 53|11@1+ (1.000000,-1023.000000) [-1023.000000|1022.000000] "Unit_NewtoMeter" Vector__XXX
 SG_ EM2_PerfInd_MaxLeistung  : 64|10@1+ (0.200000,0.000000) [0.000000|200.000000] "Unit_PerCent" Motor_BEV
 SG_ EM2_PerfInd_MaxMoment  : 74|10@1+ (0.200000,0.000000) [0.000000|200.000000] "Unit_PerCent" Motor_BEV
 SG_ EM2_AnlernenElMotor_Anf  : 84|1@1+ (1.000000,0.000000) [0.000000|1.000000] "" Motor_BEV
 SG_ EM2_OBD_Lampe_Anf  : 85|1@1+ (1.000000,0.000000) [0.000000|1.000000] "" Motor_BEV
 SG_ EM2_Generator_Moment  : 86|10@1+ (1.000000,0.000000) [0.000000|1021.000000] "Unit_NewtoMeter" Motor_BEV
 SG_ EM2_PerfInd_Temperatur  : 96|8@1+ (0.800000,0.000000) [0.000000|200.000000] "Unit_PerCent" Motor_BEV
 SG_ EM2_MaxZul_Drehzahl  : 104|8@1+ (80.000000,0.000000) [0.000000|20240.000000] "Unit_RevPerMinute" Motor_BEV
 SG_ EM2_Min_Moment_Gesamt  : 112|11@1+ (1.000000,-1023.000000) [-1023.000000|1022.000000] "Unit_NewtoMeter" Motor_BEV
 SG_ EM2_Fehlerlampe_Anf  : 123|1@1+ (1.000000,0.000000) [0.000000|1.000000] "" Motor_BEV
 SG_ EM2_Max_Moment_Gesamt  : 124|11@1+ (1.000000,-1023.000000) [-1023.000000|1022.000000] "Unit_NewtoMeter" Motor_BEV
 SG_ EM2_Warnlampe_Anf  : 135|1@1+ (1.000000,0.000000) [0.000000|1.000000] "" Motor_BEV
 SG_ EM2_Rekuperation  : 136|15@1+ (10.000000,0.000000) [0.000000|327670.000000] "Unit_WattSecond" Motor_BEV
 SG_ EM2_Rekuperation_Ueberlauf  : 151|1@1+ (1.000000,0.000000) [0.000000|1.000000] "" Motor_BEV
 SG_ EM2_Verbrauch  : 152|15@1+ (10.000000,0.000000) [0.000000|327670.000000] "Unit_WattSecond" Motor_BEV
 SG_ EM2_Verbrauch_Ueberlauf  : 167|1@1+ (1.000000,0.000000) [0.000000|1.000000] "" Motor_BEV
 SG_ EM2_Fehler_AE  : 168|1@1+ (1.000000,0.000000) [0.000000|1.000000] "" Motor_BEV
 SG_ EM2_Fehler_Leistungsred  : 169|1@1+ (1.000000,0.000000) [0.000000|1.000000] "" Motor_BEV
 SG_ EM2_Fehler_ElAntriebFreilauf  : 170|1@1+ (1.000000,0.000000) [0.000000|1.000000] "" Motor_BEV
 SG_ EM2_PWR_SollVolumenstrom  : 171|6@1+ (0.500000,0.000000) [0.000000|30.500000] "Unit_LiterPerMinut" Motor_BEV

BO_ 2589283660 EM2_03: 8 LE2
 SG_ EM2_SollVorlauftemperatur  : 0|8@1+ (0.500000,-40.000000) [-40.000000|86.500000] "Unit_DegreCelsi" Motor_BEV
 SG_ EM2_Temperatur_EM  : 13|9@1+ (1.000000,-40.000000) [-40.000000|469.000000] "Unit_DegreCelsi" ICAS1_Gateway Motor_BEV
 SG_ EM2_EM_SollVolumenstrom  : 22|6@1+ (0.500000,0.000000) [0.000000|30.500000] "Unit_LiterPerMinut" Motor_BEV
 SG_ EM2_Max_MechLeistung_nom  : 28|12@1+ (200.000000,0.000000) [0.000000|818600.000000] "Unit_Watt" Motor_BEV
 SG_ EM2_Max_Moment_nom  : 40|10@1+ (1.000000,0.000000) [0.000000|1021.000000] "Unit_NewtoMeter" Motor_BEV
 SG_ EM2_Temperatur_PWR  : 56|8@1+ (1.000000,-40.000000) [-40.000000|213.000000] "Unit_DegreCelsi" ICAS1_Gateway Motor_BEV

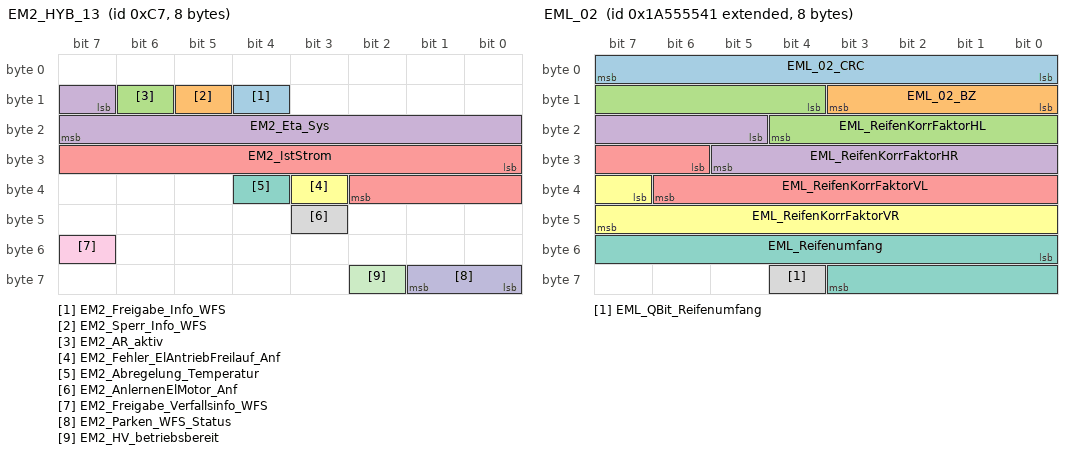
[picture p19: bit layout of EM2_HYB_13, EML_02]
BO_ 199 EM2_HYB_13: 8 LE2
 SG_ EM2_Freigabe_Info_WFS  : 12|1@1+ (1.000000,0.000000) [0.000000|1.000000] "" ICAS1_Gateway Motor_BEV
 SG_ EM2_Sperr_Info_WFS  : 13|1@1+ (1.000000,0.000000) [0.000000|1.000000] "" ICAS1_Gateway Motor_BEV
 SG_ EM2_AR_aktiv  : 14|1@1+ (1.000000,0.000000) [0.000000|1.000000] "" ICAS1_Gateway
 SG_ EM2_Eta_Sys  : 15|9@1+ (0.200000,0.000000) [0.000000|101.800000] "Unit_PerCent" ICAS1_Gateway
 SG_ EM2_IstStrom  : 24|11@1+ (1.000000,-1023.000000) [-1023.000000|1022.000000] "Unit_Amper" ICAS1_Gateway
 SG_ EM2_Fehler_ElAntriebFreilauf_Anf  : 35|1@1+ (1.000000,0.000000) [0.000000|1.000000] "" ICAS1_Gateway
 SG_ EM2_Abregelung_Temperatur  : 36|1@1+ (1.000000,0.000000) [0.000000|1.000000] "" ICAS1_Gateway
 SG_ EM2_AnlernenElMotor_Anf  : 43|1@1+ (1.000000,0.000000) [0.000000|1.000000] "" ICAS1_Gateway
 SG_ EM2_Freigabe_Verfallsinfo_WFS  : 55|1@1+ (1.000000,0.000000) [0.000000|1.000000] "" ICAS1_Gateway Motor_BEV
 SG_ EM2_Parken_WFS_Status  : 56|2@1+ (1.000000,0.000000) [0.000000|3.000000] "" ICAS1_Gateway
 SG_ EM2_HV_betriebsbereit  : 58|1@1+ (1.000000,0.000000) [0.000000|1.000000] "" ICAS1_Gateway

BO_ 2527679713 EM2_HYB_27: 8 LE2
 SG_ EM2_RtmWarnKommunikation  : 12|3@1+ (1.000000,0.000000) [0.000000|7.000000] "" Vector__XXX
 SG_ EM2_RtmWarnUeberdrehzahl  : 15|3@1+ (1.000000,0.000000) [0.000000|7.000000] "" ICAS1_Gateway
 SG_ EM2_RtmWarnUeberstrom  : 18|3@1+ (1.000000,0.000000) [0.000000|7.000000] "" ICAS1_Gateway
 SG_ EM2_RtmWarnTempEM  : 21|3@1+ (1.000000,0.000000) [0.000000|7.000000] "" ICAS1_Gateway
 SG_ EM2_RtmWarnTempPWR  : 24|3@1+ (1.000000,0.000000) [0.000000|7.000000] "" ICAS1_Gateway

BO_ 2589283649 EML_02: 8 ICAS1_Gateway
 SG_ EML_02_CRC  : 0|8@1+ (1.000000,0.000000) [0.000000|255.000000] "" Vector__XXX
 SG_ EML_02_BZ  : 8|4@1+ (1.000000,0.000000) [0.000000|15.000000] "" Vector__XXX
 SG_ EML_ReifenKorrFaktorHL  : 12|9@1+ (0.000488,0.850000) [0.850000|1.098535] "" Vector__XXX
 SG_ EML_ReifenKorrFaktorHR  : 21|9@1+ (0.000488,0.850000) [0.850000|1.098535] "" Vector__XXX
 SG_ EML_ReifenKorrFaktorVL  : 30|9@1+ (0.000488,0.850000) [0.850000|1.098535] "" Vector__XXX
 SG_ EML_ReifenKorrFaktorVR  : 39|9@1+ (0.000488,0.850000) [0.850000|1.098535] "" Vector__XXX
 SG_ EML_Reifenumfang  : 48|12@1+ (1.000000,0.000000) [0.000000|4095.000000] "Unit_MilliMeter" Motor_BEV
 SG_ EML_QBit_Reifenumfang  : 60|1@1+ (1.000000,0.000000) [0.000000|1.000000] "" Motor_BEV

BO_ 608 EML_07: 8 ICAS1_Gateway
 SG_ EML_AnzeigeGeschw  : 54|10@1+ (0.320000,0.000000) [0.000000|325.120000] "Unit_KiloMeterPerHour" Motor_BEV

BO_ 2589283751 Entfernungen_01: 8 ICAS1_KommunikationsServer
 SG_ KBI_Kilometerstand_HiRes_meter  : 32|32@1+ (1.000000,0.000000) [0.000000|4294967295.000000] "Unit_Meter" Motor_BEV

BO_ 2527679687 EPS_ASM_01: 8 ICAS1_Gateway
 SG_ EPS_ASM_Ereignis  : 0|8@1+ (1.000000,0.000000) [1.000000|254.000000] "Unit_None" Airbag
 SG_ EPS_ASM_Zeitstempel  : 8|8@1+ (0.080000,0.000000) [0.000000|20.320000] "Unit_None" Airbag
 SG_ EPS_ASM_Data_1  : 16|8@1+ (1.000000,0.000000) [0.000000|255.000000] "Unit_None" Airbag
 SG_ EPS_ASM_Data_2  : 24|8@1+ (1.000000,0.000000) [0.000000|255.000000] "Unit_None" Airbag
 SG_ EPS_ASM_Data_3  : 32|8@1+ (1.000000,0.000000) [0.000000|255.000000] "Unit_None" Airbag
 SG_ EPS_ASM_Data_4  : 40|8@1+ (1.000000,0.000000) [0.000000|255.000000] "Unit_None" Airbag
 SG_ EPS_ASM_Data_5  : 48|8@1+ (1.000000,0.000000) [0.000000|255.000000] "Unit_None" Airbag
 SG_ EPS_ASM_Data_6  : 56|8@1+ (1.000000,0.000000) [0.000000|255.000000] "Unit_None" Airbag

BO_ 258 ESC_50: 48 ICAS1_Gateway
 SG_ ESC_50_CRC  : 0|8@1+ (1.000000,0.000000) [0.000000|255.000000] "" Motor_BEV
 SG_ ESC_50_BZ  : 8|4@1+ (1.000000,0.000000) [0.000000|15.000000] "" Motor_BEV
 SG_ ESP_QBit_Gierrate  : 12|1@1+ (1.000000,0.000000) [0.000000|1.000000] "" Motor_BEV
 SG_ ESP_QBit_Laengsbeschl  : 13|1@1+ (1.000000,0.000000) [0.000000|1.000000] "" Motor_BEV
 SG_ ESP_QBit_Querb  : 14|1@1+ (1.000000,0.000000) [0.000000|1.000000] "" Motor_BEV
 SG_ ESP_Querbeschleunigung  : 16|8@1+ (0.010000,-1.270000) [-1.270000|1.270000] "Unit_ForceOfGravi" Airbag Motor_BEV
 SG_ ESP_Laengsbeschl  : 24|10@1+ (0.031250,-16.000000) [-16.000000|15.906250] "Unit_MeterPerSeconSquar" Airbag Motor_BEV
 SG_ ESC_Motorstartverzoegerung  : 34|1@1+ (1.000000,0.000000) [0.000000|1.000000] "" Vector__XXX
 SG_ ESC_SeitenwindAssistent_Eingriff  : 35|1@1+ (1.000000,0.000000) [0.000000|1.000000] "" Vector__XXX
 SG_ ESP_Anschleppstart_Freigabe  : 36|2@1+ (1.000000,0.000000) [0.000000|3.000000] "" Vector__XXX
 SG_ ESC_Unterdruckmangel_erkannt  : 38|1@1+ (1.000000,0.000000) [0.000000|1.000000] "" Vector__XXX
 SG_ ESP_Gierrate  : 40|14@1+ (0.010000,0.000000) [0.000000|163.820000] "Unit_DegreOfArcPerSecon" Airbag Motor_BEV
 SG_ ESP_VZ_Gierrate  : 54|1@1+ (1.000000,0.000000) [0.000000|1.000000] "" Airbag Motor_BEV
 SG_ ESP_Notbremsanzeige  : 55|1@1+ (1.000000,0.000000) [0.000000|1.000000] "" Vector__XXX
 SG_ ESP_SpannungsAnf  : 56|1@1+ (1.000000,0.000000) [0.000000|1.000000] "" Vector__XXX
 SG_ ESP_PLA_Abbruch  : 57|3@1+ (1.000000,0.000000) [0.000000|7.000000] "" Vector__XXX
 SG_ ESP_Status_ESP_PLA  : 60|4@1+ (1.000000,0.000000) [0.000000|15.000000] "" Vector__XXX
 SG_ ESP_QBit_Bremsdruck  : 76|1@1+ (1.000000,0.000000) [0.000000|1.000000] "" Airbag Motor_BEV
 SG_ ESP_QBit_Fahrer_bremst  : 77|1@1+ (1.000000,0.000000) [0.000000|1.000000] "" Vector__XXX
 SG_ ESP_Schwelle_Unterdruck  : 78|2@1+ (1.000000,0.000000) [0.000000|3.000000] "" Vector__XXX
 SG_ ESP_Bremsdruck  : 80|10@1+ (0.300000,-30.000000) [-30.000000|276.600000] "Unit_Bar" Motor_BEV
 SG_ ESP_Fahrer_bremst  : 90|1@1+ (1.000000,0.000000) [0.000000|1.000000] "" Vector__XXX
 SG_ ESP_Verz_TSK_aktiv  : 91|1@1+ (1.000000,0.000000) [0.000000|1.000000] "" Vector__XXX
 SG_ ESP_Lenkeingriff_ADS  : 92|1@1+ (1.000000,0.000000) [0.000000|1.000000] "" Vector__XXX
 SG_ ESP_Konsistenz_TSK  : 93|1@1+ (1.000000,0.000000) [0.000000|1.000000] "" Vector__XXX
 SG_ ESP_Bremsruck_AWV2  : 94|1@1+ (1.000000,0.000000) [0.000000|1.000000] "" Vector__XXX
 SG_ ESP_Konsistenz_AWV2  : 95|1@1+ (1.000000,0.000000) [0.000000|1.000000] "" Vector__XXX
 SG_ ECD_Fehler  : 96|1@1+ (1.000000,0.000000) [0.000000|1.000000] "" Vector__XXX
 SG_ ECD_nicht_verfuegbar  : 97|1@1+ (1.000000,0.000000) [0.000000|1.000000] "" Vector__XXX
 SG_ ESP_Status_Bremsentemp  : 98|1@1+ (1.000000,0.000000) [0.000000|1.000000] "" Vector__XXX
 SG_ ESP_Autohold_Standby  : 99|1@1+ (1.000000,0.000000) [0.000000|1.000000] "" Vector__XXX
 SG_ ESP_HDC_Standby  : 100|1@1+ (1.000000,0.000000) [0.000000|1.000000] "" Vector__XXX
 SG_ ESP_HBA_aktiv  : 101|1@1+ (1.000000,0.000000) [0.000000|1.000000] "" Vector__XXX
 SG_ ESP_Prefill_ausgeloest  : 102|1@1+ (1.000000,0.000000) [0.000000|1.000000] "" Vector__XXX
 SG_ ESP_Rueckwaertsfahrt_erkannt  : 103|1@1+ (1.000000,0.000000) [0.000000|1.000000] "" Vector__XXX
 SG_ ESP_Status_Anfahrhilfe  : 104|1@1+ (1.000000,0.000000) [0.000000|1.000000] "" Vector__XXX
 SG_ ESP_HDC_aktiv  : 105|1@1+ (1.000000,0.000000) [0.000000|1.000000] "" Vector__XXX
 SG_ ESP_StartStopp_Info  : 106|2@1+ (1.000000,0.000000) [0.000000|3.000000] "" Vector__XXX
 SG_ ESP_Eingr_HL  : 108|1@1+ (1.000000,0.000000) [0.000000|1.000000] "" Vector__XXX
 SG_ ESP_Eingr_HR  : 109|1@1+ (1.000000,0.000000) [0.000000|1.000000] "" Vector__XXX
 SG_ ESP_Eingr_VL  : 110|1@1+ (1.000000,0.000000) [0.000000|1.000000] "" Vector__XXX
 SG_ ESP_Eingr_VR  : 111|1@1+ (1.000000,0.000000) [0.000000|1.000000] "" Vector__XXX
 SG_ ESP_BKV_Unterdruck  : 112|8@1+ (4.000000,0.000000) [4.000000|1012.000000] "Unit_MilliBar" Vector__XXX
 SG_ ESP_Autohold_aktiv  : 120|1@1+ (1.000000,0.000000) [0.000000|1.000000] "" Vector__XXX
 SG_ ESP_FStatus_Anfahrhilfe  : 121|1@1+ (1.000000,0.000000) [0.000000|1.000000] "" Vector__XXX
 SG_ ESP_Verz_EPB_aktiv  : 122|1@1+ (1.000000,0.000000) [0.000000|1.000000] "" Vector__XXX
 SG_ ECD_Bremslicht  : 123|1@1+ (1.000000,0.000000) [0.000000|1.000000] "" Motor_BEV
 SG_ ESP_Verzoeg_EPB_verf  : 124|1@1+ (1.000000,0.000000) [0.000000|1.000000] "" Vector__XXX
 SG_ ESP_Status_Bremsdruck  : 125|1@1+ (1.000000,0.000000) [0.000000|1.000000] "" Vector__XXX
 SG_ ESP_Anforderung_EPB  : 126|2@1+ (1.000000,0.000000) [0.000000|3.000000] "" Vector__XXX
 SG_ ESP_ANB_CM_Rueckk_Umsetz  : 140|1@1+ (1.000000,0.000000) [0.000000|1.000000] "" Vector__XXX
 SG_ ESP_Konsistenz_ACC_Botschaft  : 141|1@1+ (1.000000,0.000000) [0.000000|1.000000] "" Vector__XXX
 SG_ ESP_Stillstandsphase_erschoepft  : 142|1@1+ (1.000000,0.000000) [0.000000|1.000000] "" Vector__XXX
 SG_ ESP_ZT_Rueckk_Umsetz  : 143|1@1+ (1.000000,0.000000) [0.000000|1.000000] "" Vector__XXX
 SG_ ESP_Tuerkontakt_Fahrertuer  : 144|1@1+ (1.000000,0.000000) [0.000000|1.000000] "" Vector__XXX
 SG_ ESP_Abrutschen_Stillstand  : 146|1@1+ (1.000000,0.000000) [0.000000|1.000000] "" Vector__XXX
 SG_ ESP_Fahrer_tritt_ZBR_Schw  : 147|1@1+ (1.000000,0.000000) [0.000000|1.000000] "" Vector__XXX
 SG_ ESP_QBit_v_ref  : 169|1@1+ (1.000000,0.000000) [0.000000|1.000000] "" Vector__XXX
 SG_ ESP_v_ref_Fahrtrichtung  : 170|2@1+ (1.000000,0.000000) [0.000000|3.000000] "" Motor_BEV
 SG_ ESC_Bremsdruckgradient  : 172|8@1+ (10.000000,0.000000) [0.000000|2500.000000] "Unit_BarPerSecon" Vector__XXX
 SG_ ESP_v_ref  : 180|12@1+ (0.125000,0.000000) [0.000000|511.500000] "Unit_KiloMeterPerHour" Airbag Motor_BEV
 SG_ ESC_Hydr_Fkt_aktiv  : 223|2@1+ (1.000000,0.000000) [0.000000|3.000000] "" Vector__XXX
 SG_ ESC_QBit_Fahrerbremswunsch  : 225|1@1+ (1.000000,0.000000) [0.000000|1.000000] "" Motor_BEV
 SG_ ESC_Fahrerbremswunsch  : 226|10@1+ (0.300000,-30.000000) [-30.000000|276.600000] "Unit_Bar" Motor_BEV
 SG_ ESCGeneratorSollMoment  : 236|12@1+ (3.000000,-12279.000000) [-12279.000000|0.000000] "" Motor_BEV
 SG_ ESC_Raddruck_max  : 248|8@1+ (1.000000,0.000000) [0.000000|250.000000] "Unit_Bar" Vector__XXX
 SG_ EPB_QBit_Pedalweg_Kuppl  : 269|1@1+ (1.000000,0.000000) [0.000000|1.000000] "" Vector__XXX
 SG_ EPB_Freig_Verzoeg_Anf  : 271|1@1+ (1.000000,0.000000) [0.000000|1.000000] "" Vector__XXX
 SG_ EPB_Verzoeg_Anf  : 272|8@1+ (0.048000,-7.968000) [-7.968000|4.224000] "Unit_MeterPerSeconSquar" Vector__XXX
 SG_ EPB_Pedalweg_Kuppl  : 288|8@1+ (0.400000,0.000000) [8.000000|92.000000] "Unit_PerCent" Vector__XXX
 SG_ EPB_DAA_Randbed_erf  : 305|1@1+ (1.000000,0.000000) [0.000000|1.000000] "" Vector__XXX
 SG_ EPB_Fehlerstatus_02  : 306|2@1+ (1.000000,0.000000) [0.000000|3.000000] "" Vector__XXX
 SG_ EPB_Schalterposition  : 308|2@1+ (1.000000,0.000000) [0.000000|3.000000] "" Airbag
 SG_ EPB_QBit_Schalterpos  : 310|1@1+ (1.000000,0.000000) [0.000000|1.000000] "" Vector__XXX
 SG_ EPB_Spannkraft  : 312|5@1+ (1.000000,0.000000) [0.000000|29.000000] "Unit_KiloNewto" Vector__XXX
 SG_ EPB_Status_02  : 317|3@1+ (1.000000,0.000000) [0.000000|7.000000] "" Motor_BEV
 SG_ EPB_Status  : 320|2@1+ (1.000000,0.000000) [0.000000|3.000000] "" Vector__XXX
 SG_ ESP_Status_Bremsentemp_02  : 322|2@1+ (1.000000,0.000000) [0.000000|3.000000] "" Motor_BEV
